VERSION "dbc-export 1 2026.26.6.5"

NS_ :

BS_:

BU_: ADSP APSB CMP DAS EPAS3P GTW OCS1P PTC RCM TCU TCU2 TRCM UDS UI UIS VCLEFT

BO_ 1297 RCM_alertLog: 8 RCM
 SG_ RCM_alertID M : 0|10@1+ (1,0) [0|1023] "" Vector__XXX
 SG_ RCM_a117_eventDriveOrientation m117 : 14|1@1+ (1,0) [0|1] "" Vector__XXX
 SG_ RCM_a117_imuZaccelChnlMonitTmp m117 : 16|1@1+ (1,0) [0|1] "" Vector__XXX
 SG_ RCM_a117_imuZaccelChnlMonitPerm m117 : 17|1@1+ (1,0) [0|1] "" Vector__XXX
 SG_ RCM_a117_eventIDFsignal m117 : 25|1@1+ (1,0) [0|1] "" Vector__XXX
 SG_ RCM_a117_eventFrontLeftSeatbelt m117 : 26|1@1+ (1,0) [0|1] "" Vector__XXX
 SG_ RCM_a117_eventFrontRightSeatbelt m117 : 27|1@1+ (1,0) [0|1] "" Vector__XXX
 SG_ RCM_a117_eventVehicleSpeed m117 : 28|12@1+ (0.08,-40) [-40|287.6] "kph" Vector__XXX
 SG_ RCM_a117_eventSteeringAngle m117 : 45|14@0+ (0.1,-819.2) [-819.2|819.1] "deg" Vector__XXX
 SG_ RCM_a117_eventDriverBrakeApply m117 : 46|2@1+ (1,0) [0|2] "" Vector__XXX
 SG_ RCM_a117_eventAccelPedalPos m117 : 56|8@1+ (0.4,0) [0|101.6] "%" Vector__XXX
 SG_ RCM_a118_eventArmStatus m118 : 11|1@1+ (1,0) [0|1] "" Vector__XXX
 SG_ RCM_a118_eventFactoryMode m118 : 12|1@1+ (1,0) [0|1] "" Vector__XXX
 SG_ RCM_a118_eventDiagEnabled m118 : 13|1@1+ (1,0) [0|1] "" Vector__XXX
 SG_ RCM_a118_eventDriveOrientation m118 : 14|1@1+ (1,0) [0|1] "" Vector__XXX
 SG_ RCM_a118_imuInPlaneSnsrMonitTmp m118 : 16|1@1+ (1,0) [0|1] "" Vector__XXX
 SG_ RCM_a118_imuInPlaneSnsrMonitPerm m118 : 17|1@1+ (1,0) [0|1] "" Vector__XXX
 SG_ RCM_a118_eventIDFsignal m118 : 25|1@1+ (1,0) [0|1] "" Vector__XXX
 SG_ RCM_a118_eventFrontLeftSeatbelt m118 : 26|1@1+ (1,0) [0|1] "" Vector__XXX
 SG_ RCM_a118_eventFrontRightSeatbelt m118 : 27|1@1+ (1,0) [0|1] "" Vector__XXX
 SG_ RCM_a118_eventVehicleSpeed m118 : 28|12@1+ (0.08,-40) [-40|287.6] "kph" Vector__XXX
 SG_ RCM_a118_eventSteeringAngle m118 : 45|14@0+ (0.1,-819.2) [-819.2|819.1] "deg" Vector__XXX
 SG_ RCM_a118_eventDriverBrakeApply m118 : 46|2@1+ (1,0) [0|2] "" Vector__XXX
 SG_ RCM_a118_eventAccelPedalPos m118 : 56|8@1+ (0.4,0) [0|101.6] "%" Vector__XXX

BO_ 881 RCM_alertMatrix: 8 RCM
 SG_ RCM_matrixIndex M : 0|4@1+ (1,0) [0|15] "" Vector__XXX
 SG_ RCM_a000_crashDetected m0 : 4|1@1+ (1,0) [0|1] "" Vector__XXX
 SG_ RCM_a001_nearDeploy m0 : 5|1@1+ (1,0) [0|1] "" Vector__XXX
 SG_ RCM_a002_airbagsNotArmed m0 : 6|1@1+ (1,0) [0|1] "" Vector__XXX
 SG_ RCM_a003_warningIndicator m0 : 7|1@1+ (1,0) [0|1] "" Vector__XXX
 SG_ RCM_a004_internalFault m0 : 8|1@1+ (1,0) [0|1] "" Vector__XXX
 SG_ RCM_a005_crcError m0 : 9|1@1+ (1,0) [0|1] "" Vector__XXX
 SG_ RCM_a006_batteryVoltageRange m0 : 10|1@1+ (1,0) [0|1] "" Vector__XXX
 SG_ RCM_a007_powerSupplyExternal m0 : 11|1@1+ (1,0) [0|1] "" Vector__XXX
 SG_ RCM_a008_powerSupplyInternal m0 : 12|1@1+ (1,0) [0|1] "" Vector__XXX
 SG_ RCM_a009_reprogramLimit m0 : 13|1@1+ (1,0) [0|1] "" Vector__XXX
 SG_ RCM_a010_scmDisabled m0 : 14|1@1+ (1,0) [0|1] "" Vector__XXX
 SG_ RCM_a011_eepromDataLocked m0 : 15|1@1+ (1,0) [0|1] "" Vector__XXX
 SG_ RCM_a012_vinStorage m0 : 16|1@1+ (1,0) [0|1] "" Vector__XXX
 SG_ RCM_a013_driverOrientation m0 : 17|1@1+ (1,0) [0|1] "" Vector__XXX
 SG_ RCM_a014_driverABStage1 m0 : 18|1@1+ (1,0) [0|1] "" Vector__XXX
 SG_ RCM_a015_driverABStage2 m0 : 19|1@1+ (1,0) [0|1] "" Vector__XXX
 SG_ RCM_a016_passABStage1 m0 : 20|1@1+ (1,0) [0|1] "" Vector__XXX
 SG_ RCM_a017_passABStage2 m0 : 21|1@1+ (1,0) [0|1] "" Vector__XXX
 SG_ RCM_a018_passengerActiveVent m0 : 22|1@1+ (1,0) [0|1] "" Vector__XXX
 SG_ RCM_a019_pretenShldrFrontLeft m0 : 23|1@1+ (1,0) [0|1] "" Vector__XXX
 SG_ RCM_a020_pretenShldFrontRight m0 : 24|1@1+ (1,0) [0|1] "" Vector__XXX
 SG_ RCM_a021_pretenLapFrontLeft m0 : 25|1@1+ (1,0) [0|1] "" Vector__XXX
 SG_ RCM_a022_pretenLapFrontRight m0 : 26|1@1+ (1,0) [0|1] "" Vector__XXX
 SG_ RCM_a023_loadLimiterLeftSide m0 : 27|1@1+ (1,0) [0|1] "" Vector__XXX
 SG_ RCM_a024_loadLimiterRightSide m0 : 28|1@1+ (1,0) [0|1] "" Vector__XXX
 SG_ RCM_a025_kneeABDriver m0 : 29|1@1+ (1,0) [0|1] "" Vector__XXX
 SG_ RCM_a026_kneeABFrontPassenger m0 : 30|1@1+ (1,0) [0|1] "" Vector__XXX
 SG_ RCM_a027_sideAB1stRowLeft m0 : 31|1@1+ (1,0) [0|1] "" Vector__XXX
 SG_ RCM_a028_sideAB1stRowRight m0 : 32|1@1+ (1,0) [0|1] "" Vector__XXX
 SG_ RCM_a029_driverABActiveVent m0 : 33|1@1+ (1,0) [0|1] "" Vector__XXX
 SG_ RCM_a030_farSideInboardAirbag m0 : 34|1@1+ (1,0) [0|1] "" Vector__XXX
 SG_ RCM_a031_frontCenterAirbag m0 : 35|1@1+ (1,0) [0|1] "" Vector__XXX
 SG_ RCM_a032_curtainABLeft m0 : 36|1@1+ (1,0) [0|1] "" Vector__XXX
 SG_ RCM_a033_curtainABRight m0 : 37|1@1+ (1,0) [0|1] "" Vector__XXX
 SG_ RCM_a034_preten2ndRowLeft m0 : 38|1@1+ (1,0) [0|1] "" Vector__XXX
 SG_ RCM_a035_preten2ndRowRight m0 : 39|1@1+ (1,0) [0|1] "" Vector__XXX
 SG_ RCM_a036_curAB2ndRowLeft m0 : 40|1@1+ (1,0) [0|1] "" Vector__XXX
 SG_ RCM_a037_curAB2ndRowRight m0 : 41|1@1+ (1,0) [0|1] "" Vector__XXX
 SG_ RCM_a038_unusedA m0 : 42|1@1+ (1,0) [0|1] "" Vector__XXX
 SG_ RCM_a039_unusedB m0 : 43|1@1+ (1,0) [0|1] "" Vector__XXX
 SG_ RCM_a040_hoodActuatorRight m0 : 44|1@1+ (1,0) [0|1] "" Vector__XXX
 SG_ RCM_a041_hoodActuatorLeft m0 : 45|1@1+ (1,0) [0|1] "" Vector__XXX
 SG_ RCM_a042_ens1Line m0 : 46|1@1+ (1,0) [0|1] "" Vector__XXX
 SG_ RCM_a043_ens2Line m0 : 47|1@1+ (1,0) [0|1] "" Vector__XXX
 SG_ RCM_a044_upFrontSensorLeft m0 : 48|1@1+ (1,0) [0|1] "" Vector__XXX
 SG_ RCM_a045_upFrontSensorRight m0 : 49|1@1+ (1,0) [0|1] "" Vector__XXX
 SG_ RCM_a046_sideAccelBPillarLeft m0 : 50|1@1+ (1,0) [0|1] "" Vector__XXX
 SG_ RCM_a047_sideAccelBPillarRight m0 : 51|1@1+ (1,0) [0|1] "" Vector__XXX
 SG_ RCM_a048_sideAccelCPillarLeft m0 : 52|1@1+ (1,0) [0|1] "" Vector__XXX
 SG_ RCM_a049_sideAccelCPillarRight m0 : 53|1@1+ (1,0) [0|1] "" Vector__XXX
 SG_ RCM_a050_upFrontSensorCenter m0 : 54|1@1+ (1,0) [0|1] "" Vector__XXX
 SG_ RCM_a051_pressureFrontLftDoor m0 : 55|1@1+ (1,0) [0|1] "" Vector__XXX
 SG_ RCM_a052_pressureFrontRtDoor m0 : 56|1@1+ (1,0) [0|1] "" Vector__XXX
 SG_ RCM_a053_pressurePedProLeft m0 : 57|1@1+ (1,0) [0|1] "" Vector__XXX
 SG_ RCM_a054_pressurePedProRight m0 : 58|1@1+ (1,0) [0|1] "" Vector__XXX
 SG_ RCM_a055_inertialMeasurement m0 : 59|1@1+ (1,0) [0|1] "" Vector__XXX
 SG_ RCM_a056_passengerFrontOCS m0 : 60|1@1+ (1,0) [0|1] "" Vector__XXX
 SG_ RCM_a057_driverOCS m0 : 61|1@1+ (1,0) [0|1] "" Vector__XXX
 SG_ RCM_a058_buckle1stRowLeft m0 : 62|1@1+ (1,0) [0|1] "" Vector__XXX
 SG_ RCM_a059_buckle1stRowRight m0 : 63|1@1+ (1,0) [0|1] "" Vector__XXX
 SG_ RCM_a060_stpsLeft m1 : 4|1@1+ (1,0) [0|1] "" Vector__XXX
 SG_ RCM_a061_stpsRight m1 : 5|1@1+ (1,0) [0|1] "" Vector__XXX
 SG_ RCM_a062_alrSwitch m1 : 6|1@1+ (1,0) [0|1] "" Vector__XXX
 SG_ RCM_a063_sbsw2ndRowRight m1 : 7|1@1+ (1,0) [0|1] "" Vector__XXX
 SG_ RCM_a064_hardwareCodingPin1 m1 : 8|1@1+ (1,0) [0|1] "" Vector__XXX
 SG_ RCM_a065_driverOrientConfigPin m1 : 9|1@1+ (1,0) [0|1] "" Vector__XXX
 SG_ RCM_a066_seatBackSw2ndRowLeft m1 : 10|1@1+ (1,0) [0|1] "" Vector__XXX
 SG_ RCM_a067_comCANInitFailure m1 : 11|1@1+ (1,0) [0|1] "" Vector__XXX
 SG_ RCM_a068_comChassisBusOff m1 : 12|1@1+ (1,0) [0|1] "" Vector__XXX
 SG_ RCM_a069_comCHCANPH7 m1 : 13|1@1+ (1,0) [0|1] "" Vector__XXX
 SG_ RCM_a070_comCHCANPH8 m1 : 14|1@1+ (1,0) [0|1] "" Vector__XXX
 SG_ RCM_a071_comCHCANPH9 m1 : 15|1@1+ (1,0) [0|1] "" Vector__XXX
 SG_ RCM_a072_comUnused m1 : 16|1@1+ (1,0) [0|1] "" Vector__XXX
 SG_ RCM_a073_comCHCANPH4 m1 : 17|1@1+ (1,0) [0|1] "" Vector__XXX
 SG_ RCM_a074_comCHCANPH5 m1 : 18|1@1+ (1,0) [0|1] "" Vector__XXX
 SG_ RCM_a075_comCHCANPH6 m1 : 19|1@1+ (1,0) [0|1] "" Vector__XXX
 SG_ RCM_a076_comEPBLStatus m1 : 20|1@1+ (1,0) [0|1] "" Vector__XXX
 SG_ RCM_a077_comEPBRStatus m1 : 21|1@1+ (1,0) [0|1] "" Vector__XXX
 SG_ RCM_a078_comOCS1PStatus m1 : 22|1@1+ (1,0) [0|1] "" Vector__XXX
 SG_ RCM_a079_comOCS1DStatus m1 : 23|1@1+ (1,0) [0|1] "" Vector__XXX
 SG_ RCM_a080_comGTWACS m1 : 24|1@1+ (1,0) [0|1] "" Vector__XXX
 SG_ RCM_a081_comVCFRONTLVPwr m1 : 25|1@1+ (1,0) [0|1] "" Vector__XXX
 SG_ RCM_a082_comUIodo m1 : 26|1@1+ (1,0) [0|1] "" Vector__XXX
 SG_ RCM_a083_comGTWCarState m1 : 27|1@1+ (1,0) [0|1] "" Vector__XXX
 SG_ RCM_a084_comTPMSStatus m1 : 28|1@1+ (1,0) [0|1] "" Vector__XXX
 SG_ RCM_a085_comGTWCarConfig m1 : 29|1@1+ (1,0) [0|1] "" Vector__XXX
 SG_ RCM_a086_comVINMIA m1 : 30|1@1+ (1,0) [0|1] "" Vector__XXX
 SG_ RCM_a087_comCANSilent m1 : 31|1@1+ (1,0) [0|1] "" Vector__XXX
 SG_ RCM_a088_comCHCANPH2 m1 : 32|1@1+ (1,0) [0|1] "" Vector__XXX
 SG_ RCM_a089_comCHCANPH3 m1 : 33|1@1+ (1,0) [0|1] "" Vector__XXX
 SG_ RCM_a090_comPartyBusOff m1 : 34|1@1+ (1,0) [0|1] "" Vector__XXX
 SG_ RCM_a091_comEPAS3PsysStatus m1 : 35|1@1+ (1,0) [0|1] "" Vector__XXX
 SG_ RCM_a092_comDASISF m1 : 36|1@1+ (1,0) [0|1] "" Vector__XXX
 SG_ RCM_a093_comVCLEFTStatus m1 : 37|1@1+ (1,0) [0|1] "" Vector__XXX
 SG_ RCM_a094_comVCRIGHTStatus m1 : 38|1@1+ (1,0) [0|1] "" Vector__XXX
 SG_ RCM_a095_comESPstatus m1 : 39|1@1+ (1,0) [0|1] "" Vector__XXX
 SG_ RCM_a096_comESPwheelSpeeds m1 : 40|1@1+ (1,0) [0|1] "" Vector__XXX
 SG_ RCM_a097_comDIspeed m1 : 41|1@1+ (1,0) [0|1] "" Vector__XXX
 SG_ RCM_a098_comDIchassisControl m1 : 42|1@1+ (1,0) [0|1] "" Vector__XXX
 SG_ RCM_a099_comDItorque m1 : 43|1@1+ (1,0) [0|1] "" Vector__XXX
 SG_ RCM_a100_comDIsystemStatus m1 : 44|1@1+ (1,0) [0|1] "" Vector__XXX
 SG_ RCM_a101_idfSystem m1 : 45|1@1+ (1,0) [0|1] "" Vector__XXX
 SG_ RCM_a102_imuYawR8OffstCompLim m1 : 46|1@1+ (1,0) [0|1] "" Vector__XXX
 SG_ RCM_a103_imuPtchR8OffstCompLim m1 : 47|1@1+ (1,0) [0|1] "" Vector__XXX
 SG_ RCM_a104_imuRollR8OffstCompLim m1 : 48|1@1+ (1,0) [0|1] "" Vector__XXX
 SG_ RCM_a105_imuLongAccOffstCompLim m1 : 49|1@1+ (1,0) [0|1] "" Vector__XXX
 SG_ RCM_a106_imuLatAccOffstCompLim m1 : 50|1@1+ (1,0) [0|1] "" Vector__XXX
 SG_ RCM_a107_imuVertAccOffstCompLim m1 : 51|1@1+ (1,0) [0|1] "" Vector__XXX
 SG_ RCM_a108_crashAlgoWakeup m1 : 52|1@1+ (1,0) [0|1] "" Vector__XXX
 SG_ RCM_a109_abuseImmunity m1 : 53|1@1+ (1,0) [0|1] "" Vector__XXX
 SG_ RCM_a110_factoryMode m1 : 54|1@1+ (1,0) [0|1] "" Vector__XXX
 SG_ RCM_a111_diagnosticsEnabled m1 : 55|1@1+ (1,0) [0|1] "" Vector__XXX
 SG_ RCM_a112_imuYawRate m1 : 56|1@1+ (1,0) [0|1] "" Vector__XXX
 SG_ RCM_a113_imuPitchRate m1 : 57|1@1+ (1,0) [0|1] "" Vector__XXX
 SG_ RCM_a114_imuRollRate m1 : 58|1@1+ (1,0) [0|1] "" Vector__XXX
 SG_ RCM_a115_imuLinearAcceleration m1 : 59|1@1+ (1,0) [0|1] "" Vector__XXX
 SG_ RCM_a116_imuLateralAcceleration m1 : 60|1@1+ (1,0) [0|1] "" Vector__XXX
 SG_ RCM_a117_imuVerticalAcceleration m1 : 61|1@1+ (1,0) [0|1] "" Vector__XXX
 SG_ RCM_a118_imuInPlaneAcceleration m1 : 62|1@1+ (1,0) [0|1] "" Vector__XXX

BO_ 1415 TCU2_SleepConfig: 1 TCU2
 SG_ TCU2_tc10Version : 0|2@1+ (1,0) [1|3] "" Vector__XXX

BO_ 1413 TCU2_alertLog: 8 TCU2
 SG_ TCU2_alertID M : 0|5@1+ (1,0) [0|31] "" Vector__XXX
 SG_ TCU2_alertState : 15|1@1+ (1,0) [0|1] "" Vector__XXX
 SG_ TCU2_w001_FailCode m1 : 16|32@1+ (1,0) [0|4294967295] "" Vector__XXX
 SG_ TCU2_w002_RejCause m2 : 16|32@1+ (1,0) [0|4294967295] "" Vector__XXX
 SG_ TCU2_w003_CallFailCode m3 : 16|32@1+ (1,0) [0|4294967295] "" Vector__XXX
 SG_ TCU2_w004_MSDFailCode m4 : 16|32@1+ (1,0) [0|4294967295] "" Vector__XXX
 SG_ TCU2_w006_Count m6 : 16|32@1+ (1,0) [0|4294967295] "" Vector__XXX
 SG_ TCU2_w007_Count m7 : 16|32@1+ (1,0) [0|4294967295] "" Vector__XXX
 SG_ TCU2_w009_CrashCode m9 : 16|32@1+ (1,0) [0|4294967295] "" Vector__XXX
 SG_ TCU2_w012_DataRAT m12 : 16|4@1+ (1,0) [0|15] "" Vector__XXX
 SG_ TCU2_w012_RSRP m12 : 20|8@1- (1,0) [-128|127] "dBm" Vector__XXX
 SG_ TCU2_w012_RSRQ m12 : 28|7@1- (1,0) [-64|63] "dBm" Vector__XXX
 SG_ TCU2_w012_MNC m12 : 45|10@1+ (1,0) [0|1023] "" Vector__XXX
 SG_ TCU2_w012_AvgQueueUsage m12 : 55|7@1+ (1,0) [0|127] "%" Vector__XXX
 SG_ TCU2_w012_NSAAvailable m12 : 62|2@1+ (1,0) [0|3] "" Vector__XXX
 SG_ TCU2_w013_DataRAT m13 : 16|4@1+ (1,0) [0|15] "" Vector__XXX
 SG_ TCU2_w013_RSRP m13 : 20|8@1- (1,0) [-128|127] "dBm" Vector__XXX
 SG_ TCU2_w013_RSRQ m13 : 28|7@1- (1,0) [-64|63] "dBm" Vector__XXX
 SG_ TCU2_w013_MNC m13 : 45|10@1+ (1,0) [0|1023] "" Vector__XXX
 SG_ TCU2_w013_AvgQueueUsage m13 : 55|7@1+ (1,0) [0|127] "%" Vector__XXX
 SG_ TCU2_w013_NSAAvailable m13 : 62|2@1+ (1,0) [0|3] "" Vector__XXX
 SG_ TCU2_w014_Reason m14 : 16|32@1- (1,0) [-2147483648|2147483647] "" Vector__XXX

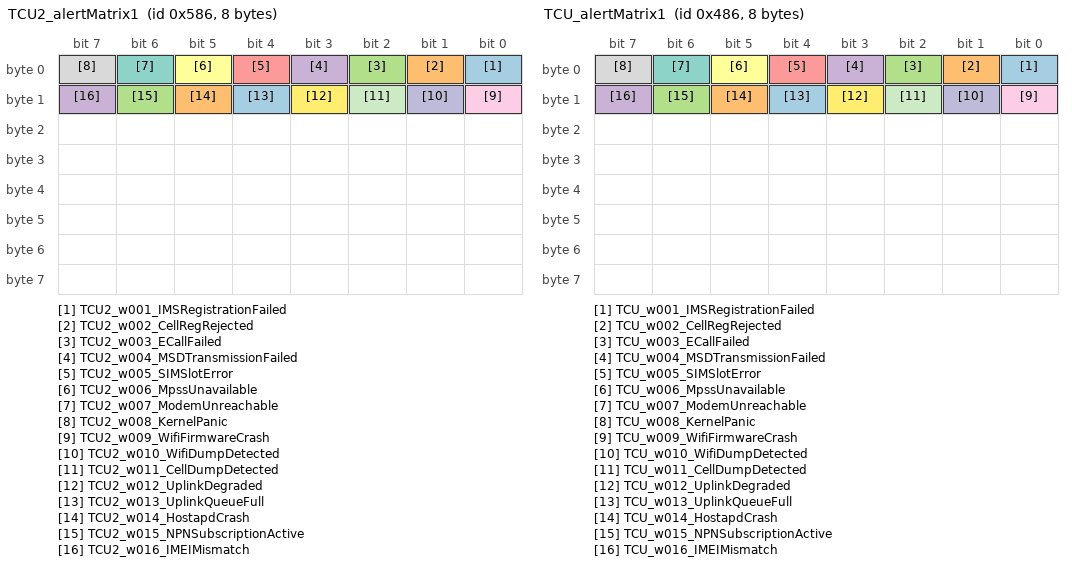
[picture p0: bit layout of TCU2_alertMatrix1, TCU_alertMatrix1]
BO_ 1414 TCU2_alertMatrix1: 8 TCU2
 SG_ TCU2_w001_IMSRegistrationFailed : 0|1@1+ (1,0) [0|1] "" Vector__XXX
 SG_ TCU2_w002_CellRegRejected : 1|1@1+ (1,0) [0|1] "" Vector__XXX
 SG_ TCU2_w003_ECallFailed : 2|1@1+ (1,0) [0|1] "" Vector__XXX
 SG_ TCU2_w004_MSDTransmissionFailed : 3|1@1+ (1,0) [0|1] "" Vector__XXX
 SG_ TCU2_w005_SIMSlotError : 4|1@1+ (1,0) [0|1] "" Vector__XXX
 SG_ TCU2_w006_MpssUnavailable : 5|1@1+ (1,0) [0|1] "" Vector__XXX
 SG_ TCU2_w007_ModemUnreachable : 6|1@1+ (1,0) [0|1] "" Vector__XXX
 SG_ TCU2_w008_KernelPanic : 7|1@1+ (1,0) [0|1] "" Vector__XXX
 SG_ TCU2_w009_WifiFirmwareCrash : 8|1@1+ (1,0) [0|1] "" Vector__XXX
 SG_ TCU2_w010_WifiDumpDetected : 9|1@1+ (1,0) [0|1] "" Vector__XXX
 SG_ TCU2_w011_CellDumpDetected : 10|1@1+ (1,0) [0|1] "" Vector__XXX
 SG_ TCU2_w012_UplinkDegraded : 11|1@1+ (1,0) [0|1] "" Vector__XXX
 SG_ TCU2_w013_UplinkQueueFull : 12|1@1+ (1,0) [0|1] "" Vector__XXX
 SG_ TCU2_w014_HostapdCrash : 13|1@1+ (1,0) [0|1] "" Vector__XXX
 SG_ TCU2_w015_NPNSubscriptionActive : 14|1@1+ (1,0) [0|1] "" Vector__XXX
 SG_ TCU2_w016_IMEIMismatch : 15|1@1+ (1,0) [0|1] "" Vector__XXX

BO_ 1412 TCU2_log: 8 TCU2
 SG_ TCU2_logMux M : 0|32@1+ (1,0) [0|4294967295] "" Vector__XXX
 SG_ TCU2_cpuTemp m0 : 32|32@1+ (1,0) [0|4294967295] "C" Vector__XXX
 SG_ TCU2_cpuUsage m1 : 32|32@1+ (1,0) [0|4294967295] "%" Vector__XXX
 SG_ TCU2_mdmCoreTemperature m2 : 32|32@1+ (1,0) [0|4294967295] "C" Vector__XXX
 SG_ TCU2_availableMemory m3 : 32|32@1+ (1,0) [0|4294967295] "KB" Vector__XXX
 SG_ TCU2_pwm m4 : 32|32@1+ (1,0) [0|4294967295] "" Vector__XXX
 SG_ TCU2_pwmcap m5 : 32|32@1+ (1,0) [0|4294967295] "" Vector__XXX
 SG_ TCU2_totalResumes m6 : 32|32@1+ (1,0) [0|4294967295] "" Vector__XXX
 SG_ TCU2_mdmUplinkQueueSize m7 : 32|32@1+ (1,0) [0|4294967295] "bytes" Vector__XXX
 SG_ TCU2_mdmRSRP m8 : 32|32@1- (1,0) [-2147483648|2147483647] "dBm" Vector__XXX
 SG_ TCU2_mdmSINR m9 : 32|32@1- (1,0) [-2147483648|2147483647] "dBm" Vector__XXX
 SG_ TCU2_mdmUplinkAllowedRate m10 : 32|32@1+ (1,0) [0|4294967295] "Kbps" Vector__XXX
 SG_ TCU2_mdmUplinkAvgRate m11 : 32|32@1+ (1,0) [0|4294967295] "Kbps" Vector__XXX
 SG_ TCU2_mdmServiceState m12 : 32|32@1+ (1,0) [0|4294967295] "" Vector__XXX
 SG_ TCU2_mdmIMSStatus m13 : 32|32@1+ (1,0) [0|4294967295] "" Vector__XXX
 SG_ TCU2_mdmSIMStatus m14 : 32|32@1+ (1,0) [0|4294967295] "" Vector__XXX
 SG_ TCU2_mdmBusyActive m15 : 32|32@1+ (1,0) [0|4294967294] "" Vector__XXX
 SG_ TCU2_modemUptime m16 : 32|32@1+ (1,0) [0|4294967295] "" Vector__XXX
 SG_ TCU2_mdmDataRat m17 : 32|3@1+ (1,0) [0|7] "" Vector__XXX
 SG_ TCU2_mdmDataCallStatus m18 : 32|3@1+ (1,0) [0|7] "" Vector__XXX
 SG_ TCU2_mdmNSAAvailable m19 : 32|2@1+ (1,0) [0|3] "" Vector__XXX
 SG_ TCU2_mdmPCIID m20 : 32|32@1+ (1,0) [0|4294967295] "" Vector__XXX
 SG_ TCU2_mdmMnc m21 : 32|32@1+ (1,0) [0|4294967295] "" Vector__XXX
 SG_ TCU2_mdmMcc m22 : 32|32@1+ (1,0) [0|4294967295] "" Vector__XXX
 SG_ TCU2_mdmTxKiloBytes m23 : 32|32@1+ (1,0) [0|4294967295] "KB" Vector__XXX
 SG_ TCU2_mdmDataCallTermReason m24 : 32|32@1+ (1,0) [0|4294967295] "" Vector__XXX
 SG_ TCU2_mdmDataCallTermCode m25 : 32|32@1+ (1,0) [0|4294967295] "" Vector__XXX
 SG_ TCU2_cellularSMState m26 : 32|32@1+ (1,0) [0|4294967295] "" Vector__XXX
 SG_ TCU2_tcuSMState m27 : 32|32@1+ (1,0) [0|4294967295] "" Vector__XXX
 SG_ TCU2_checkInternetFailCount m28 : 32|32@1+ (1,0) [0|4294967295] "" Vector__XXX
 SG_ TCU2_mdmBand m29 : 32|32@1+ (1,0) [0|4294967295] "" Vector__XXX
 SG_ TCU2_wakeSource m30 : 32|2@1+ (1,0) [0|3] "" Vector__XXX

BO_ 1159 TCU_SleepConfig: 1 TCU
 SG_ TCU_tc10Version : 0|2@1+ (1,0) [1|3] "" Vector__XXX

BO_ 1157 TCU_alertLog: 8 TCU
 SG_ TCU_alertID M : 0|5@1+ (1,0) [0|31] "" Vector__XXX
 SG_ TCU_alertState : 15|1@1+ (1,0) [0|1] "" Vector__XXX
 SG_ TCU_w001_FailCode m1 : 16|32@1+ (1,0) [0|4294967295] "" Vector__XXX
 SG_ TCU_w002_RejCause m2 : 16|32@1+ (1,0) [0|4294967295] "" Vector__XXX
 SG_ TCU_w003_CallFailCode m3 : 16|32@1+ (1,0) [0|4294967295] "" Vector__XXX
 SG_ TCU_w004_MSDFailCode m4 : 16|32@1+ (1,0) [0|4294967295] "" Vector__XXX
 SG_ TCU_w006_Count m6 : 16|32@1+ (1,0) [0|4294967295] "" Vector__XXX
 SG_ TCU_w007_Count m7 : 16|32@1+ (1,0) [0|4294967295] "" Vector__XXX
 SG_ TCU_w009_CrashCode m9 : 16|32@1+ (1,0) [0|4294967295] "" Vector__XXX
 SG_ TCU_w012_DataRAT m12 : 16|4@1+ (1,0) [0|15] "" Vector__XXX
 SG_ TCU_w012_RSRP m12 : 20|8@1- (1,0) [-128|127] "dBm" Vector__XXX
 SG_ TCU_w012_RSRQ m12 : 28|7@1- (1,0) [-64|63] "dBm" Vector__XXX
 SG_ TCU_w012_MNC m12 : 45|10@1+ (1,0) [0|1023] "" Vector__XXX
 SG_ TCU_w012_AvgQueueUsage m12 : 55|7@1+ (1,0) [0|127] "%" Vector__XXX
 SG_ TCU_w012_NSAAvailable m12 : 62|2@1+ (1,0) [0|3] "" Vector__XXX
 SG_ TCU_w013_DataRAT m13 : 16|4@1+ (1,0) [0|15] "" Vector__XXX
 SG_ TCU_w013_RSRP m13 : 20|8@1- (1,0) [-128|127] "dBm" Vector__XXX
 SG_ TCU_w013_RSRQ m13 : 28|7@1- (1,0) [-64|63] "dBm" Vector__XXX
 SG_ TCU_w013_MNC m13 : 45|10@1+ (1,0) [0|1023] "" Vector__XXX
 SG_ TCU_w013_AvgQueueUsage m13 : 55|7@1+ (1,0) [0|127] "%" Vector__XXX
 SG_ TCU_w013_NSAAvailable m13 : 62|2@1+ (1,0) [0|3] "" Vector__XXX
 SG_ TCU_w014_Reason m14 : 16|32@1- (1,0) [-2147483648|2147483647] "" Vector__XXX

BO_ 1158 TCU_alertMatrix1: 8 TCU
 SG_ TCU_w001_IMSRegistrationFailed : 0|1@1+ (1,0) [0|1] "" Vector__XXX
 SG_ TCU_w002_CellRegRejected : 1|1@1+ (1,0) [0|1] "" Vector__XXX
 SG_ TCU_w003_ECallFailed : 2|1@1+ (1,0) [0|1] "" Vector__XXX
 SG_ TCU_w004_MSDTransmissionFailed : 3|1@1+ (1,0) [0|1] "" Vector__XXX
 SG_ TCU_w005_SIMSlotError : 4|1@1+ (1,0) [0|1] "" Vector__XXX
 SG_ TCU_w006_MpssUnavailable : 5|1@1+ (1,0) [0|1] "" Vector__XXX
 SG_ TCU_w007_ModemUnreachable : 6|1@1+ (1,0) [0|1] "" Vector__XXX
 SG_ TCU_w008_KernelPanic : 7|1@1+ (1,0) [0|1] "" Vector__XXX
 SG_ TCU_w009_WifiFirmwareCrash : 8|1@1+ (1,0) [0|1] "" Vector__XXX
 SG_ TCU_w010_WifiDumpDetected : 9|1@1+ (1,0) [0|1] "" Vector__XXX
 SG_ TCU_w011_CellDumpDetected : 10|1@1+ (1,0) [0|1] "" Vector__XXX
 SG_ TCU_w012_UplinkDegraded : 11|1@1+ (1,0) [0|1] "" Vector__XXX
 SG_ TCU_w013_UplinkQueueFull : 12|1@1+ (1,0) [0|1] "" Vector__XXX
 SG_ TCU_w014_HostapdCrash : 13|1@1+ (1,0) [0|1] "" Vector__XXX
 SG_ TCU_w015_NPNSubscriptionActive : 14|1@1+ (1,0) [0|1] "" Vector__XXX
 SG_ TCU_w016_IMEIMismatch : 15|1@1+ (1,0) [0|1] "" Vector__XXX

BO_ 1155 TCU_log: 8 TCU
 SG_ TCU_logMux M : 0|32@1+ (1,0) [0|4294967295] "" Vector__XXX
 SG_ TCU_cpuTemp m0 : 32|32@1+ (1,0) [0|4294967295] "C" Vector__XXX
 SG_ TCU_cpuUsage m1 : 32|32@1+ (1,0) [0|4294967295] "%" Vector__XXX
 SG_ TCU_mdmCoreTemperature m2 : 32|32@1+ (1,0) [0|4294967295] "C" Vector__XXX
 SG_ TCU_availableMemory m3 : 32|32@1+ (1,0) [0|4294967295] "KB" Vector__XXX
 SG_ TCU_pwm m4 : 32|32@1+ (1,0) [0|4294967295] "" Vector__XXX
 SG_ TCU_pwmcap m5 : 32|32@1+ (1,0) [0|4294967295] "" Vector__XXX
 SG_ TCU_totalResumes m6 : 32|32@1+ (1,0) [0|4294967295] "" Vector__XXX
 SG_ TCU_mdmUplinkQueueSize m7 : 32|32@1+ (1,0) [0|4294967295] "bytes" Vector__XXX
 SG_ TCU_mdmRSRP m8 : 32|32@1- (1,0) [-2147483648|2147483647] "dBm" Vector__XXX
 SG_ TCU_mdmSINR m9 : 32|32@1- (1,0) [-2147483648|2147483647] "dBm" Vector__XXX
 SG_ TCU_mdmUplinkAllowedRate m10 : 32|32@1+ (1,0) [0|4294967295] "Kbps" Vector__XXX
 SG_ TCU_mdmUplinkAvgRate m11 : 32|32@1+ (1,0) [0|4294967295] "Kbps" Vector__XXX
 SG_ TCU_mdmServiceState m12 : 32|32@1+ (1,0) [0|4294967295] "" Vector__XXX
 SG_ TCU_mdmIMSStatus m13 : 32|32@1+ (1,0) [0|4294967295] "" Vector__XXX
 SG_ TCU_mdmSIMStatus m14 : 32|32@1+ (1,0) [0|4294967295] "" Vector__XXX
 SG_ TCU_mdmBusyActive m15 : 32|32@1+ (1,0) [0|4294967294] "" Vector__XXX
 SG_ TCU_modemUptime m16 : 32|32@1+ (1,0) [0|4294967295] "" Vector__XXX
 SG_ TCU_mdmDataRat m17 : 32|3@1+ (1,0) [0|7] "" Vector__XXX
 SG_ TCU_mdmDataCallStatus m18 : 32|3@1+ (1,0) [0|7] "" Vector__XXX
 SG_ TCU_mdmNSAAvailable m19 : 32|2@1+ (1,0) [0|3] "" Vector__XXX
 SG_ TCU_mdmPCIID m20 : 32|32@1+ (1,0) [0|4294967295] "" Vector__XXX
 SG_ TCU_mdmMnc m21 : 32|32@1+ (1,0) [0|4294967295] "" Vector__XXX
 SG_ TCU_mdmMcc m22 : 32|32@1+ (1,0) [0|4294967295] "" Vector__XXX
 SG_ TCU_mdmTxKiloBytes m23 : 32|32@1+ (1,0) [0|4294967295] "KB" Vector__XXX
 SG_ TCU_mdmDataCallTermReason m24 : 32|32@1+ (1,0) [0|4294967295] "" Vector__XXX
 SG_ TCU_mdmDataCallTermCode m25 : 32|32@1+ (1,0) [0|4294967295] "" Vector__XXX
 SG_ TCU_cellularSMState m26 : 32|32@1+ (1,0) [0|4294967295] "" Vector__XXX
 SG_ TCU_tcuSMState m27 : 32|32@1+ (1,0) [0|4294967295] "" Vector__XXX
 SG_ TCU_checkInternetFailCount m28 : 32|32@1+ (1,0) [0|4294967295] "" Vector__XXX
 SG_ TCU_mdmBand m29 : 32|32@1+ (1,0) [0|4294967295] "" Vector__XXX
 SG_ TCU_wakeSource m30 : 32|2@1+ (1,0) [0|3] "" Vector__XXX

BO_ 1298 TRCM_alertLog: 8 TRCM
 SG_ TRCM_alertID M : 0|10@1+ (1,0) [0|1023] "" Vector__XXX
 SG_ TRCM_alertState : 15|1@1+ (1,0) [0|1] "" Vector__XXX
 SG_ TRCM_a015_NVMMMemOverflow m15 : 16|1@1+ (1,0) [0|1] "" Vector__XXX
 SG_ TRCM_a015_NVMMFilesystemError m15 : 17|1@1+ (1,0) [0|1] "" Vector__XXX
 SG_ TRCM_a015_NVMMRecordIDError m15 : 18|1@1+ (1,0) [0|1] "" Vector__XXX
 SG_ TRCM_a017_tempData m17 : 16|16@1- (0.06897,25) [-2235.00896|2284.93999] "degC" Vector__XXX
 SG_ TRCM_a018_tempData m18 : 16|16@1- (0.06897,25) [-2235.00896|2284.93999] "degC" Vector__XXX
 SG_ TRCM_a035_eventArmStatus m35 : 25|1@1+ (1,0) [0|1] "" Vector__XXX
 SG_ TRCM_a035_eventFrontLeftSeatbelt m35 : 30|1@1+ (1,0) [0|1] "" Vector__XXX
 SG_ TRCM_a035_eventFrontRightSeatbel m35 : 31|1@1+ (1,0) [0|1] "" Vector__XXX
 SG_ TRCM_a035_eventVehicleSpeed m35 : 32|12@1+ (0.08,-40) [-40|287.6] "kph" Vector__XXX
 SG_ TRCM_a035_eventDriverBrakeApply m35 : 48|2@1+ (1,0) [0|2] "" Vector__XXX
 SG_ TRCM_a035_eventAccelPedalPos m35 : 56|8@1+ (0.4,0) [0|101.6] "%" Vector__XXX
 SG_ TRCM_a036_collisionType m36 : 16|4@1+ (1,0) [0|15] "" Vector__XXX
 SG_ TRCM_a036_collisionSeverity m36 : 20|2@1+ (1,0) [0|3] "" Vector__XXX
 SG_ TRCM_a036_eventArmStatus m36 : 25|1@1+ (1,0) [0|1] "" Vector__XXX
 SG_ TRCM_a036_eventFrontLeftSeatbelt m36 : 30|1@1+ (1,0) [0|1] "" Vector__XXX
 SG_ TRCM_a036_eventFrontRightSeatbel m36 : 31|1@1+ (1,0) [0|1] "" Vector__XXX
 SG_ TRCM_a036_eventVehicleSpeed m36 : 32|12@1+ (0.08,-40) [-40|287.6] "kph" Vector__XXX
 SG_ TRCM_a036_eventDriverBrakeApply m36 : 48|2@1+ (1,0) [0|2] "" Vector__XXX
 SG_ TRCM_a036_eventAccelPedalPos m36 : 56|8@1+ (0.4,0) [0|101.6] "%" Vector__XXX
 SG_ TRCM_a037_nearDeployFront m37 : 16|1@1+ (1,0) [0|1] "" Vector__XXX
 SG_ TRCM_a037_nearDeployRear m37 : 17|1@1+ (1,0) [0|1] "" Vector__XXX
 SG_ TRCM_a037_nearDeployLeft m37 : 18|1@1+ (1,0) [0|1] "" Vector__XXX
 SG_ TRCM_a037_nearDeployRight m37 : 19|1@1+ (1,0) [0|1] "" Vector__XXX
 SG_ TRCM_a037_nearDeployRoll m37 : 20|1@1+ (1,0) [0|1] "" Vector__XXX
 SG_ TRCM_a037_eventArmStatus m37 : 25|1@1+ (1,0) [0|1] "" Vector__XXX
 SG_ TRCM_a037_eventFrontLeftSeatbelt m37 : 30|1@1+ (1,0) [0|1] "" Vector__XXX
 SG_ TRCM_a037_eventFrontRightSeatbel m37 : 31|1@1+ (1,0) [0|1] "" Vector__XXX
 SG_ TRCM_a037_eventVehicleSpeed m37 : 32|12@1+ (0.08,-40) [-40|287.6] "kph" Vector__XXX
 SG_ TRCM_a037_eventDriverBrakeApply m37 : 48|2@1+ (1,0) [0|2] "" Vector__XXX
 SG_ TRCM_a037_eventAccelPedalPos m37 : 56|8@1+ (0.4,0) [0|101.6] "%" Vector__XXX
 SG_ TRCM_a038_stuckLowOrOpenCircuit m38 : 16|1@1+ (1,0) [0|1] "" Vector__XXX
 SG_ TRCM_a038_stuckHigh m38 : 17|1@1+ (1,0) [0|1] "" Vector__XXX
 SG_ TRCM_a038_overCurrent m38 : 18|1@1+ (1,0) [0|1] "" Vector__XXX
 SG_ TRCM_a038_driverOverTemperature m38 : 19|1@1+ (1,0) [0|1] "" Vector__XXX
 SG_ TRCM_a039_stuckLowOrOpenCircuit m39 : 16|1@1+ (1,0) [0|1] "" Vector__XXX
 SG_ TRCM_a039_stuckHigh m39 : 17|1@1+ (1,0) [0|1] "" Vector__XXX
 SG_ TRCM_a039_overCurrent m39 : 18|1@1+ (1,0) [0|1] "" Vector__XXX
 SG_ TRCM_a039_driverOverTemperature m39 : 19|1@1+ (1,0) [0|1] "" Vector__XXX
 SG_ TRCM_a057_VEH_cpControl m57 : 16|1@1+ (1,0) [0|1] "" Vector__XXX
 SG_ TRCM_a059_voltageDrop m59 : 16|12@1+ (0.005443676,0) [0|22.29185322] "V" Vector__XXX
 SG_ TRCM_a059_resistanceEstimate m59 : 28|12@1+ (0.00244,0) [0|9.9918] "Ohms" Vector__XXX
 SG_ TRCM_a059_current m59 : 40|12@1+ (0.05,0) [0|204.75] "A" Vector__XXX
 SG_ TRCM_a063_switchChannel m63 : 16|8@1+ (1,0) [0|255] "" Vector__XXX
 SG_ TRCM_a063_switchType m63 : 24|8@1+ (1,0) [0|255] "" Vector__XXX
 SG_ TRCM_a063_ADCVoltage m63 : 32|8@1+ (0.025,0) [0|6.375] "V" Vector__XXX
 SG_ TRCM_a063_disconnected m63 : 40|1@1+ (1,0) [0|1] "" Vector__XXX
 SG_ TRCM_a063_indeterminate m63 : 41|1@1+ (1,0) [0|1] "" Vector__XXX
 SG_ TRCM_a063_stuckActive m63 : 42|1@1+ (1,0) [0|1] "" Vector__XXX
 SG_ TRCM_a063_faulted m63 : 43|1@1+ (1,0) [0|1] "" Vector__XXX
 SG_ TRCM_a065_vsafingFetVoltage m65 : 16|9@1+ (0.05,0) [0|25.55] "V" Vector__XXX
 SG_ TRCM_a066_busVoltage m66 : 16|9@1+ (0.05,0) [0|25.55] "V" Vector__XXX
 SG_ TRCM_a078_channelIndex m78 : 16|8@1+ (1,0) [0|255] "" Vector__XXX
 SG_ TRCM_a078_value m78 : 24|16@1- (1,0) [-32768|32767] "" Vector__XXX
 SG_ TRCM_a081_eventArmStatus m81 : 25|1@1+ (1,0) [0|1] "" Vector__XXX
 SG_ TRCM_a081_eventFrontLeftSeatbelt m81 : 30|1@1+ (1,0) [0|1] "" Vector__XXX
 SG_ TRCM_a081_eventFrontRightSeatbel m81 : 31|1@1+ (1,0) [0|1] "" Vector__XXX
 SG_ TRCM_a081_eventVehicleSpeed m81 : 32|12@1+ (0.08,-40) [-40|287.6] "kph" Vector__XXX
 SG_ TRCM_a081_eventDriverBrakeApply m81 : 48|2@1+ (1,0) [0|2] "" Vector__XXX
 SG_ TRCM_a081_eventAccelPedalPos m81 : 56|8@1+ (0.4,0) [0|101.6] "%" Vector__XXX
 SG_ TRCM_a082_RIPC_epbPrivateState m82 : 16|1@1+ (1,0) [0|1] "" Vector__XXX
 SG_ TRCM_a082_RIPC_remoteHSD m82 : 17|1@1+ (1,0) [0|1] "" Vector__XXX
 SG_ TRCM_a082_RIPC_railStatus m82 : 18|1@1+ (1,0) [0|1] "" Vector__XXX
 SG_ TRCM_a082_RIPC_remoteMux m82 : 19|1@1+ (1,0) [0|1] "" Vector__XXX
 SG_ TRCM_a083_LIPC_epbPrivateState m83 : 16|1@1+ (1,0) [0|1] "" Vector__XXX
 SG_ TRCM_a083_LIPC_remoteHSD m83 : 17|1@1+ (1,0) [0|1] "" Vector__XXX
 SG_ TRCM_a083_LIPC_railStatus m83 : 18|1@1+ (1,0) [0|1] "" Vector__XXX
 SG_ TRCM_a083_LIPC_HSDFaults m83 : 19|1@1+ (1,0) [0|1] "" Vector__XXX
 SG_ TRCM_a084_CH_StatusC m84 : 16|1@1+ (1,0) [0|1] "" Vector__XXX
 SG_ TRCM_a085_PARTY_buttonStatus m85 : 16|1@1+ (1,0) [0|1] "" Vector__XXX
 SG_ TRCM_a086_VEH_LVBMS_statusHigh m86 : 16|1@1+ (1,0) [0|1] "" Vector__XXX
 SG_ TRCM_a086_VEH_LVBMS_statusLow m86 : 17|1@1+ (1,0) [0|1] "" Vector__XXX
 SG_ TRCM_a086_VEH_status m86 : 18|1@1+ (1,0) [0|1] "" Vector__XXX
 SG_ TRCM_a086_VEH_12VBatteryStatus m86 : 19|1@1+ (1,0) [0|1] "" Vector__XXX
 SG_ TRCM_a086_VEH_LVPowerState m86 : 20|1@1+ (1,0) [0|1] "" Vector__XXX
 SG_ TRCM_a086_VEH_lightStatus m86 : 21|1@1+ (1,0) [0|1] "" Vector__XXX
 SG_ TRCM_a086_VEH_systemStatus m86 : 22|1@1+ (1,0) [0|1] "" Vector__XXX
 SG_ TRCM_a086_VEH_thermalStatus m86 : 23|1@1+ (1,0) [0|1] "" Vector__XXX
 SG_ TRCM_a086_VEH_vehNm m86 : 24|1@1+ (1,0) [0|1] "" Vector__XXX
 SG_ TRCM_a087_VEH_temperature m87 : 16|1@1+ (1,0) [0|1] "" Vector__XXX
 SG_ TRCM_a087_VEH_thermalControl m87 : 17|1@1+ (1,0) [0|1] "" Vector__XXX
 SG_ TRCM_a087_VEH_torque m87 : 18|1@1+ (1,0) [0|1] "" Vector__XXX
 SG_ TRCM_a087_VEH_status m87 : 19|1@1+ (1,0) [0|1] "" Vector__XXX
 SG_ TRCM_a087_PARTY_torque m87 : 20|1@1+ (1,0) [0|1] "" Vector__XXX
 SG_ TRCM_a087_PARTY_status m87 : 21|1@1+ (1,0) [0|1] "" Vector__XXX
 SG_ TRCM_a087_PARTY_temperature m87 : 22|1@1+ (1,0) [0|1] "" Vector__XXX
 SG_ TRCM_a087_PARTY_thermalControl m87 : 23|1@1+ (1,0) [0|1] "" Vector__XXX
 SG_ TRCM_a087_VEH_motorStatus m87 : 24|1@1+ (1,0) [0|1] "" Vector__XXX
 SG_ TRCM_a088_VEH_temperature m88 : 16|1@1+ (1,0) [0|1] "" Vector__XXX
 SG_ TRCM_a088_VEH_thermalControl m88 : 17|1@1+ (1,0) [0|1] "" Vector__XXX
 SG_ TRCM_a088_VEH_torque m88 : 18|1@1+ (1,0) [0|1] "" Vector__XXX
 SG_ TRCM_a088_VEH_status m88 : 19|1@1+ (1,0) [0|1] "" Vector__XXX
 SG_ TRCM_a088_PARTY_torque m88 : 20|1@1+ (1,0) [0|1] "" Vector__XXX
 SG_ TRCM_a088_PARTY_status m88 : 21|1@1+ (1,0) [0|1] "" Vector__XXX
 SG_ TRCM_a088_PARTY_temperature m88 : 22|1@1+ (1,0) [0|1] "" Vector__XXX
 SG_ TRCM_a088_PARTY_thermalControl m88 : 23|1@1+ (1,0) [0|1] "" Vector__XXX
 SG_ TRCM_a088_VEH_motorStatus m88 : 24|1@1+ (1,0) [0|1] "" Vector__XXX
 SG_ TRCM_a089_PARTY_party1 m89 : 16|1@1+ (1,0) [0|1] "" Vector__XXX
 SG_ TRCM_a089_PARTY_status m89 : 17|1@1+ (1,0) [0|1] "" Vector__XXX
 SG_ TRCM_a089_VEH_status m89 : 18|1@1+ (1,0) [0|1] "" Vector__XXX
 SG_ TRCM_a089_BDY_party1 m89 : 19|1@1+ (1,0) [0|1] "" Vector__XXX
 SG_ TRCM_a089_BDY_status m89 : 20|1@1+ (1,0) [0|1] "" Vector__XXX
 SG_ TRCM_a089_CH_status m89 : 21|1@1+ (1,0) [0|1] "" Vector__XXX
 SG_ TRCM_a089_CH_party1 m89 : 22|1@1+ (1,0) [0|1] "" Vector__XXX
 SG_ TRCM_a089_CH_party3 m89 : 23|1@1+ (1,0) [0|1] "" Vector__XXX
 SG_ TRCM_a089_VEH_party1 m89 : 24|1@1+ (1,0) [0|1] "" Vector__XXX
 SG_ TRCM_a089_VEH_party3 m89 : 25|1@1+ (1,0) [0|1] "" Vector__XXX
 SG_ TRCM_a091_VEH_faultsAndExtras m91 : 16|1@1+ (1,0) [0|1] "" Vector__XXX
 SG_ TRCM_a091_VEH_info m91 : 17|1@1+ (1,0) [0|1] "" Vector__XXX
 SG_ TRCM_a091_VEH_state m91 : 18|1@1+ (1,0) [0|1] "" Vector__XXX
 SG_ TRCM_a092_VEH_restraintStatus m92 : 16|1@1+ (1,0) [0|1] "" Vector__XXX
 SG_ TRCM_a092_VEH_switchStatus m92 : 17|1@1+ (1,0) [0|1] "" Vector__XXX
 SG_ TRCM_a092_VEH_seatStatus2 m92 : 18|1@1+ (1,0) [0|1] "" Vector__XXX
 SG_ TRCM_a092_VEH_vehNm m92 : 19|1@1+ (1,0) [0|1] "" Vector__XXX
 SG_ TRCM_a093_VEH_restraintStatus m93 : 16|1@1+ (1,0) [0|1] "" Vector__XXX
 SG_ TRCM_a093_VEH_switchStatus m93 : 17|1@1+ (1,0) [0|1] "" Vector__XXX
 SG_ TRCM_a093_VEH_seatStatus2 m93 : 18|1@1+ (1,0) [0|1] "" Vector__XXX
 SG_ TRCM_a093_VEH_vehNm m93 : 19|1@1+ (1,0) [0|1] "" Vector__XXX
 SG_ TRCM_a094_VEH_sysStatus m94 : 16|1@1+ (1,0) [0|1] "" Vector__XXX
 SG_ TRCM_a094_PARTY_sysStatus m94 : 17|1@1+ (1,0) [0|1] "" Vector__XXX
 SG_ TRCM_a094_CH_sysStatus m94 : 18|1@1+ (1,0) [0|1] "" Vector__XXX
 SG_ TRCM_a095_PT_ptNm m95 : 16|1@1+ (1,0) [0|1] "" Vector__XXX
 SG_ TRCM_a095_PT_status m95 : 17|1@1+ (1,0) [0|1] "" Vector__XXX
 SG_ TRCM_a096_VEH_status m96 : 16|1@1+ (1,0) [0|1] "" Vector__XXX
 SG_ TRCM_a096_CH_status m96 : 17|1@1+ (1,0) [0|1] "" Vector__XXX
 SG_ TRCM_a097_VEH_HVStatus m97 : 16|1@1+ (1,0) [0|1] "" Vector__XXX
 SG_ TRCM_a097_VEH_state m97 : 17|1@1+ (1,0) [0|1] "" Vector__XXX
 SG_ TRCM_a098_CH_torque m98 : 16|1@1+ (1,0) [0|1] "" Vector__XXX
 SG_ TRCM_a098_VEH_hvStatus m98 : 17|1@1+ (1,0) [0|1] "" Vector__XXX
 SG_ TRCM_a098_VEH_status m98 : 18|1@1+ (1,0) [0|1] "" Vector__XXX
 SG_ TRCM_a098_VEH_thermalControl m98 : 19|1@1+ (1,0) [0|1] "" Vector__XXX
 SG_ TRCM_a098_VEH_temperature m98 : 20|1@1+ (1,0) [0|1] "" Vector__XXX
 SG_ TRCM_a098_VEH_torque m98 : 21|1@1+ (1,0) [0|1] "" Vector__XXX
 SG_ TRCM_a098_PARTY_status m98 : 22|1@1+ (1,0) [0|1] "" Vector__XXX
 SG_ TRCM_a098_PARTY_temperature m98 : 23|1@1+ (1,0) [0|1] "" Vector__XXX
 SG_ TRCM_a098_PARTY_thermalControl m98 : 24|1@1+ (1,0) [0|1] "" Vector__XXX
 SG_ TRCM_a098_PARTY_torque m98 : 25|1@1+ (1,0) [0|1] "" Vector__XXX
 SG_ TRCM_a098_PT_thermalControl m98 : 26|1@1+ (1,0) [0|1] "" Vector__XXX
 SG_ TRCM_a098_PT_temperature m98 : 27|1@1+ (1,0) [0|1] "" Vector__XXX
 SG_ TRCM_a098_PARTY_motorStatus m98 : 28|1@1+ (1,0) [0|1] "" Vector__XXX
 SG_ TRCM_a098_VEH_motorStatus m98 : 29|1@1+ (1,0) [0|1] "" Vector__XXX
 SG_ TRCM_a099_VEH_oocStatus m99 : 16|1@1+ (1,0) [0|1] "" Vector__XXX
 SG_ TRCM_a100_VEH m100 : 16|1@1+ (1,0) [0|1] "" Vector__XXX
 SG_ TRCM_a100_PARTY m100 : 17|1@1+ (1,0) [0|1] "" Vector__XXX
 SG_ TRCM_a100_PT m100 : 18|1@1+ (1,0) [0|1] "" Vector__XXX
 SG_ TRCM_a100_CH m100 : 19|1@1+ (1,0) [0|1] "" Vector__XXX
 SG_ TRCM_a100_OBD m100 : 20|1@1+ (1,0) [0|1] "" Vector__XXX
 SG_ TRCM_a101_VEH_state m101 : 16|1@1+ (1,0) [0|1] "" Vector__XXX
 SG_ TRCM_a101_PARTY_locState m101 : 17|1@1+ (1,0) [0|1] "" Vector__XXX
 SG_ TRCM_a101_LIPC_externalWatchdogH m101 : 18|1@1+ (1,0) [0|1] "" Vector__XXX
 SG_ TRCM_a101_VEH_locState m101 : 19|1@1+ (1,0) [0|1] "" Vector__XXX
 SG_ TRCM_a101_BDY_locState m101 : 20|1@1+ (1,0) [0|1] "" Vector__XXX
 SG_ TRCM_a102_VEH_faultsAndExtras m102 : 16|1@1+ (1,0) [0|1] "" Vector__XXX
 SG_ TRCM_a102_VEH_feedbackStatus m102 : 17|1@1+ (1,0) [0|1] "" Vector__XXX
 SG_ TRCM_a102_VEH_sensorStatus m102 : 18|1@1+ (1,0) [0|1] "" Vector__XXX
 SG_ TRCM_a102_VEH_rods m102 : 19|1@1+ (1,0) [0|1] "" Vector__XXX
 SG_ TRCM_a103_VEH_hvsNm m103 : 16|1@1+ (1,0) [0|1] "" Vector__XXX
 SG_ TRCM_a103_VEH_vehNm m103 : 17|1@1+ (1,0) [0|1] "" Vector__XXX
 SG_ TRCM_a103_VEH_status m103 : 18|1@1+ (1,0) [0|1] "" Vector__XXX
 SG_ TRCM_a103_PT_ptNm m103 : 19|1@1+ (1,0) [0|1] "" Vector__XXX
 SG_ TRCM_a103_PT_status m103 : 20|1@1+ (1,0) [0|1] "" Vector__XXX
 SG_ TRCM_a103_VEH_evseStatus m103 : 21|1@1+ (1,0) [0|1] "" Vector__XXX
 SG_ TRCM_a105_VEH_states m105 : 16|1@1+ (1,0) [0|1] "" Vector__XXX
 SG_ TRCM_a105_VEH_chNm m105 : 17|1@1+ (1,0) [0|1] "" Vector__XXX
 SG_ TRCM_a105_VEH_dampingStates m105 : 18|1@1+ (1,0) [0|1] "" Vector__XXX
 SG_ TRCM_a106_VEH_dcdcStatus m106 : 16|1@1+ (1,0) [0|1] "" Vector__XXX
 SG_ TRCM_a106_VEH_thermalControl m106 : 17|1@1+ (1,0) [0|1] "" Vector__XXX
 SG_ TRCM_a106_VEH_dcdcRailStatus m106 : 18|1@1+ (1,0) [0|1] "" Vector__XXX
 SG_ TRCM_a106_CH_dcdcRailStatus m106 : 19|1@1+ (1,0) [0|1] "" Vector__XXX
 SG_ TRCM_a106_CH_alertMatrix m106 : 20|1@1+ (1,0) [0|1] "" Vector__XXX
 SG_ TRCM_a107_VEH_hvsNm m107 : 16|1@1+ (1,0) [0|1] "" Vector__XXX
 SG_ TRCM_a107_VEH_vehNm m107 : 17|1@1+ (1,0) [0|1] "" Vector__XXX
 SG_ TRCM_a107_VEH_status m107 : 18|1@1+ (1,0) [0|1] "" Vector__XXX
 SG_ TRCM_a107_VEH_thermalStatus m107 : 19|1@1+ (1,0) [0|1] "" Vector__XXX
 SG_ TRCM_a107_VEH_bmbMinMax m107 : 20|1@1+ (1,0) [0|1] "" Vector__XXX
 SG_ TRCM_a107_VEH_powerAvailable m107 : 21|1@1+ (1,0) [0|1] "" Vector__XXX
 SG_ TRCM_a107_PT_ptNm m107 : 22|1@1+ (1,0) [0|1] "" Vector__XXX
 SG_ TRCM_a107_PT_status m107 : 23|1@1+ (1,0) [0|1] "" Vector__XXX
 SG_ TRCM_a107_PT_thermalStatus m107 : 24|1@1+ (1,0) [0|1] "" Vector__XXX
 SG_ TRCM_a107_PT_socStatus m107 : 25|1@1+ (1,0) [0|1] "" Vector__XXX
 SG_ TRCM_a107_VEH_socStatus m107 : 26|1@1+ (1,0) [0|1] "" Vector__XXX
 SG_ TRCM_a107_VEH_packConfig m107 : 27|1@1+ (1,0) [0|1] "" Vector__XXX
 SG_ TRCM_a107_VEH_energyStatus m107 : 28|1@1+ (1,0) [0|1] "" Vector__XXX
 SG_ TRCM_a107_VEH_chargeInfo m107 : 29|1@1+ (1,0) [0|1] "" Vector__XXX
 SG_ TRCM_a108_VEH_hvStatus m108 : 16|1@1+ (1,0) [0|1] "" Vector__XXX
 SG_ TRCM_a108_VEH_temperature m108 : 17|1@1+ (1,0) [0|1] "" Vector__XXX
 SG_ TRCM_a108_VEH_thermalControl m108 : 18|1@1+ (1,0) [0|1] "" Vector__XXX
 SG_ TRCM_a108_VEH_torque m108 : 19|1@1+ (1,0) [0|1] "" Vector__XXX
 SG_ TRCM_a108_VEH_status m108 : 20|1@1+ (1,0) [0|1] "" Vector__XXX
 SG_ TRCM_a108_PARTY_torque m108 : 21|1@1+ (1,0) [0|1] "" Vector__XXX
 SG_ TRCM_a108_PARTY_status m108 : 22|1@1+ (1,0) [0|1] "" Vector__XXX
 SG_ TRCM_a108_PARTY_temperature m108 : 23|1@1+ (1,0) [0|1] "" Vector__XXX
 SG_ TRCM_a108_PARTY_thermalControl m108 : 24|1@1+ (1,0) [0|1] "" Vector__XXX
 SG_ TRCM_a108_PT_temperature m108 : 25|1@1+ (1,0) [0|1] "" Vector__XXX
 SG_ TRCM_a108_PT_thermalControl m108 : 26|1@1+ (1,0) [0|1] "" Vector__XXX
 SG_ TRCM_a108_PARTY_motorStatus m108 : 27|1@1+ (1,0) [0|1] "" Vector__XXX
 SG_ TRCM_a108_VEH_motorStatus m108 : 28|1@1+ (1,0) [0|1] "" Vector__XXX
 SG_ TRCM_a108_CH_torque m108 : 29|1@1+ (1,0) [0|1] "" Vector__XXX
 SG_ TRCM_a110_VEH_carState m110 : 16|1@1+ (1,0) [0|1] "" Vector__XXX
 SG_ TRCM_a110_VEH_carConfig m110 : 17|1@1+ (1,0) [0|1] "" Vector__XXX
 SG_ TRCM_a110_VEH_time m110 : 18|1@1+ (1,0) [0|1] "" Vector__XXX
 SG_ TRCM_a110_VEH_updateStatus m110 : 19|1@1+ (1,0) [0|1] "" Vector__XXX
 SG_ TRCM_a110_VEH_vehNm m110 : 20|1@1+ (1,0) [0|1] "" Vector__XXX
 SG_ TRCM_a110_VEH_mismatchFault m110 : 21|1@1+ (1,0) [0|1] "" Vector__XXX
 SG_ TRCM_a110_VEH_vin m110 : 22|1@1+ (1,0) [0|1] "" Vector__XXX
 SG_ TRCM_a110_VEH_bmpDebug m110 : 23|1@1+ (1,0) [0|1] "" Vector__XXX
 SG_ TRCM_a110_VEH_gearControl m110 : 24|1@1+ (1,0) [0|1] "" Vector__XXX
 SG_ TRCM_a110_VEH_canLogAvailability m110 : 25|1@1+ (1,0) [0|1] "" Vector__XXX
 SG_ TRCM_a110_CH_airbagCutoffStatus m110 : 26|1@1+ (1,0) [0|1] "" Vector__XXX
 SG_ TRCM_a110_CH_carConfig m110 : 27|1@1+ (1,0) [0|1] "" Vector__XXX
 SG_ TRCM_a110_CH_carState m110 : 28|1@1+ (1,0) [0|1] "" Vector__XXX
 SG_ TRCM_a110_CH_vin m110 : 29|1@1+ (1,0) [0|1] "" Vector__XXX
 SG_ TRCM_a110_CH_chNm m110 : 30|1@1+ (1,0) [0|1] "" Vector__XXX
 SG_ TRCM_a110_CH_epochTimeGtw m110 : 31|1@1+ (1,0) [0|1] "" Vector__XXX
 SG_ TRCM_a110_PARTY_carConfig m110 : 32|1@1+ (1,0) [0|1] "" Vector__XXX
 SG_ TRCM_a111_VEH_internalStatus m111 : 16|1@1+ (1,0) [0|1] "" Vector__XXX
 SG_ TRCM_a111_VEH_status m111 : 17|1@1+ (1,0) [0|1] "" Vector__XXX
 SG_ TRCM_a111_VEH_vehNm m111 : 18|1@1+ (1,0) [0|1] "" Vector__XXX
 SG_ TRCM_a111_RIPC_LVPowerState m111 : 19|1@1+ (1,0) [0|1] "" Vector__XXX
 SG_ TRCM_a111_RIPC_epbPrivateState m111 : 20|1@1+ (1,0) [0|1] "" Vector__XXX
 SG_ TRCM_a111_RIPC_railStatus m111 : 21|1@1+ (1,0) [0|1] "" Vector__XXX
 SG_ TRCM_a111_RIPC_remoteADC m111 : 22|1@1+ (1,0) [0|1] "" Vector__XXX
 SG_ TRCM_a111_RIPC_switchStatus m111 : 23|1@1+ (1,0) [0|1] "" Vector__XXX
 SG_ TRCM_a111_VEH_LVPowerState m111 : 24|1@1+ (1,0) [0|1] "" Vector__XXX
 SG_ TRCM_a111_VEH_seatStatus m111 : 25|1@1+ (1,0) [0|1] "" Vector__XXX
 SG_ TRCM_a111_PARTY_status m111 : 26|1@1+ (1,0) [0|1] "" Vector__XXX
 SG_ TRCM_a111_CH_status m111 : 27|1@1+ (1,0) [0|1] "" Vector__XXX
 SG_ TRCM_a112_VEH_internalStatus m112 : 16|1@1+ (1,0) [0|1] "" Vector__XXX
 SG_ TRCM_a112_VEH_status m112 : 17|1@1+ (1,0) [0|1] "" Vector__XXX
 SG_ TRCM_a112_VEH_vehNm m112 : 18|1@1+ (1,0) [0|1] "" Vector__XXX
 SG_ TRCM_a112_LIPC_LVPowerState m112 : 19|1@1+ (1,0) [0|1] "" Vector__XXX
 SG_ TRCM_a112_LIPC_epbPrivateState m112 : 20|1@1+ (1,0) [0|1] "" Vector__XXX
 SG_ TRCM_a112_LIPC_railStatus m112 : 21|1@1+ (1,0) [0|1] "" Vector__XXX
 SG_ TRCM_a112_LIPC_remoteADC m112 : 22|1@1+ (1,0) [0|1] "" Vector__XXX
 SG_ TRCM_a112_LIPC_switchStatus m112 : 23|1@1+ (1,0) [0|1] "" Vector__XXX
 SG_ TRCM_a112_VEH_LVPowerState m112 : 24|1@1+ (1,0) [0|1] "" Vector__XXX
 SG_ TRCM_a112_PARTY_status m112 : 25|1@1+ (1,0) [0|1] "" Vector__XXX
 SG_ TRCM_a112_CH_status m112 : 26|1@1+ (1,0) [0|1] "" Vector__XXX
 SG_ TRCM_a114_PARTY_status m114 : 16|1@1+ (1,0) [0|1] "" Vector__XXX
 SG_ TRCM_a114_PARTY_wheelSpeeds m114 : 17|1@1+ (1,0) [0|1] "" Vector__XXX
 SG_ TRCM_a114_VEH_wheelSpeeds m114 : 18|1@1+ (1,0) [0|1] "" Vector__XXX
 SG_ TRCM_a114_CH_wheelSpeeds m114 : 19|1@1+ (1,0) [0|1] "" Vector__XXX
 SG_ TRCM_a114_PARTY_party3 m114 : 20|1@1+ (1,0) [0|1] "" Vector__XXX
 SG_ TRCM_a114_VEH_party3 m114 : 21|1@1+ (1,0) [0|1] "" Vector__XXX
 SG_ TRCM_a114_VEH_status m114 : 22|1@1+ (1,0) [0|1] "" Vector__XXX
 SG_ TRCM_a114_PARTY_wheelRotation m114 : 23|1@1+ (1,0) [0|1] "" Vector__XXX
 SG_ TRCM_a114_CH_wheelRotation m114 : 24|1@1+ (1,0) [0|1] "" Vector__XXX
 SG_ TRCM_a114_VEH_wheelRotation m114 : 25|1@1+ (1,0) [0|1] "" Vector__XXX
 SG_ TRCM_a114_PARTY_brakeTorque m114 : 26|1@1+ (1,0) [0|1] "" Vector__XXX
 SG_ TRCM_a114_PARTY_offsets m114 : 27|1@1+ (1,0) [0|1] "" Vector__XXX
 SG_ TRCM_a114_BDY_offsets m114 : 28|1@1+ (1,0) [0|1] "" Vector__XXX
 SG_ TRCM_a114_BDY_party3 m114 : 29|1@1+ (1,0) [0|1] "" Vector__XXX
 SG_ TRCM_a114_BDY_status m114 : 30|1@1+ (1,0) [0|1] "" Vector__XXX
 SG_ TRCM_a114_BDY_wheelRotation m114 : 31|1@1+ (1,0) [0|1] "" Vector__XXX
 SG_ TRCM_a114_BDY_wheelSpeeds m114 : 32|1@1+ (1,0) [0|1] "" Vector__XXX
 SG_ TRCM_a114_CH_party1 m114 : 33|1@1+ (1,0) [0|1] "" Vector__XXX
 SG_ TRCM_a114_CH_party3 m114 : 34|1@1+ (1,0) [0|1] "" Vector__XXX
 SG_ TRCM_a114_CH_status m114 : 35|1@1+ (1,0) [0|1] "" Vector__XXX
 SG_ TRCM_a115_VEH_vehNm m115 : 16|1@1+ (1,0) [0|1] "" Vector__XXX
 SG_ TRCM_a115_VEH_authentication m115 : 17|1@1+ (1,0) [0|1] "" Vector__XXX
 SG_ TRCM_a115_VEH_BLEResetRequest m115 : 18|1@1+ (1,0) [0|1] "" Vector__XXX
 SG_ TRCM_a115_VEH_requests m115 : 19|1@1+ (1,0) [0|1] "" Vector__XXX
 SG_ TRCM_a115_VEH_requests2 m115 : 20|1@1+ (1,0) [0|1] "" Vector__XXX
 SG_ TRCM_a115_REM_authentication m115 : 21|1@1+ (1,0) [0|1] "" Vector__XXX
 SG_ TRCM_a115_UI_corianderVehicleCon m115 : 22|1@1+ (1,0) [0|1] "" Vector__XXX
 SG_ TRCM_a115_CH_TPMSDisplay m115 : 23|1@1+ (1,0) [0|1] "" Vector__XXX
 SG_ TRCM_a116_PARTY_epbmStatus m116 : 16|1@1+ (1,0) [0|1] "" Vector__XXX
 SG_ TRCM_a116_VEH_vehNm m116 : 17|1@1+ (1,0) [0|1] "" Vector__XXX
 SG_ TRCM_a116_VEH_hvacRequest m116 : 18|1@1+ (1,0) [0|1] "" Vector__XXX
 SG_ TRCM_a116_VEH_hvacStatus m116 : 19|1@1+ (1,0) [0|1] "" Vector__XXX
 SG_ TRCM_a116_VEH_LVPowerState m116 : 20|1@1+ (1,0) [0|1] "" Vector__XXX
 SG_ TRCM_a116_VEH_lightStatus m116 : 21|1@1+ (1,0) [0|1] "" Vector__XXX
 SG_ TRCM_a116_VEH_seatStatus m116 : 22|1@1+ (1,0) [0|1] "" Vector__XXX
 SG_ TRCM_a116_VEH_thsStatus m116 : 23|1@1+ (1,0) [0|1] "" Vector__XXX
 SG_ TRCM_a116_VEH_doorStatus m116 : 24|1@1+ (1,0) [0|1] "" Vector__XXX
 SG_ TRCM_a116_VEH_seatHeatStatus m116 : 25|1@1+ (1,0) [0|1] "" Vector__XXX
 SG_ TRCM_a116_VEH_restraintStatus m116 : 26|1@1+ (1,0) [0|1] "" Vector__XXX
 SG_ TRCM_a116_VEH_switchStatus m116 : 27|1@1+ (1,0) [0|1] "" Vector__XXX
 SG_ TRCM_a116_VEH_logging1Hz m116 : 28|1@1+ (1,0) [0|1] "" Vector__XXX
 SG_ TRCM_a116_VEH_seatStatus2 m116 : 29|1@1+ (1,0) [0|1] "" Vector__XXX
 SG_ TRCM_a116_VEH_status m116 : 30|1@1+ (1,0) [0|1] "" Vector__XXX
 SG_ TRCM_a116_VEH_thermalCommand m116 : 31|1@1+ (1,0) [0|1] "" Vector__XXX
 SG_ TRCM_a116_VEH_windowStatus m116 : 32|1@1+ (1,0) [0|1] "" Vector__XXX
 SG_ TRCM_a116_PARTY_restraintStatus m116 : 33|1@1+ (1,0) [0|1] "" Vector__XXX
 SG_ TRCM_a116_PARTY_doorStatus m116 : 34|1@1+ (1,0) [0|1] "" Vector__XXX
 SG_ TRCM_a116_BDY_epbmStatus m116 : 35|1@1+ (1,0) [0|1] "" Vector__XXX
 SG_ TRCM_a116_BDY_restraintStatus m116 : 36|1@1+ (1,0) [0|1] "" Vector__XXX
 SG_ TRCM_a116_BDY_switchStatus m116 : 37|1@1+ (1,0) [0|1] "" Vector__XXX
 SG_ TRCM_a117_BDY_epbmStatus m117 : 16|1@1+ (1,0) [0|1] "" Vector__XXX
 SG_ TRCM_a117_BDY_restraintStatus m117 : 17|1@1+ (1,0) [0|1] "" Vector__XXX
 SG_ TRCM_a117_VEH_prndStatus m117 : 18|1@1+ (1,0) [0|1] "" Vector__XXX
 SG_ TRCM_a117_PARTY_epbmStatus m117 : 19|1@1+ (1,0) [0|1] "" Vector__XXX
 SG_ TRCM_a117_VEH_vehNm m117 : 20|1@1+ (1,0) [0|1] "" Vector__XXX
 SG_ TRCM_a117_VEH_hvacBlowerFdb m117 : 21|1@1+ (1,0) [0|1] "" Vector__XXX
 SG_ TRCM_a117_VEH_LVPowerState m117 : 22|1@1+ (1,0) [0|1] "" Vector__XXX
 SG_ TRCM_a117_VEH_restraintStatus m117 : 23|1@1+ (1,0) [0|1] "" Vector__XXX
 SG_ TRCM_a117_VEH_lightStatus m117 : 24|1@1+ (1,0) [0|1] "" Vector__XXX
 SG_ TRCM_a117_VEH_seatStatus m117 : 25|1@1+ (1,0) [0|1] "" Vector__XXX
 SG_ TRCM_a117_BDY_falconSwitchStatus m117 : 26|1@1+ (1,0) [0|1] "" Vector__XXX
 SG_ TRCM_a117_VEH_doorStatus m117 : 27|1@1+ (1,0) [0|1] "" Vector__XXX
 SG_ TRCM_a117_VEH_doorStatus2 m117 : 28|1@1+ (1,0) [0|1] "" Vector__XXX
 SG_ TRCM_a117_VEH_windowStatus m117 : 29|1@1+ (1,0) [0|1] "" Vector__XXX
 SG_ TRCM_a117_VEH_switchStatus m117 : 30|1@1+ (1,0) [0|1] "" Vector__XXX
 SG_ TRCM_a117_VEH_intrusionSensorSta m117 : 31|1@1+ (1,0) [0|1] "" Vector__XXX
 SG_ TRCM_a117_VEH_liftgateStatus m117 : 32|1@1+ (1,0) [0|1] "" Vector__XXX
 SG_ TRCM_a117_VEH_seatStatus2 m117 : 33|1@1+ (1,0) [0|1] "" Vector__XXX
 SG_ TRCM_a117_PARTY_restraintStatus m117 : 34|1@1+ (1,0) [0|1] "" Vector__XXX
 SG_ TRCM_a117_VEH_thermalStatus m117 : 35|1@1+ (1,0) [0|1] "" Vector__XXX
 SG_ TRCM_a117_PARTY_doorStatus m117 : 36|1@1+ (1,0) [0|1] "" Vector__XXX
 SG_ TRCM_a117_VEH_status m117 : 37|1@1+ (1,0) [0|1] "" Vector__XXX
 SG_ TRCM_a117_PARTY_prndStatus m117 : 38|1@1+ (1,0) [0|1] "" Vector__XXX
 SG_ TRCM_a117_PARTY_lightingSecondar m117 : 39|1@1+ (1,0) [0|1] "" Vector__XXX
 SG_ TRCM_a118_VEH_vehNm m118 : 16|1@1+ (1,0) [0|1] "" Vector__XXX
 SG_ TRCM_a118_VEH_lighting m118 : 17|1@1+ (1,0) [0|1] "" Vector__XXX
 SG_ TRCM_a118_VEH_sensors m118 : 18|1@1+ (1,0) [0|1] "" Vector__XXX
 SG_ TRCM_a118_VEH_status m118 : 19|1@1+ (1,0) [0|1] "" Vector__XXX
 SG_ TRCM_a118_VEH_okToUseHighPwr m118 : 20|1@1+ (1,0) [0|1] "" Vector__XXX
 SG_ TRCM_a118_VEH_LVPowerState m118 : 21|1@1+ (1,0) [0|1] "" Vector__XXX
 SG_ TRCM_a118_VEH_coolant m118 : 22|1@1+ (1,0) [0|1] "" Vector__XXX
 SG_ TRCM_a118_VEH_vehicleStatus m118 : 23|1@1+ (1,0) [0|1] "" Vector__XXX
 SG_ TRCM_a118_VEH_12VBatteryStatus m118 : 24|1@1+ (1,0) [0|1] "" Vector__XXX
 SG_ TRCM_a118_VEH_systemStatus m118 : 25|1@1+ (1,0) [0|1] "" Vector__XXX
 SG_ TRCM_a118_PARTY_LVPowerState m118 : 26|1@1+ (1,0) [0|1] "" Vector__XXX
 SG_ TRCM_a118_PARTY_outputPowerStatu m118 : 27|1@1+ (1,0) [0|1] "" Vector__XXX
 SG_ TRCM_a118_PARTY_vehicleTime m118 : 28|1@1+ (1,0) [0|1] "" Vector__XXX
 SG_ TRCM_a118_VEH_thermalCommand m118 : 29|1@1+ (1,0) [0|1] "" Vector__XXX
 SG_ TRCM_a118_CH_LVPowerState m118 : 30|1@1+ (1,0) [0|1] "" Vector__XXX
 SG_ TRCM_a118_PARTY_sensors m118 : 31|1@1+ (1,0) [0|1] "" Vector__XXX
 SG_ TRCM_a118_CH_sensors m118 : 32|1@1+ (1,0) [0|1] "" Vector__XXX
 SG_ TRCM_a118_VEH_interNodeResistanc m118 : 33|1@1+ (1,0) [0|1] "" Vector__XXX
 SG_ TRCM_a118_CH_lighting m118 : 34|1@1+ (1,0) [0|1] "" Vector__XXX
 SG_ TRCM_a118_VEH_lightStatus m118 : 35|1@1+ (1,0) [0|1] "" Vector__XXX
 SG_ TRCM_a118_PARTY_vehNm m118 : 36|1@1+ (1,0) [0|1] "" Vector__XXX
 SG_ TRCM_a118_CH_12VBatteryStatus m118 : 37|1@1+ (1,0) [0|1] "" Vector__XXX
 SG_ TRCM_a118_CH_LVBMS_statusHigh m118 : 38|1@1+ (1,0) [0|1] "" Vector__XXX
 SG_ TRCM_a118_CH_alertMatrix m118 : 39|1@1+ (1,0) [0|1] "" Vector__XXX
 SG_ TRCM_a118_BDY_outputPowerStatus m118 : 40|1@1+ (1,0) [0|1] "" Vector__XXX
 SG_ TRCM_a118_BDY_vehicleTime m118 : 41|1@1+ (1,0) [0|1] "" Vector__XXX
 SG_ TRCM_a118_PARTY_AP_vehicleState1 m118 : 42|1@1+ (1,0) [0|1] "" Vector__XXX
 SG_ TRCM_a118_BDY_AP_vehicleState1Hz m118 : 43|1@1+ (1,0) [0|1] "" Vector__XXX
 SG_ TRCM_a118_PARTY_VCFRONT_cameraCl m118 : 44|1@1+ (1,0) [0|1] "" Vector__XXX
 SG_ TRCM_a119_VEH_steerAngle m119 : 16|1@1+ (1,0) [0|1] "" Vector__XXX
 SG_ TRCM_a119_VEH_leftStalk m119 : 17|1@1+ (1,0) [0|1] "" Vector__XXX
 SG_ TRCM_a119_VEH_rightStalk m119 : 18|1@1+ (1,0) [0|1] "" Vector__XXX
 SG_ TRCM_a119_PARTY_rightStalk m119 : 19|1@1+ (1,0) [0|1] "" Vector__XXX
 SG_ TRCM_a119_CH_steerAngle m119 : 20|1@1+ (1,0) [0|1] "" Vector__XXX
 SG_ TRCM_a119_PARTY_steerAngle m119 : 21|1@1+ (1,0) [0|1] "" Vector__XXX
 SG_ TRCM_a120_PARTY_chassisCntl m120 : 16|1@1+ (1,0) [0|1] "" Vector__XXX
 SG_ TRCM_a120_VEH_systemStatus m120 : 17|1@1+ (1,0) [0|1] "" Vector__XXX
 SG_ TRCM_a120_CH_chassisCntl m120 : 18|1@1+ (1,0) [0|1] "" Vector__XXX
 SG_ TRCM_a120_PARTY_systemStatus m120 : 19|1@1+ (1,0) [0|1] "" Vector__XXX
 SG_ TRCM_a120_PARTY_torque m120 : 20|1@1+ (1,0) [0|1] "" Vector__XXX
 SG_ TRCM_a120_VEH_torque m120 : 21|1@1+ (1,0) [0|1] "" Vector__XXX
 SG_ TRCM_a120_PARTY_locStatus m120 : 22|1@1+ (1,0) [0|1] "" Vector__XXX
 SG_ TRCM_a120_PARTY_speed m120 : 23|1@1+ (1,0) [0|1] "" Vector__XXX
 SG_ TRCM_a120_VEH_speed m120 : 24|1@1+ (1,0) [0|1] "" Vector__XXX
 SG_ TRCM_a120_PARTY_status m120 : 25|1@1+ (1,0) [0|1] "" Vector__XXX
 SG_ TRCM_a120_PT_speed m120 : 26|1@1+ (1,0) [0|1] "" Vector__XXX
 SG_ TRCM_a120_PT_systemStatus m120 : 27|1@1+ (1,0) [0|1] "" Vector__XXX
 SG_ TRCM_a120_PARTY_vehicleEstimates m120 : 28|1@1+ (1,0) [0|1] "" Vector__XXX
 SG_ TRCM_a120_VEH_aggregatedAxleSpee m120 : 29|1@1+ (1,0) [0|1] "" Vector__XXX
 SG_ TRCM_a120_PARTY_aggregatedAxleSp m120 : 30|1@1+ (1,0) [0|1] "" Vector__XXX
 SG_ TRCM_a120_VEH_systemPower m120 : 31|1@1+ (1,0) [0|1] "" Vector__XXX
 SG_ TRCM_a120_PARTY_autonomyHealth m120 : 32|1@1+ (1,0) [0|1] "" Vector__XXX
 SG_ TRCM_a120_VEH_autonomyHealth m120 : 33|1@1+ (1,0) [0|1] "" Vector__XXX
 SG_ TRCM_a120_PT_systemPower m120 : 34|1@1+ (1,0) [0|1] "" Vector__XXX
 SG_ TRCM_a120_PARTY_stalklessInterfa m120 : 35|1@1+ (1,0) [0|1] "" Vector__XXX
 SG_ TRCM_a120_CH_speed m120 : 36|1@1+ (1,0) [0|1] "" Vector__XXX
 SG_ TRCM_a120_VEH_estimatedBrakeTemp m120 : 37|1@1+ (1,0) [0|1] "" Vector__XXX
 SG_ TRCM_a120_PARTY_prndControl m120 : 38|1@1+ (1,0) [0|1] "" Vector__XXX
 SG_ TRCM_a120_PARTY_locStatus2 m120 : 39|1@1+ (1,0) [0|1] "" Vector__XXX
 SG_ TRCM_a120_VEH_chassisCntl m120 : 40|1@1+ (1,0) [0|1] "" Vector__XXX
 SG_ TRCM_a120_CH_locStatus2 m120 : 41|1@1+ (1,0) [0|1] "" Vector__XXX
 SG_ TRCM_a120_VEH_locStatus m120 : 42|1@1+ (1,0) [0|1] "" Vector__XXX
 SG_ TRCM_a120_VEH_locStatus2 m120 : 43|1@1+ (1,0) [0|1] "" Vector__XXX
 SG_ TRCM_a120_VEH_prndControl m120 : 44|1@1+ (1,0) [0|1] "" Vector__XXX
 SG_ TRCM_a120_VEH_vehicleEstimates m120 : 45|1@1+ (1,0) [0|1] "" Vector__XXX
 SG_ TRCM_a120_PARTY_motorStatus m120 : 46|1@1+ (1,0) [0|1] "" Vector__XXX
 SG_ TRCM_a120_VEH_motorStatus m120 : 47|1@1+ (1,0) [0|1] "" Vector__XXX
 SG_ TRCM_a120_BDY_speed m120 : 48|1@1+ (1,0) [0|1] "" Vector__XXX
 SG_ TRCM_a332_groundLossError m332 : 16|1@1+ (1,0) [0|1] "" Vector__XXX
 SG_ TRCM_a332_overcurrentError m332 : 17|1@1+ (1,0) [0|1] "" Vector__XXX
 SG_ TRCM_a332_overvoltageError m332 : 18|1@1+ (1,0) [0|1] "" Vector__XXX
 SG_ TRCM_a332_currentMonitorTimer m332 : 24|8@1+ (16,0) [0|4080] "us" Vector__XXX
 SG_ TRCM_a333_groundLossError m333 : 16|1@1+ (1,0) [0|1] "" Vector__XXX
 SG_ TRCM_a333_overcurrentError m333 : 17|1@1+ (1,0) [0|1] "" Vector__XXX
 SG_ TRCM_a333_overvoltageError m333 : 18|1@1+ (1,0) [0|1] "" Vector__XXX
 SG_ TRCM_a333_currentMonitorTimer m333 : 24|8@1+ (16,0) [0|4080] "us" Vector__XXX
 SG_ TRCM_a334_groundLossError m334 : 16|1@1+ (1,0) [0|1] "" Vector__XXX
 SG_ TRCM_a334_overcurrentError m334 : 17|1@1+ (1,0) [0|1] "" Vector__XXX
 SG_ TRCM_a334_overvoltageError m334 : 18|1@1+ (1,0) [0|1] "" Vector__XXX
 SG_ TRCM_a334_currentMonitorTimer m334 : 24|8@1+ (16,0) [0|4080] "us" Vector__XXX
 SG_ TRCM_a335_groundLossError m335 : 16|1@1+ (1,0) [0|1] "" Vector__XXX
 SG_ TRCM_a335_overcurrentError m335 : 17|1@1+ (1,0) [0|1] "" Vector__XXX
 SG_ TRCM_a335_overvoltageError m335 : 18|1@1+ (1,0) [0|1] "" Vector__XXX
 SG_ TRCM_a335_currentMonitorTimer m335 : 24|8@1+ (16,0) [0|4080] "us" Vector__XXX
 SG_ TRCM_a336_groundLossError m336 : 16|1@1+ (1,0) [0|1] "" Vector__XXX
 SG_ TRCM_a336_overcurrentError m336 : 17|1@1+ (1,0) [0|1] "" Vector__XXX
 SG_ TRCM_a336_overvoltageError m336 : 18|1@1+ (1,0) [0|1] "" Vector__XXX
 SG_ TRCM_a336_currentMonitorTimer m336 : 24|8@1+ (16,0) [0|4080] "us" Vector__XXX
 SG_ TRCM_a337_groundLossError m337 : 16|1@1+ (1,0) [0|1] "" Vector__XXX
 SG_ TRCM_a337_overcurrentError m337 : 17|1@1+ (1,0) [0|1] "" Vector__XXX
 SG_ TRCM_a337_overvoltageError m337 : 18|1@1+ (1,0) [0|1] "" Vector__XXX
 SG_ TRCM_a337_currentMonitorTimer m337 : 24|8@1+ (16,0) [0|4080] "us" Vector__XXX
 SG_ TRCM_a338_groundLossError m338 : 16|1@1+ (1,0) [0|1] "" Vector__XXX
 SG_ TRCM_a338_overcurrentError m338 : 17|1@1+ (1,0) [0|1] "" Vector__XXX
 SG_ TRCM_a338_overvoltageError m338 : 18|1@1+ (1,0) [0|1] "" Vector__XXX
 SG_ TRCM_a338_currentMonitorTimer m338 : 24|8@1+ (16,0) [0|4080] "us" Vector__XXX
 SG_ TRCM_a340_groundLossError m340 : 16|1@1+ (1,0) [0|1] "" Vector__XXX
 SG_ TRCM_a340_overcurrentError m340 : 17|1@1+ (1,0) [0|1] "" Vector__XXX
 SG_ TRCM_a340_overvoltageError m340 : 18|1@1+ (1,0) [0|1] "" Vector__XXX
 SG_ TRCM_a340_currentMonitorTimer m340 : 24|8@1+ (16,0) [0|4080] "us" Vector__XXX
 SG_ TRCM_a341_groundLossError m341 : 16|1@1+ (1,0) [0|1] "" Vector__XXX
 SG_ TRCM_a341_overcurrentError m341 : 17|1@1+ (1,0) [0|1] "" Vector__XXX
 SG_ TRCM_a341_overvoltageError m341 : 18|1@1+ (1,0) [0|1] "" Vector__XXX
 SG_ TRCM_a341_currentMonitorTimer m341 : 24|8@1+ (16,0) [0|4080] "us" Vector__XXX
 SG_ TRCM_a342_groundLossError m342 : 16|1@1+ (1,0) [0|1] "" Vector__XXX
 SG_ TRCM_a342_overcurrentError m342 : 17|1@1+ (1,0) [0|1] "" Vector__XXX
 SG_ TRCM_a342_overvoltageError m342 : 18|1@1+ (1,0) [0|1] "" Vector__XXX
 SG_ TRCM_a342_currentMonitorTimer m342 : 24|8@1+ (16,0) [0|4080] "us" Vector__XXX
 SG_ TRCM_a343_groundLossError m343 : 16|1@1+ (1,0) [0|1] "" Vector__XXX
 SG_ TRCM_a343_overcurrentError m343 : 17|1@1+ (1,0) [0|1] "" Vector__XXX
 SG_ TRCM_a343_overvoltageError m343 : 18|1@1+ (1,0) [0|1] "" Vector__XXX
 SG_ TRCM_a343_currentMonitorTimer m343 : 24|8@1+ (16,0) [0|4080] "us" Vector__XXX
 SG_ TRCM_a344_groundLossError m344 : 16|1@1+ (1,0) [0|1] "" Vector__XXX
 SG_ TRCM_a344_overcurrentError m344 : 17|1@1+ (1,0) [0|1] "" Vector__XXX
 SG_ TRCM_a344_overvoltageError m344 : 18|1@1+ (1,0) [0|1] "" Vector__XXX
 SG_ TRCM_a344_currentMonitorTimer m344 : 24|8@1+ (16,0) [0|4080] "us" Vector__XXX
 SG_ TRCM_a345_groundLossError m345 : 16|1@1+ (1,0) [0|1] "" Vector__XXX
 SG_ TRCM_a345_overcurrentError m345 : 17|1@1+ (1,0) [0|1] "" Vector__XXX
 SG_ TRCM_a345_overvoltageError m345 : 18|1@1+ (1,0) [0|1] "" Vector__XXX
 SG_ TRCM_a345_currentMonitorTimer m345 : 24|8@1+ (16,0) [0|4080] "us" Vector__XXX
 SG_ TRCM_a346_groundLossError m346 : 16|1@1+ (1,0) [0|1] "" Vector__XXX
 SG_ TRCM_a346_overcurrentError m346 : 17|1@1+ (1,0) [0|1] "" Vector__XXX
 SG_ TRCM_a346_overvoltageError m346 : 18|1@1+ (1,0) [0|1] "" Vector__XXX
 SG_ TRCM_a346_currentMonitorTimer m346 : 24|8@1+ (16,0) [0|4080] "us" Vector__XXX
 SG_ TRCM_a347_groundLossError m347 : 16|1@1+ (1,0) [0|1] "" Vector__XXX
 SG_ TRCM_a347_overcurrentError m347 : 17|1@1+ (1,0) [0|1] "" Vector__XXX
 SG_ TRCM_a347_overvoltageError m347 : 18|1@1+ (1,0) [0|1] "" Vector__XXX
 SG_ TRCM_a347_currentMonitorTimer m347 : 24|8@1+ (16,0) [0|4080] "us" Vector__XXX
 SG_ TRCM_a348_groundLossError m348 : 16|1@1+ (1,0) [0|1] "" Vector__XXX
 SG_ TRCM_a348_overcurrentError m348 : 17|1@1+ (1,0) [0|1] "" Vector__XXX
 SG_ TRCM_a348_overvoltageError m348 : 18|1@1+ (1,0) [0|1] "" Vector__XXX
 SG_ TRCM_a348_currentMonitorTimer m348 : 24|8@1+ (16,0) [0|4080] "us" Vector__XXX
 SG_ TRCM_a349_groundLossError m349 : 16|1@1+ (1,0) [0|1] "" Vector__XXX
 SG_ TRCM_a349_overcurrentError m349 : 17|1@1+ (1,0) [0|1] "" Vector__XXX
 SG_ TRCM_a349_overvoltageError m349 : 18|1@1+ (1,0) [0|1] "" Vector__XXX
 SG_ TRCM_a349_currentMonitorTimer m349 : 24|8@1+ (16,0) [0|4080] "us" Vector__XXX
 SG_ TRCM_a350_groundLossError m350 : 16|1@1+ (1,0) [0|1] "" Vector__XXX
 SG_ TRCM_a350_overcurrentError m350 : 17|1@1+ (1,0) [0|1] "" Vector__XXX
 SG_ TRCM_a350_overvoltageError m350 : 18|1@1+ (1,0) [0|1] "" Vector__XXX
 SG_ TRCM_a350_currentMonitorTimer m350 : 24|8@1+ (16,0) [0|4080] "us" Vector__XXX
 SG_ TRCM_a351_groundLossError m351 : 16|1@1+ (1,0) [0|1] "" Vector__XXX
 SG_ TRCM_a351_overcurrentError m351 : 17|1@1+ (1,0) [0|1] "" Vector__XXX
 SG_ TRCM_a351_overvoltageError m351 : 18|1@1+ (1,0) [0|1] "" Vector__XXX
 SG_ TRCM_a351_currentMonitorTimer m351 : 24|8@1+ (16,0) [0|4080] "us" Vector__XXX
 SG_ TRCM_a352_groundLossError m352 : 16|1@1+ (1,0) [0|1] "" Vector__XXX
 SG_ TRCM_a352_overcurrentError m352 : 17|1@1+ (1,0) [0|1] "" Vector__XXX
 SG_ TRCM_a352_overvoltageError m352 : 18|1@1+ (1,0) [0|1] "" Vector__XXX
 SG_ TRCM_a352_currentMonitorTimer m352 : 24|8@1+ (16,0) [0|4080] "us" Vector__XXX
 SG_ TRCM_a353_groundLossError m353 : 16|1@1+ (1,0) [0|1] "" Vector__XXX
 SG_ TRCM_a353_overcurrentError m353 : 17|1@1+ (1,0) [0|1] "" Vector__XXX
 SG_ TRCM_a353_overvoltageError m353 : 18|1@1+ (1,0) [0|1] "" Vector__XXX
 SG_ TRCM_a353_currentMonitorTimer m353 : 24|8@1+ (16,0) [0|4080] "us" Vector__XXX
 SG_ TRCM_a354_groundLossError m354 : 16|1@1+ (1,0) [0|1] "" Vector__XXX
 SG_ TRCM_a354_overcurrentError m354 : 17|1@1+ (1,0) [0|1] "" Vector__XXX
 SG_ TRCM_a354_overvoltageError m354 : 18|1@1+ (1,0) [0|1] "" Vector__XXX
 SG_ TRCM_a354_currentMonitorTimer m354 : 24|8@1+ (16,0) [0|4080] "us" Vector__XXX
 SG_ TRCM_a355_groundLossError m355 : 16|1@1+ (1,0) [0|1] "" Vector__XXX
 SG_ TRCM_a355_overcurrentError m355 : 17|1@1+ (1,0) [0|1] "" Vector__XXX
 SG_ TRCM_a355_overvoltageError m355 : 18|1@1+ (1,0) [0|1] "" Vector__XXX
 SG_ TRCM_a355_currentMonitorTimer m355 : 24|8@1+ (16,0) [0|4080] "us" Vector__XXX
 SG_ TRCM_a400_deploymentLoopNumber m400 : 16|5@1+ (1,0) [0|31] "" Vector__XXX
 SG_ TRCM_a400_resistance m400 : 24|8@1+ (0.05,0) [0|12.7] "Ohms" Vector__XXX
 SG_ TRCM_a400_shortToGround m400 : 32|1@1+ (1,0) [0|1] "" Vector__XXX
 SG_ TRCM_a400_shortToBattery m400 : 33|1@1+ (1,0) [0|1] "" Vector__XXX
 SG_ TRCM_a400_shortToSelf m400 : 34|1@1+ (1,0) [0|1] "" Vector__XXX
 SG_ TRCM_a400_openCircuit m400 : 35|1@1+ (1,0) [0|1] "" Vector__XXX
 SG_ TRCM_a400_crossCoupled m400 : 36|1@1+ (1,0) [0|1] "" Vector__XXX
 SG_ TRCM_a400_resistanceOutOfSpec m400 : 37|1@1+ (1,0) [0|1] "" Vector__XXX
 SG_ TRCM_a401_deploymentLoopNumber m401 : 16|5@1+ (1,0) [0|31] "" Vector__XXX
 SG_ TRCM_a401_resistance m401 : 24|8@1+ (0.05,0) [0|12.7] "Ohms" Vector__XXX
 SG_ TRCM_a401_shortToGround m401 : 32|1@1+ (1,0) [0|1] "" Vector__XXX
 SG_ TRCM_a401_shortToBattery m401 : 33|1@1+ (1,0) [0|1] "" Vector__XXX
 SG_ TRCM_a401_shortToSelf m401 : 34|1@1+ (1,0) [0|1] "" Vector__XXX
 SG_ TRCM_a401_openCircuit m401 : 35|1@1+ (1,0) [0|1] "" Vector__XXX
 SG_ TRCM_a401_crossCoupled m401 : 36|1@1+ (1,0) [0|1] "" Vector__XXX
 SG_ TRCM_a401_resistanceOutOfSpec m401 : 37|1@1+ (1,0) [0|1] "" Vector__XXX
 SG_ TRCM_a402_deploymentLoopNumber m402 : 16|5@1+ (1,0) [0|31] "" Vector__XXX
 SG_ TRCM_a402_resistance m402 : 24|8@1+ (0.05,0) [0|12.7] "Ohms" Vector__XXX
 SG_ TRCM_a402_shortToGround m402 : 32|1@1+ (1,0) [0|1] "" Vector__XXX
 SG_ TRCM_a402_shortToBattery m402 : 33|1@1+ (1,0) [0|1] "" Vector__XXX
 SG_ TRCM_a402_shortToSelf m402 : 34|1@1+ (1,0) [0|1] "" Vector__XXX
 SG_ TRCM_a402_openCircuit m402 : 35|1@1+ (1,0) [0|1] "" Vector__XXX
 SG_ TRCM_a402_crossCoupled m402 : 36|1@1+ (1,0) [0|1] "" Vector__XXX
 SG_ TRCM_a402_resistanceOutOfSpec m402 : 37|1@1+ (1,0) [0|1] "" Vector__XXX
 SG_ TRCM_a403_deploymentLoopNumber m403 : 16|5@1+ (1,0) [0|31] "" Vector__XXX
 SG_ TRCM_a403_resistance m403 : 24|8@1+ (0.05,0) [0|12.7] "Ohms" Vector__XXX
 SG_ TRCM_a403_shortToGround m403 : 32|1@1+ (1,0) [0|1] "" Vector__XXX
 SG_ TRCM_a403_shortToBattery m403 : 33|1@1+ (1,0) [0|1] "" Vector__XXX
 SG_ TRCM_a403_shortToSelf m403 : 34|1@1+ (1,0) [0|1] "" Vector__XXX
 SG_ TRCM_a403_openCircuit m403 : 35|1@1+ (1,0) [0|1] "" Vector__XXX
 SG_ TRCM_a403_crossCoupled m403 : 36|1@1+ (1,0) [0|1] "" Vector__XXX
 SG_ TRCM_a403_resistanceOutOfSpec m403 : 37|1@1+ (1,0) [0|1] "" Vector__XXX
 SG_ TRCM_a404_deploymentLoopNumber m404 : 16|5@1+ (1,0) [0|31] "" Vector__XXX
 SG_ TRCM_a404_resistance m404 : 24|8@1+ (0.05,0) [0|12.7] "Ohms" Vector__XXX
 SG_ TRCM_a404_shortToGround m404 : 32|1@1+ (1,0) [0|1] "" Vector__XXX
 SG_ TRCM_a404_shortToBattery m404 : 33|1@1+ (1,0) [0|1] "" Vector__XXX
 SG_ TRCM_a404_shortToSelf m404 : 34|1@1+ (1,0) [0|1] "" Vector__XXX
 SG_ TRCM_a404_openCircuit m404 : 35|1@1+ (1,0) [0|1] "" Vector__XXX
 SG_ TRCM_a404_crossCoupled m404 : 36|1@1+ (1,0) [0|1] "" Vector__XXX
 SG_ TRCM_a404_resistanceOutOfSpec m404 : 37|1@1+ (1,0) [0|1] "" Vector__XXX
 SG_ TRCM_a405_deploymentLoopNumber m405 : 16|5@1+ (1,0) [0|31] "" Vector__XXX
 SG_ TRCM_a405_resistance m405 : 24|8@1+ (0.05,0) [0|12.7] "Ohms" Vector__XXX
 SG_ TRCM_a405_shortToGround m405 : 32|1@1+ (1,0) [0|1] "" Vector__XXX
 SG_ TRCM_a405_shortToBattery m405 : 33|1@1+ (1,0) [0|1] "" Vector__XXX
 SG_ TRCM_a405_shortToSelf m405 : 34|1@1+ (1,0) [0|1] "" Vector__XXX
 SG_ TRCM_a405_openCircuit m405 : 35|1@1+ (1,0) [0|1] "" Vector__XXX
 SG_ TRCM_a405_crossCoupled m405 : 36|1@1+ (1,0) [0|1] "" Vector__XXX
 SG_ TRCM_a405_resistanceOutOfSpec m405 : 37|1@1+ (1,0) [0|1] "" Vector__XXX
 SG_ TRCM_a406_deploymentLoopNumber m406 : 16|5@1+ (1,0) [0|31] "" Vector__XXX
 SG_ TRCM_a406_resistance m406 : 24|8@1+ (0.05,0) [0|12.7] "Ohms" Vector__XXX
 SG_ TRCM_a406_shortToGround m406 : 32|1@1+ (1,0) [0|1] "" Vector__XXX
 SG_ TRCM_a406_shortToBattery m406 : 33|1@1+ (1,0) [0|1] "" Vector__XXX
 SG_ TRCM_a406_shortToSelf m406 : 34|1@1+ (1,0) [0|1] "" Vector__XXX
 SG_ TRCM_a406_openCircuit m406 : 35|1@1+ (1,0) [0|1] "" Vector__XXX
 SG_ TRCM_a406_crossCoupled m406 : 36|1@1+ (1,0) [0|1] "" Vector__XXX
 SG_ TRCM_a406_resistanceOutOfSpec m406 : 37|1@1+ (1,0) [0|1] "" Vector__XXX
 SG_ TRCM_a408_deploymentLoopNumber m408 : 16|5@1+ (1,0) [0|31] "" Vector__XXX
 SG_ TRCM_a408_resistance m408 : 24|8@1+ (0.05,0) [0|12.7] "Ohms" Vector__XXX
 SG_ TRCM_a408_shortToGround m408 : 32|1@1+ (1,0) [0|1] "" Vector__XXX
 SG_ TRCM_a408_shortToBattery m408 : 33|1@1+ (1,0) [0|1] "" Vector__XXX
 SG_ TRCM_a408_shortToSelf m408 : 34|1@1+ (1,0) [0|1] "" Vector__XXX
 SG_ TRCM_a408_openCircuit m408 : 35|1@1+ (1,0) [0|1] "" Vector__XXX
 SG_ TRCM_a408_crossCoupled m408 : 36|1@1+ (1,0) [0|1] "" Vector__XXX
 SG_ TRCM_a408_resistanceOutOfSpec m408 : 37|1@1+ (1,0) [0|1] "" Vector__XXX
 SG_ TRCM_a409_deploymentLoopNumber m409 : 16|5@1+ (1,0) [0|31] "" Vector__XXX
 SG_ TRCM_a409_resistance m409 : 24|8@1+ (0.05,0) [0|12.7] "Ohms" Vector__XXX
 SG_ TRCM_a409_shortToGround m409 : 32|1@1+ (1,0) [0|1] "" Vector__XXX
 SG_ TRCM_a409_shortToBattery m409 : 33|1@1+ (1,0) [0|1] "" Vector__XXX
 SG_ TRCM_a409_shortToSelf m409 : 34|1@1+ (1,0) [0|1] "" Vector__XXX
 SG_ TRCM_a409_openCircuit m409 : 35|1@1+ (1,0) [0|1] "" Vector__XXX
 SG_ TRCM_a409_crossCoupled m409 : 36|1@1+ (1,0) [0|1] "" Vector__XXX
 SG_ TRCM_a409_resistanceOutOfSpec m409 : 37|1@1+ (1,0) [0|1] "" Vector__XXX
 SG_ TRCM_a410_deploymentLoopNumber m410 : 16|5@1+ (1,0) [0|31] "" Vector__XXX
 SG_ TRCM_a410_resistance m410 : 24|8@1+ (0.05,0) [0|12.7] "Ohms" Vector__XXX
 SG_ TRCM_a410_shortToGround m410 : 32|1@1+ (1,0) [0|1] "" Vector__XXX
 SG_ TRCM_a410_shortToBattery m410 : 33|1@1+ (1,0) [0|1] "" Vector__XXX
 SG_ TRCM_a410_shortToSelf m410 : 34|1@1+ (1,0) [0|1] "" Vector__XXX
 SG_ TRCM_a410_openCircuit m410 : 35|1@1+ (1,0) [0|1] "" Vector__XXX
 SG_ TRCM_a410_crossCoupled m410 : 36|1@1+ (1,0) [0|1] "" Vector__XXX
 SG_ TRCM_a410_resistanceOutOfSpec m410 : 37|1@1+ (1,0) [0|1] "" Vector__XXX
 SG_ TRCM_a411_deploymentLoopNumber m411 : 16|5@1+ (1,0) [0|31] "" Vector__XXX
 SG_ TRCM_a411_resistance m411 : 24|8@1+ (0.05,0) [0|12.7] "Ohms" Vector__XXX
 SG_ TRCM_a411_shortToGround m411 : 32|1@1+ (1,0) [0|1] "" Vector__XXX
 SG_ TRCM_a411_shortToBattery m411 : 33|1@1+ (1,0) [0|1] "" Vector__XXX
 SG_ TRCM_a411_shortToSelf m411 : 34|1@1+ (1,0) [0|1] "" Vector__XXX
 SG_ TRCM_a411_openCircuit m411 : 35|1@1+ (1,0) [0|1] "" Vector__XXX
 SG_ TRCM_a411_crossCoupled m411 : 36|1@1+ (1,0) [0|1] "" Vector__XXX
 SG_ TRCM_a411_resistanceOutOfSpec m411 : 37|1@1+ (1,0) [0|1] "" Vector__XXX
 SG_ TRCM_a412_deploymentLoopNumber m412 : 16|5@1+ (1,0) [0|31] "" Vector__XXX
 SG_ TRCM_a412_resistance m412 : 24|8@1+ (0.05,0) [0|12.7] "Ohms" Vector__XXX
 SG_ TRCM_a412_shortToGround m412 : 32|1@1+ (1,0) [0|1] "" Vector__XXX
 SG_ TRCM_a412_shortToBattery m412 : 33|1@1+ (1,0) [0|1] "" Vector__XXX
 SG_ TRCM_a412_shortToSelf m412 : 34|1@1+ (1,0) [0|1] "" Vector__XXX
 SG_ TRCM_a412_openCircuit m412 : 35|1@1+ (1,0) [0|1] "" Vector__XXX
 SG_ TRCM_a412_crossCoupled m412 : 36|1@1+ (1,0) [0|1] "" Vector__XXX
 SG_ TRCM_a412_resistanceOutOfSpec m412 : 37|1@1+ (1,0) [0|1] "" Vector__XXX
 SG_ TRCM_a413_deploymentLoopNumber m413 : 16|5@1+ (1,0) [0|31] "" Vector__XXX
 SG_ TRCM_a413_resistance m413 : 24|8@1+ (0.05,0) [0|12.7] "Ohms" Vector__XXX
 SG_ TRCM_a413_shortToGround m413 : 32|1@1+ (1,0) [0|1] "" Vector__XXX
 SG_ TRCM_a413_shortToBattery m413 : 33|1@1+ (1,0) [0|1] "" Vector__XXX
 SG_ TRCM_a413_shortToSelf m413 : 34|1@1+ (1,0) [0|1] "" Vector__XXX
 SG_ TRCM_a413_openCircuit m413 : 35|1@1+ (1,0) [0|1] "" Vector__XXX
 SG_ TRCM_a413_crossCoupled m413 : 36|1@1+ (1,0) [0|1] "" Vector__XXX
 SG_ TRCM_a413_resistanceOutOfSpec m413 : 37|1@1+ (1,0) [0|1] "" Vector__XXX
 SG_ TRCM_a414_deploymentLoopNumber m414 : 16|5@1+ (1,0) [0|31] "" Vector__XXX
 SG_ TRCM_a414_resistance m414 : 24|8@1+ (0.05,0) [0|12.7] "Ohms" Vector__XXX
 SG_ TRCM_a414_shortToGround m414 : 32|1@1+ (1,0) [0|1] "" Vector__XXX
 SG_ TRCM_a414_shortToBattery m414 : 33|1@1+ (1,0) [0|1] "" Vector__XXX
 SG_ TRCM_a414_shortToSelf m414 : 34|1@1+ (1,0) [0|1] "" Vector__XXX
 SG_ TRCM_a414_openCircuit m414 : 35|1@1+ (1,0) [0|1] "" Vector__XXX
 SG_ TRCM_a414_crossCoupled m414 : 36|1@1+ (1,0) [0|1] "" Vector__XXX
 SG_ TRCM_a414_resistanceOutOfSpec m414 : 37|1@1+ (1,0) [0|1] "" Vector__XXX
 SG_ TRCM_a415_deploymentLoopNumber m415 : 16|5@1+ (1,0) [0|31] "" Vector__XXX
 SG_ TRCM_a415_resistance m415 : 24|8@1+ (0.05,0) [0|12.7] "Ohms" Vector__XXX
 SG_ TRCM_a415_shortToGround m415 : 32|1@1+ (1,0) [0|1] "" Vector__XXX
 SG_ TRCM_a415_shortToBattery m415 : 33|1@1+ (1,0) [0|1] "" Vector__XXX
 SG_ TRCM_a415_shortToSelf m415 : 34|1@1+ (1,0) [0|1] "" Vector__XXX
 SG_ TRCM_a415_openCircuit m415 : 35|1@1+ (1,0) [0|1] "" Vector__XXX
 SG_ TRCM_a415_crossCoupled m415 : 36|1@1+ (1,0) [0|1] "" Vector__XXX
 SG_ TRCM_a415_resistanceOutOfSpec m415 : 37|1@1+ (1,0) [0|1] "" Vector__XXX
 SG_ TRCM_a416_deploymentLoopNumber m416 : 16|5@1+ (1,0) [0|31] "" Vector__XXX
 SG_ TRCM_a416_resistance m416 : 24|8@1+ (0.05,0) [0|12.7] "Ohms" Vector__XXX
 SG_ TRCM_a416_shortToGround m416 : 32|1@1+ (1,0) [0|1] "" Vector__XXX
 SG_ TRCM_a416_shortToBattery m416 : 33|1@1+ (1,0) [0|1] "" Vector__XXX
 SG_ TRCM_a416_shortToSelf m416 : 34|1@1+ (1,0) [0|1] "" Vector__XXX
 SG_ TRCM_a416_openCircuit m416 : 35|1@1+ (1,0) [0|1] "" Vector__XXX
 SG_ TRCM_a416_crossCoupled m416 : 36|1@1+ (1,0) [0|1] "" Vector__XXX
 SG_ TRCM_a416_resistanceOutOfSpec m416 : 37|1@1+ (1,0) [0|1] "" Vector__XXX
 SG_ TRCM_a417_deploymentLoopNumber m417 : 16|5@1+ (1,0) [0|31] "" Vector__XXX
 SG_ TRCM_a417_resistance m417 : 24|8@1+ (0.05,0) [0|12.7] "Ohms" Vector__XXX
 SG_ TRCM_a417_shortToGround m417 : 32|1@1+ (1,0) [0|1] "" Vector__XXX
 SG_ TRCM_a417_shortToBattery m417 : 33|1@1+ (1,0) [0|1] "" Vector__XXX
 SG_ TRCM_a417_shortToSelf m417 : 34|1@1+ (1,0) [0|1] "" Vector__XXX
 SG_ TRCM_a417_openCircuit m417 : 35|1@1+ (1,0) [0|1] "" Vector__XXX
 SG_ TRCM_a417_crossCoupled m417 : 36|1@1+ (1,0) [0|1] "" Vector__XXX
 SG_ TRCM_a417_resistanceOutOfSpec m417 : 37|1@1+ (1,0) [0|1] "" Vector__XXX
 SG_ TRCM_a418_deploymentLoopNumber m418 : 16|5@1+ (1,0) [0|31] "" Vector__XXX
 SG_ TRCM_a418_resistance m418 : 24|8@1+ (0.05,0) [0|12.7] "Ohms" Vector__XXX
 SG_ TRCM_a418_shortToGround m418 : 32|1@1+ (1,0) [0|1] "" Vector__XXX
 SG_ TRCM_a418_shortToBattery m418 : 33|1@1+ (1,0) [0|1] "" Vector__XXX
 SG_ TRCM_a418_shortToSelf m418 : 34|1@1+ (1,0) [0|1] "" Vector__XXX
 SG_ TRCM_a418_openCircuit m418 : 35|1@1+ (1,0) [0|1] "" Vector__XXX
 SG_ TRCM_a418_crossCoupled m418 : 36|1@1+ (1,0) [0|1] "" Vector__XXX
 SG_ TRCM_a418_resistanceOutOfSpec m418 : 37|1@1+ (1,0) [0|1] "" Vector__XXX
 SG_ TRCM_a419_deploymentLoopNumber m419 : 16|5@1+ (1,0) [0|31] "" Vector__XXX
 SG_ TRCM_a419_resistance m419 : 24|8@1+ (0.05,0) [0|12.7] "Ohms" Vector__XXX
 SG_ TRCM_a419_shortToGround m419 : 32|1@1+ (1,0) [0|1] "" Vector__XXX
 SG_ TRCM_a419_shortToBattery m419 : 33|1@1+ (1,0) [0|1] "" Vector__XXX
 SG_ TRCM_a419_shortToSelf m419 : 34|1@1+ (1,0) [0|1] "" Vector__XXX
 SG_ TRCM_a419_openCircuit m419 : 35|1@1+ (1,0) [0|1] "" Vector__XXX
 SG_ TRCM_a419_crossCoupled m419 : 36|1@1+ (1,0) [0|1] "" Vector__XXX
 SG_ TRCM_a419_resistanceOutOfSpec m419 : 37|1@1+ (1,0) [0|1] "" Vector__XXX
 SG_ TRCM_a420_deploymentLoopNumber m420 : 16|5@1+ (1,0) [0|31] "" Vector__XXX
 SG_ TRCM_a420_resistance m420 : 24|8@1+ (0.05,0) [0|12.7] "Ohms" Vector__XXX
 SG_ TRCM_a420_shortToGround m420 : 32|1@1+ (1,0) [0|1] "" Vector__XXX
 SG_ TRCM_a420_shortToBattery m420 : 33|1@1+ (1,0) [0|1] "" Vector__XXX
 SG_ TRCM_a420_shortToSelf m420 : 34|1@1+ (1,0) [0|1] "" Vector__XXX
 SG_ TRCM_a420_openCircuit m420 : 35|1@1+ (1,0) [0|1] "" Vector__XXX
 SG_ TRCM_a420_crossCoupled m420 : 36|1@1+ (1,0) [0|1] "" Vector__XXX
 SG_ TRCM_a420_resistanceOutOfSpec m420 : 37|1@1+ (1,0) [0|1] "" Vector__XXX
 SG_ TRCM_a421_deploymentLoopNumber m421 : 16|5@1+ (1,0) [0|31] "" Vector__XXX
 SG_ TRCM_a421_resistance m421 : 24|8@1+ (0.05,0) [0|12.7] "Ohms" Vector__XXX
 SG_ TRCM_a421_shortToGround m421 : 32|1@1+ (1,0) [0|1] "" Vector__XXX
 SG_ TRCM_a421_shortToBattery m421 : 33|1@1+ (1,0) [0|1] "" Vector__XXX
 SG_ TRCM_a421_shortToSelf m421 : 34|1@1+ (1,0) [0|1] "" Vector__XXX
 SG_ TRCM_a421_openCircuit m421 : 35|1@1+ (1,0) [0|1] "" Vector__XXX
 SG_ TRCM_a421_crossCoupled m421 : 36|1@1+ (1,0) [0|1] "" Vector__XXX
 SG_ TRCM_a421_resistanceOutOfSpec m421 : 37|1@1+ (1,0) [0|1] "" Vector__XXX
 SG_ TRCM_a422_deploymentLoopNumber m422 : 16|5@1+ (1,0) [0|31] "" Vector__XXX
 SG_ TRCM_a422_resistance m422 : 24|8@1+ (0.05,0) [0|12.7] "Ohms" Vector__XXX
 SG_ TRCM_a422_shortToGround m422 : 32|1@1+ (1,0) [0|1] "" Vector__XXX
 SG_ TRCM_a422_shortToBattery m422 : 33|1@1+ (1,0) [0|1] "" Vector__XXX
 SG_ TRCM_a422_shortToSelf m422 : 34|1@1+ (1,0) [0|1] "" Vector__XXX
 SG_ TRCM_a422_openCircuit m422 : 35|1@1+ (1,0) [0|1] "" Vector__XXX
 SG_ TRCM_a422_crossCoupled m422 : 36|1@1+ (1,0) [0|1] "" Vector__XXX
 SG_ TRCM_a422_resistanceOutOfSpec m422 : 37|1@1+ (1,0) [0|1] "" Vector__XXX
 SG_ TRCM_a423_deploymentLoopNumber m423 : 16|5@1+ (1,0) [0|31] "" Vector__XXX
 SG_ TRCM_a423_resistance m423 : 24|8@1+ (0.05,0) [0|12.7] "Ohms" Vector__XXX
 SG_ TRCM_a423_shortToGround m423 : 32|1@1+ (1,0) [0|1] "" Vector__XXX
 SG_ TRCM_a423_shortToBattery m423 : 33|1@1+ (1,0) [0|1] "" Vector__XXX
 SG_ TRCM_a423_shortToSelf m423 : 34|1@1+ (1,0) [0|1] "" Vector__XXX
 SG_ TRCM_a423_openCircuit m423 : 35|1@1+ (1,0) [0|1] "" Vector__XXX
 SG_ TRCM_a423_crossCoupled m423 : 36|1@1+ (1,0) [0|1] "" Vector__XXX
 SG_ TRCM_a423_resistanceOutOfSpec m423 : 37|1@1+ (1,0) [0|1] "" Vector__XXX

BO_TX_BU_ 881 : RCM;
BO_TX_BU_ 1415 : TCU2;
BO_TX_BU_ 1413 : TCU2;
BO_TX_BU_ 1414 : TCU2;
BO_TX_BU_ 1412 : TCU2;
BO_TX_BU_ 1159 : TCU;
BO_TX_BU_ 1157 : TCU;
BO_TX_BU_ 1158 : TCU;
BO_TX_BU_ 1155 : TCU;
BO_TX_BU_ 1298 : TRCM;
CM_ SG_ 1297 RCM_a117_eventDriveOrientation "Restraint control module: a117 event drive orientation";
CM_ SG_ 1297 RCM_a117_imuZaccelChnlMonitTmp "Restraint control module: a117 imu zaccel chnl monit tmp";
CM_ SG_ 1297 RCM_a117_imuZaccelChnlMonitPerm "Restraint control module: a117 imu zaccel chnl monit perm";
CM_ SG_ 1297 RCM_a117_eventIDFsignal "Restraint control module: a117 event ID fsignal";
CM_ SG_ 1297 RCM_a117_eventFrontLeftSeatbelt "Restraint control module: a117 event front left seatbelt";
CM_ SG_ 1297 RCM_a117_eventFrontRightSeatbelt "Restraint control module: a117 event front right seatbelt";
CM_ SG_ 1297 RCM_a117_eventVehicleSpeed "Restraint control module: a117 event vehicle speed";
CM_ SG_ 1297 RCM_a117_eventSteeringAngle "Restraint control module: a117 event steering angle";
CM_ SG_ 1297 RCM_a117_eventDriverBrakeApply "Restraint control module: a117 event driver brake apply; raw 3 = signal not available (SNA)";
CM_ SG_ 1297 RCM_a117_eventAccelPedalPos "Restraint control module: a117 event accel pedal pos; raw 255 = signal not available (SNA)";
CM_ SG_ 1297 RCM_a118_eventArmStatus "Restraint control module: a118 event arm status";
CM_ SG_ 1297 RCM_a118_eventFactoryMode "Restraint control module: a118 event factory mode";
CM_ SG_ 1297 RCM_a118_eventDiagEnabled "Restraint control module: a118 event diag enabled";
CM_ SG_ 1297 RCM_a118_eventDriveOrientation "Restraint control module: a118 event drive orientation";
CM_ SG_ 1297 RCM_a118_imuInPlaneSnsrMonitTmp "Restraint control module: a118 imu in plane snsr monit tmp";
CM_ SG_ 1297 RCM_a118_imuInPlaneSnsrMonitPerm "Restraint control module: a118 imu in plane snsr monit perm";
CM_ SG_ 1297 RCM_a118_eventIDFsignal "Restraint control module: a118 event ID fsignal";
CM_ SG_ 1297 RCM_a118_eventFrontLeftSeatbelt "Restraint control module: a118 event front left seatbelt";
CM_ SG_ 1297 RCM_a118_eventFrontRightSeatbelt "Restraint control module: a118 event front right seatbelt";
CM_ SG_ 1297 RCM_a118_eventVehicleSpeed "Restraint control module: a118 event vehicle speed";
CM_ SG_ 1297 RCM_a118_eventSteeringAngle "Restraint control module: a118 event steering angle";
CM_ SG_ 1297 RCM_a118_eventDriverBrakeApply "Restraint control module: a118 event driver brake apply; raw 3 = signal not available (SNA)";
CM_ SG_ 1297 RCM_a118_eventAccelPedalPos "Restraint control module: a118 event accel pedal pos; raw 255 = signal not available (SNA)";
CM_ BO_ 881 "Restraint control module message: alert matrix";
CM_ SG_ 881 RCM_matrixIndex "Restraint control module: matrix index";
CM_ SG_ 881 RCM_a000_crashDetected "Restraint control module: a000 crash detected";
CM_ SG_ 881 RCM_a001_nearDeploy "Restraint control module: a001 near deploy";
CM_ SG_ 881 RCM_a002_airbagsNotArmed "Restraint control module: a002 airbags not armed";
CM_ SG_ 881 RCM_a003_warningIndicator "Restraint control module: a003 warning indicator";
CM_ SG_ 881 RCM_a004_internalFault "Restraint control module: a004 internal fault";
CM_ SG_ 881 RCM_a005_crcError "Restraint control module: a005 crc error";
CM_ SG_ 881 RCM_a006_batteryVoltageRange "Restraint control module: a006 battery voltage range";
CM_ SG_ 881 RCM_a007_powerSupplyExternal "Restraint control module: a007 power supply external";
CM_ SG_ 881 RCM_a008_powerSupplyInternal "Restraint control module: a008 power supply internal";
CM_ SG_ 881 RCM_a009_reprogramLimit "Restraint control module: a009 reprogram limit";
CM_ SG_ 881 RCM_a010_scmDisabled "Restraint control module: a010 scm disabled";
CM_ SG_ 881 RCM_a011_eepromDataLocked "Restraint control module: a011 eeprom data locked";
CM_ SG_ 881 RCM_a012_vinStorage "Restraint control module: a012 vin storage";
CM_ SG_ 881 RCM_a013_driverOrientation "Restraint control module: a013 driver orientation";
CM_ SG_ 881 RCM_a014_driverABStage1 "Restraint control module: a014 driver AB stage1";
CM_ SG_ 881 RCM_a015_driverABStage2 "Restraint control module: a015 driver AB stage2";
CM_ SG_ 881 RCM_a016_passABStage1 "Restraint control module: a016 pass AB stage1";
CM_ SG_ 881 RCM_a017_passABStage2 "Restraint control module: a017 pass AB stage2";
CM_ SG_ 881 RCM_a018_passengerActiveVent "Restraint control module: a018 passenger active vent";
CM_ SG_ 881 RCM_a019_pretenShldrFrontLeft "Restraint control module: a019 preten shldr front left";
CM_ SG_ 881 RCM_a020_pretenShldFrontRight "Restraint control module: a020 preten shld front right";
CM_ SG_ 881 RCM_a021_pretenLapFrontLeft "Restraint control module: a021 preten lap front left";
CM_ SG_ 881 RCM_a022_pretenLapFrontRight "Restraint control module: a022 preten lap front right";
CM_ SG_ 881 RCM_a023_loadLimiterLeftSide "Restraint control module: a023 load limiter left side";
CM_ SG_ 881 RCM_a024_loadLimiterRightSide "Restraint control module: a024 load limiter right side";
CM_ SG_ 881 RCM_a025_kneeABDriver "Restraint control module: a025 knee AB driver";
CM_ SG_ 881 RCM_a026_kneeABFrontPassenger "Restraint control module: a026 knee AB front passenger";
CM_ SG_ 881 RCM_a027_sideAB1stRowLeft "Restraint control module: a027 side ab1st row left";
CM_ SG_ 881 RCM_a028_sideAB1stRowRight "Restraint control module: a028 side ab1st row right";
CM_ SG_ 881 RCM_a029_driverABActiveVent "Restraint control module: a029 driver AB active vent";
CM_ SG_ 881 RCM_a030_farSideInboardAirbag "Restraint control module: a030 far side inboard airbag";
CM_ SG_ 881 RCM_a031_frontCenterAirbag "Restraint control module: a031 front center airbag";
CM_ SG_ 881 RCM_a032_curtainABLeft "Restraint control module: a032 curtain AB left";
CM_ SG_ 881 RCM_a033_curtainABRight "Restraint control module: a033 curtain AB right";
CM_ SG_ 881 RCM_a034_preten2ndRowLeft "Restraint control module: a034 preten2nd row left";
CM_ SG_ 881 RCM_a035_preten2ndRowRight "Restraint control module: a035 preten2nd row right";
CM_ SG_ 881 RCM_a036_curAB2ndRowLeft "Restraint control module: a036 cur ab2nd row left";
CM_ SG_ 881 RCM_a037_curAB2ndRowRight "Restraint control module: a037 cur ab2nd row right";
CM_ SG_ 881 RCM_a038_unusedA "Restraint control module: a038 unused a";
CM_ SG_ 881 RCM_a039_unusedB "Restraint control module: a039 unused b";
CM_ SG_ 881 RCM_a040_hoodActuatorRight "Restraint control module: a040 hood actuator right";
CM_ SG_ 881 RCM_a041_hoodActuatorLeft "Restraint control module: a041 hood actuator left";
CM_ SG_ 881 RCM_a042_ens1Line "Restraint control module: a042 ens1 line";
CM_ SG_ 881 RCM_a043_ens2Line "Restraint control module: a043 ens2 line";
CM_ SG_ 881 RCM_a044_upFrontSensorLeft "Restraint control module: a044 up front sensor left";
CM_ SG_ 881 RCM_a045_upFrontSensorRight "Restraint control module: a045 up front sensor right";
CM_ SG_ 881 RCM_a046_sideAccelBPillarLeft "Restraint control module: a046 side accel b pillar left";
CM_ SG_ 881 RCM_a047_sideAccelBPillarRight "Restraint control module: a047 side accel b pillar right";
CM_ SG_ 881 RCM_a048_sideAccelCPillarLeft "Restraint control module: a048 side accel c pillar left";
CM_ SG_ 881 RCM_a049_sideAccelCPillarRight "Restraint control module: a049 side accel c pillar right";
CM_ SG_ 881 RCM_a050_upFrontSensorCenter "Restraint control module: a050 up front sensor center";
CM_ SG_ 881 RCM_a051_pressureFrontLftDoor "Restraint control module: a051 pressure front lft door";
CM_ SG_ 881 RCM_a052_pressureFrontRtDoor "Restraint control module: a052 pressure front rt door";
CM_ SG_ 881 RCM_a053_pressurePedProLeft "Restraint control module: a053 pressure ped pro left";
CM_ SG_ 881 RCM_a054_pressurePedProRight "Restraint control module: a054 pressure ped pro right";
CM_ SG_ 881 RCM_a055_inertialMeasurement "Restraint control module: a055 inertial measurement";
CM_ SG_ 881 RCM_a056_passengerFrontOCS "Restraint control module: a056 passenger front OCS";
CM_ SG_ 881 RCM_a057_driverOCS "Restraint control module: a057 driver OCS";
CM_ SG_ 881 RCM_a058_buckle1stRowLeft "Restraint control module: a058 buckle1st row left";
CM_ SG_ 881 RCM_a059_buckle1stRowRight "Restraint control module: a059 buckle1st row right";
CM_ SG_ 881 RCM_a060_stpsLeft "Restraint control module: a060 stps left";
CM_ SG_ 881 RCM_a061_stpsRight "Restraint control module: a061 stps right";
CM_ SG_ 881 RCM_a062_alrSwitch "Restraint control module: a062 alr switch";
CM_ SG_ 881 RCM_a063_sbsw2ndRowRight "Restraint control module: a063 sbsw2nd row right";
CM_ SG_ 881 RCM_a064_hardwareCodingPin1 "Restraint control module: a064 hardware coding pin1";
CM_ SG_ 881 RCM_a065_driverOrientConfigPin "Restraint control module: a065 driver orient config pin";
CM_ SG_ 881 RCM_a066_seatBackSw2ndRowLeft "Restraint control module: a066 seat back sw2nd row left";
CM_ SG_ 881 RCM_a067_comCANInitFailure "Restraint control module: a067 com CAN init failure";
CM_ SG_ 881 RCM_a068_comChassisBusOff "Restraint control module: a068 com chassis bus off";
CM_ SG_ 881 RCM_a069_comCHCANPH7 "Restraint control module: a069 com CHCANPH7";
CM_ SG_ 881 RCM_a070_comCHCANPH8 "Restraint control module: a070 com CHCANPH8";
CM_ SG_ 881 RCM_a071_comCHCANPH9 "Restraint control module: a071 com CHCANPH9";
CM_ SG_ 881 RCM_a072_comUnused "Restraint control module: a072 com unused";
CM_ SG_ 881 RCM_a073_comCHCANPH4 "Restraint control module: a073 com CHCANPH4";
CM_ SG_ 881 RCM_a074_comCHCANPH5 "Restraint control module: a074 com CHCANPH5";
CM_ SG_ 881 RCM_a075_comCHCANPH6 "Restraint control module: a075 com CHCANPH6";
CM_ SG_ 881 RCM_a076_comEPBLStatus "Restraint control module: a076 com EPBL status";
CM_ SG_ 881 RCM_a077_comEPBRStatus "Restraint control module: a077 com EPBR status";
CM_ SG_ 881 RCM_a078_comOCS1PStatus "Restraint control module: a078 com OCS1 p status";
CM_ SG_ 881 RCM_a079_comOCS1DStatus "Restraint control module: a079 com OCS1 d status";
CM_ SG_ 881 RCM_a080_comGTWACS "Restraint control module: a080 com GTWACS";
CM_ SG_ 881 RCM_a081_comVCFRONTLVPwr "Restraint control module: a081 com VCFRONTLV pwr";
CM_ SG_ 881 RCM_a082_comUIodo "Restraint control module: a082 com u iodo";
CM_ SG_ 881 RCM_a083_comGTWCarState "Restraint control module: a083 com GTW car state";
CM_ SG_ 881 RCM_a084_comTPMSStatus "Restraint control module: a084 com TPMS status";
CM_ SG_ 881 RCM_a085_comGTWCarConfig "Restraint control module: a085 com GTW car config";
CM_ SG_ 881 RCM_a086_comVINMIA "Restraint control module: a086 com VINMIA";
CM_ SG_ 881 RCM_a087_comCANSilent "Restraint control module: a087 com CAN silent";
CM_ SG_ 881 RCM_a088_comCHCANPH2 "Restraint control module: a088 com CHCANPH2";
CM_ SG_ 881 RCM_a089_comCHCANPH3 "Restraint control module: a089 com CHCANPH3";
CM_ SG_ 881 RCM_a090_comPartyBusOff "Restraint control module: a090 com party bus off";
CM_ SG_ 881 RCM_a091_comEPAS3PsysStatus "Restraint control module: a091 com EPAS3 psys status";
CM_ SG_ 881 RCM_a092_comDASISF "Restraint control module: a092 com DASISF";
CM_ SG_ 881 RCM_a093_comVCLEFTStatus "Restraint control module: a093 com VCLEFT status";
CM_ SG_ 881 RCM_a094_comVCRIGHTStatus "Restraint control module: a094 com VCRIGHT status";
CM_ SG_ 881 RCM_a095_comESPstatus "Restraint control module: a095 com ES pstatus";
CM_ SG_ 881 RCM_a096_comESPwheelSpeeds "Restraint control module: a096 com ES pwheel speeds";
CM_ SG_ 881 RCM_a097_comDIspeed "Restraint control module: a097 com d ispeed";
CM_ SG_ 881 RCM_a098_comDIchassisControl "Restraint control module: a098 com d ichassis control";
CM_ SG_ 881 RCM_a099_comDItorque "Restraint control module: a099 com d itorque";
CM_ SG_ 881 RCM_a100_comDIsystemStatus "Restraint control module: a100 com d isystem status";
CM_ SG_ 881 RCM_a101_idfSystem "Restraint control module: a101 idf system";
CM_ SG_ 881 RCM_a102_imuYawR8OffstCompLim "Restraint control module: a102 imu yaw R8 offst comp lim";
CM_ SG_ 881 RCM_a103_imuPtchR8OffstCompLim "Restraint control module: a103 imu ptch R8 offst comp lim";
CM_ SG_ 881 RCM_a104_imuRollR8OffstCompLim "Restraint control module: a104 imu roll R8 offst comp lim";
CM_ SG_ 881 RCM_a105_imuLongAccOffstCompLim "Restraint control module: a105 imu long acc offst comp lim";
CM_ SG_ 881 RCM_a106_imuLatAccOffstCompLim "Restraint control module: a106 imu lat acc offst comp lim";
CM_ SG_ 881 RCM_a107_imuVertAccOffstCompLim "Restraint control module: a107 imu vert acc offst comp lim";
CM_ SG_ 881 RCM_a108_crashAlgoWakeup "Restraint control module: a108 crash algo wakeup";
CM_ SG_ 881 RCM_a109_abuseImmunity "Restraint control module: a109 abuse immunity";
CM_ SG_ 881 RCM_a110_factoryMode "Restraint control module: a110 factory mode";
CM_ SG_ 881 RCM_a111_diagnosticsEnabled "Restraint control module: a111 diagnostics enabled";
CM_ SG_ 881 RCM_a112_imuYawRate "Restraint control module: a112 imu yaw rate";
CM_ SG_ 881 RCM_a113_imuPitchRate "Restraint control module: a113 imu pitch rate";
CM_ SG_ 881 RCM_a114_imuRollRate "Restraint control module: a114 imu roll rate";
CM_ SG_ 881 RCM_a115_imuLinearAcceleration "Restraint control module: a115 imu linear acceleration";
CM_ SG_ 881 RCM_a116_imuLateralAcceleration "Restraint control module: a116 imu lateral acceleration";
CM_ SG_ 881 RCM_a117_imuVerticalAcceleration "Restraint control module: a117 imu vertical acceleration";
CM_ SG_ 881 RCM_a118_imuInPlaneAcceleration "Restraint control module: a118 imu in plane acceleration";
CM_ BO_ 1415 "TCU2 ECU message: sleep config";
CM_ SG_ 1415 TCU2_tc10Version "Indicates which version of Open Alliance's TC10 protocol is supported by the modem; raw 0 = signal not available (SNA)";
CM_ BO_ 1413 "TCU2 ECU message: alert log";
CM_ SG_ 1413 TCU2_alertID "TCU2 ECU: alert ID";
CM_ SG_ 1413 TCU2_alertState "TCU2 ECU: alert state";
CM_ SG_ 1413 TCU2_w001_FailCode "TCU2 ECU: w001 fail code";
CM_ SG_ 1413 TCU2_w002_RejCause "TCU2 ECU: w002 rej cause";
CM_ SG_ 1413 TCU2_w003_CallFailCode "TCU2 ECU: w003 call fail code";
CM_ SG_ 1413 TCU2_w004_MSDFailCode "TCU2 ECU: w004 MSD fail code";
CM_ SG_ 1413 TCU2_w006_Count "TCU2 ECU: w006 count";
CM_ SG_ 1413 TCU2_w007_Count "TCU2 ECU: w007 count";
CM_ SG_ 1413 TCU2_w009_CrashCode "TCU2 ECU: w009 crash code";
CM_ SG_ 1413 TCU2_w012_DataRAT "TCU2 ECU: w012 data RAT";
CM_ SG_ 1413 TCU2_w012_RSRP "TCU2 ECU: w012 RSRP";
CM_ SG_ 1413 TCU2_w012_RSRQ "TCU2 ECU: w012 RSRQ";
CM_ SG_ 1413 TCU2_w012_MNC "TCU2 ECU: w012 MNC";
CM_ SG_ 1413 TCU2_w012_AvgQueueUsage "TCU2 ECU: w012 avg queue usage";
CM_ SG_ 1413 TCU2_w012_NSAAvailable "TCU2 ECU: w012 NSA available";
CM_ SG_ 1413 TCU2_w013_DataRAT "TCU2 ECU: w013 data RAT";
CM_ SG_ 1413 TCU2_w013_RSRP "TCU2 ECU: w013 RSRP";
CM_ SG_ 1413 TCU2_w013_RSRQ "TCU2 ECU: w013 RSRQ";
CM_ SG_ 1413 TCU2_w013_MNC "TCU2 ECU: w013 MNC";
CM_ SG_ 1413 TCU2_w013_AvgQueueUsage "TCU2 ECU: w013 avg queue usage";
CM_ SG_ 1413 TCU2_w013_NSAAvailable "TCU2 ECU: w013 NSA available";
CM_ SG_ 1413 TCU2_w014_Reason "TCU2 ECU: w014 reason";
CM_ BO_ 1414 "TCU2 ECU message: alert matrix1";
CM_ SG_ 1414 TCU2_w001_IMSRegistrationFailed "TCU2 ECU: w001 IMS registration failed";
CM_ SG_ 1414 TCU2_w002_CellRegRejected "TCU2 ECU: w002 cell reg rejected";
CM_ SG_ 1414 TCU2_w003_ECallFailed "TCU2 ECU: w003 e call failed";
CM_ SG_ 1414 TCU2_w004_MSDTransmissionFailed "TCU2 ECU: w004 MSD transmission failed";
CM_ SG_ 1414 TCU2_w005_SIMSlotError "TCU2 ECU: w005 SIM slot error";
CM_ SG_ 1414 TCU2_w006_MpssUnavailable "TCU2 ECU: w006 mpss unavailable";
CM_ SG_ 1414 TCU2_w007_ModemUnreachable "TCU2 ECU: w007 modem unreachable";
CM_ SG_ 1414 TCU2_w008_KernelPanic "TCU2 ECU: w008 kernel panic";
CM_ SG_ 1414 TCU2_w009_WifiFirmwareCrash "TCU2 ECU: w009 wifi firmware crash";
CM_ SG_ 1414 TCU2_w010_WifiDumpDetected "TCU2 ECU: w010 wifi dump detected";
CM_ SG_ 1414 TCU2_w011_CellDumpDetected "TCU2 ECU: w011 cell dump detected";
CM_ SG_ 1414 TCU2_w012_UplinkDegraded "TCU2 ECU: w012 uplink degraded";
CM_ SG_ 1414 TCU2_w013_UplinkQueueFull "TCU2 ECU: w013 uplink queue full";
CM_ SG_ 1414 TCU2_w014_HostapdCrash "TCU2 ECU: w014 hostapd crash";
CM_ SG_ 1414 TCU2_w015_NPNSubscriptionActive "TCU2 ECU: w015 NPN subscription active";
CM_ SG_ 1414 TCU2_w016_IMEIMismatch "TCU2 ECU: w016 IMEI mismatch";
CM_ BO_ 1412 "TCU2 ECU message: log";
CM_ SG_ 1412 TCU2_logMux "TCU2 ECU: log mux";
CM_ SG_ 1412 TCU2_cpuTemp "Indicates the current temperature reported by the Central Processing Unit (CPU) in the modem application processor";
CM_ SG_ 1412 TCU2_cpuUsage "Indicates the current CPU usage in percentage reported by the modem application processor";
CM_ SG_ 1412 TCU2_mdmCoreTemperature "Indicates the current Communication Processor (CP) temperature reported by the modem CP.";
CM_ SG_ 1412 TCU2_availableMemory "Indicates the currently available Random Access Memory in the modem application processor";
CM_ SG_ 1412 TCU2_pwm "Indicates the active Pulse Width Modulation (PWM) duty cycle applied to the modem fan.";
CM_ SG_ 1412 TCU2_pwmcap "Indicates the active Pulse Width Modulation (PWM) duty cycle restriciton applied to the modem fan.";
CM_ SG_ 1412 TCU2_totalResumes "Indicates the total amount of times the modem has been resumed";
CM_ SG_ 1412 TCU2_mdmUplinkQueueSize "TCU2 ECU: mdm uplink queue size";
CM_ SG_ 1412 TCU2_mdmRSRP "TCU2 ECU: mdm RSRP";
CM_ SG_ 1412 TCU2_mdmSINR "TCU2 ECU: mdm SINR";
CM_ SG_ 1412 TCU2_mdmUplinkAllowedRate "TCU2 ECU: mdm uplink allowed rate";
CM_ SG_ 1412 TCU2_mdmUplinkAvgRate "TCU2 ECU: mdm uplink avg rate";
CM_ SG_ 1412 TCU2_mdmServiceState "TCU2 ECU: mdm service state";
CM_ SG_ 1412 TCU2_mdmIMSStatus "Indicates the current IP Multimedia System (IMS) registration state.";
CM_ SG_ 1412 TCU2_mdmSIMStatus "TCU2 ECU: mdm SIM status";
CM_ SG_ 1412 TCU2_mdmBusyActive "Reports whether the modem busy service is active on the modem application processor; raw 4294967295 = signal not available (SNA)";
CM_ SG_ 1412 TCU2_modemUptime "Indicates the current modem Application Processor uptime.";
CM_ SG_ 1412 TCU2_mdmDataRat "Reports which Radio Access Technology (RAT) is active for the current data bearer.";
CM_ SG_ 1412 TCU2_mdmDataCallStatus "Indicates the current state of the Packet Data Protocol (PDP) context.";
CM_ SG_ 1412 TCU2_mdmNSAAvailable "TCU2 ECU: mdm NSA available";
CM_ SG_ 1412 TCU2_mdmPCIID "TCU2 ECU: mdm PCIID";
CM_ SG_ 1412 TCU2_mdmMnc "TCU2 ECU: mdm mnc";
CM_ SG_ 1412 TCU2_mdmMcc "TCU2 ECU: mdm mcc";
CM_ SG_ 1412 TCU2_mdmTxKiloBytes "TCU2 ECU: mdm tx kilo bytes";
CM_ SG_ 1412 TCU2_mdmDataCallTermReason "Indicates the internal reason which the Data Call was terminated.";
CM_ SG_ 1412 TCU2_mdmDataCallTermCode "Indicates the termination code informed by the network that caused the Data Call termination.";
CM_ SG_ 1412 TCU2_cellularSMState "Indicates the current state of cellular state machine.";
CM_ SG_ 1412 TCU2_tcuSMState "Reports the state of the Telematics Control Unit (TCU) state machine.";
CM_ SG_ 1412 TCU2_checkInternetFailCount "Reports the count of unsuccessful cellular connectivity checks.";
CM_ SG_ 1412 TCU2_mdmBand "Indicates the band which the baseband processor is currently attached to the cellular network.";
CM_ SG_ 1412 TCU2_wakeSource "Indicates the source of wake event in the modem.";
CM_ BO_ 1159 "TCU ECU message: sleep config";
CM_ SG_ 1159 TCU_tc10Version "Indicates which version of Open Alliance's TC10 protocol is supported by the modem; raw 0 = signal not available (SNA)";
CM_ BO_ 1157 "TCU ECU message: alert log";
CM_ SG_ 1157 TCU_alertID "TCU ECU: alert ID";
CM_ SG_ 1157 TCU_alertState "TCU ECU: alert state";
CM_ SG_ 1157 TCU_w001_FailCode "TCU ECU: w001 fail code";
CM_ SG_ 1157 TCU_w002_RejCause "TCU ECU: w002 rej cause";
CM_ SG_ 1157 TCU_w003_CallFailCode "TCU ECU: w003 call fail code";
CM_ SG_ 1157 TCU_w004_MSDFailCode "TCU ECU: w004 MSD fail code";
CM_ SG_ 1157 TCU_w006_Count "TCU ECU: w006 count";
CM_ SG_ 1157 TCU_w007_Count "TCU ECU: w007 count";
CM_ SG_ 1157 TCU_w009_CrashCode "TCU ECU: w009 crash code";
CM_ SG_ 1157 TCU_w012_DataRAT "TCU ECU: w012 data RAT";
CM_ SG_ 1157 TCU_w012_RSRP "TCU ECU: w012 RSRP";
CM_ SG_ 1157 TCU_w012_RSRQ "TCU ECU: w012 RSRQ";
CM_ SG_ 1157 TCU_w012_MNC "TCU ECU: w012 MNC";
CM_ SG_ 1157 TCU_w012_AvgQueueUsage "TCU ECU: w012 avg queue usage";
CM_ SG_ 1157 TCU_w012_NSAAvailable "TCU ECU: w012 NSA available";
CM_ SG_ 1157 TCU_w013_DataRAT "TCU ECU: w013 data RAT";
CM_ SG_ 1157 TCU_w013_RSRP "TCU ECU: w013 RSRP";
CM_ SG_ 1157 TCU_w013_RSRQ "TCU ECU: w013 RSRQ";
CM_ SG_ 1157 TCU_w013_MNC "TCU ECU: w013 MNC";
CM_ SG_ 1157 TCU_w013_AvgQueueUsage "TCU ECU: w013 avg queue usage";
CM_ SG_ 1157 TCU_w013_NSAAvailable "TCU ECU: w013 NSA available";
CM_ SG_ 1157 TCU_w014_Reason "TCU ECU: w014 reason";
CM_ BO_ 1158 "TCU ECU message: alert matrix1";
CM_ SG_ 1158 TCU_w001_IMSRegistrationFailed "TCU ECU: w001 IMS registration failed";
CM_ SG_ 1158 TCU_w002_CellRegRejected "TCU ECU: w002 cell reg rejected";
CM_ SG_ 1158 TCU_w003_ECallFailed "TCU ECU: w003 e call failed";
CM_ SG_ 1158 TCU_w004_MSDTransmissionFailed "TCU ECU: w004 MSD transmission failed";
CM_ SG_ 1158 TCU_w005_SIMSlotError "TCU ECU: w005 SIM slot error";
CM_ SG_ 1158 TCU_w006_MpssUnavailable "TCU ECU: w006 mpss unavailable";
CM_ SG_ 1158 TCU_w007_ModemUnreachable "TCU ECU: w007 modem unreachable";
CM_ SG_ 1158 TCU_w008_KernelPanic "TCU ECU: w008 kernel panic";
CM_ SG_ 1158 TCU_w009_WifiFirmwareCrash "TCU ECU: w009 wifi firmware crash";
CM_ SG_ 1158 TCU_w010_WifiDumpDetected "TCU ECU: w010 wifi dump detected";
CM_ SG_ 1158 TCU_w011_CellDumpDetected "TCU ECU: w011 cell dump detected";
CM_ SG_ 1158 TCU_w012_UplinkDegraded "TCU ECU: w012 uplink degraded";
CM_ SG_ 1158 TCU_w013_UplinkQueueFull "TCU ECU: w013 uplink queue full";
CM_ SG_ 1158 TCU_w014_HostapdCrash "TCU ECU: w014 hostapd crash";
CM_ SG_ 1158 TCU_w015_NPNSubscriptionActive "TCU ECU: w015 NPN subscription active";
CM_ SG_ 1158 TCU_w016_IMEIMismatch "TCU ECU: w016 IMEI mismatch";
CM_ BO_ 1155 "TCU ECU message: log";
CM_ SG_ 1155 TCU_logMux "TCU ECU: log mux";
CM_ SG_ 1155 TCU_cpuTemp "Indicates the current temperature reported by the Central Processing Unit (CPU) in the modem application processor";
CM_ SG_ 1155 TCU_cpuUsage "Indicates the current CPU usage in percentage reported by the modem application processor";
CM_ SG_ 1155 TCU_mdmCoreTemperature "Indicates the current Communication Processor (CP) temperature reported by the modem CP.";
CM_ SG_ 1155 TCU_availableMemory "Indicates the currently available Random Access Memory in the modem application processor";
CM_ SG_ 1155 TCU_pwm "Indicates the active Pulse Width Modulation (PWM) duty cycle applied to the modem fan.";
CM_ SG_ 1155 TCU_pwmcap "Indicates the active Pulse Width Modulation (PWM) duty cycle restriciton applied to the modem fan.";
CM_ SG_ 1155 TCU_totalResumes "Indicates the total amount of times the modem has been resumed";
CM_ SG_ 1155 TCU_mdmUplinkQueueSize "TCU ECU: mdm uplink queue size";
CM_ SG_ 1155 TCU_mdmRSRP "TCU ECU: mdm RSRP";
CM_ SG_ 1155 TCU_mdmSINR "TCU ECU: mdm SINR";
CM_ SG_ 1155 TCU_mdmUplinkAllowedRate "TCU ECU: mdm uplink allowed rate";
CM_ SG_ 1155 TCU_mdmUplinkAvgRate "TCU ECU: mdm uplink avg rate";
CM_ SG_ 1155 TCU_mdmServiceState "TCU ECU: mdm service state";
CM_ SG_ 1155 TCU_mdmIMSStatus "Indicates the current IP Multimedia System (IMS) registration state.";
CM_ SG_ 1155 TCU_mdmSIMStatus "TCU ECU: mdm SIM status";
CM_ SG_ 1155 TCU_mdmBusyActive "Reports whether the modem busy service is active on the modem application processor; raw 4294967295 = signal not available (SNA)";
CM_ SG_ 1155 TCU_modemUptime "Indicates the current modem Application Processor uptime.";
CM_ SG_ 1155 TCU_mdmDataRat "Reports which Radio Access Technology (RAT) is active for the current data bearer.";
CM_ SG_ 1155 TCU_mdmDataCallStatus "Indicates the current state of the Packet Data Protocol (PDP) context.";
CM_ SG_ 1155 TCU_mdmNSAAvailable "TCU ECU: mdm NSA available";
CM_ SG_ 1155 TCU_mdmPCIID "TCU ECU: mdm PCIID";
CM_ SG_ 1155 TCU_mdmMnc "TCU ECU: mdm mnc";
CM_ SG_ 1155 TCU_mdmMcc "TCU ECU: mdm mcc";
CM_ SG_ 1155 TCU_mdmTxKiloBytes "TCU ECU: mdm tx kilo bytes";
CM_ SG_ 1155 TCU_mdmDataCallTermReason "Indicates the internal reason which the Data Call was terminated.";
CM_ SG_ 1155 TCU_mdmDataCallTermCode "Indicates the termination code informed by the network that caused the Data Call termination.";
CM_ SG_ 1155 TCU_cellularSMState "Indicates the current state of cellular state machine.";
CM_ SG_ 1155 TCU_tcuSMState "Reports the state of the Telematics Control Unit (TCU) state machine.";
CM_ SG_ 1155 TCU_checkInternetFailCount "Reports the count of unsuccessful cellular connectivity checks.";
CM_ SG_ 1155 TCU_mdmBand "Indicates the band which the baseband processor is currently attached to the cellular network.";
CM_ SG_ 1155 TCU_wakeSource "Indicates the source of wake event in the modem.";
CM_ BO_ 1298 "TRCM ECU message: alert log";
CM_ SG_ 1298 TRCM_alertID "TRCM ECU: alert ID";
CM_ SG_ 1298 TRCM_alertState "TRCM ECU: alert state";
CM_ SG_ 1298 TRCM_a015_NVMMMemOverflow "TRCM ECU: a015 NVMM mem overflow";
CM_ SG_ 1298 TRCM_a015_NVMMFilesystemError "TRCM ECU: a015 NVMM filesystem error";
CM_ SG_ 1298 TRCM_a015_NVMMRecordIDError "TRCM ECU: a015 NVMM record ID error";
CM_ SG_ 1298 TRCM_a017_tempData "TRCM ECU: a017 temp data";
CM_ SG_ 1298 TRCM_a018_tempData "TRCM ECU: a018 temp data";
CM_ SG_ 1298 TRCM_a035_eventArmStatus "TRCM ECU: a035 event arm status";
CM_ SG_ 1298 TRCM_a035_eventFrontLeftSeatbelt "TRCM ECU: a035 event front left seatbelt";
CM_ SG_ 1298 TRCM_a035_eventFrontRightSeatbel "TRCM ECU: a035 event front right seatbelt";
CM_ SG_ 1298 TRCM_a035_eventVehicleSpeed "TRCM ECU: a035 event vehicle speed";
CM_ SG_ 1298 TRCM_a035_eventDriverBrakeApply "TRCM ECU: a035 event driver brake apply; raw 3 = signal not available (SNA)";
CM_ SG_ 1298 TRCM_a035_eventAccelPedalPos "TRCM ECU: a035 event accel pedal pos; raw 255 = signal not available (SNA)";
CM_ SG_ 1298 TRCM_a036_collisionType "TRCM ECU: a036 collision type; raw 8 = signal not available (SNA)";
CM_ SG_ 1298 TRCM_a036_collisionSeverity "TRCM ECU: a036 collision severity";
CM_ SG_ 1298 TRCM_a036_eventArmStatus "TRCM ECU: a036 event arm status";
CM_ SG_ 1298 TRCM_a036_eventFrontLeftSeatbelt "TRCM ECU: a036 event front left seatbelt";
CM_ SG_ 1298 TRCM_a036_eventFrontRightSeatbel "TRCM ECU: a036 event front right seatbelt";
CM_ SG_ 1298 TRCM_a036_eventVehicleSpeed "TRCM ECU: a036 event vehicle speed";
CM_ SG_ 1298 TRCM_a036_eventDriverBrakeApply "TRCM ECU: a036 event driver brake apply; raw 3 = signal not available (SNA)";
CM_ SG_ 1298 TRCM_a036_eventAccelPedalPos "TRCM ECU: a036 event accel pedal pos; raw 255 = signal not available (SNA)";
CM_ SG_ 1298 TRCM_a037_nearDeployFront "TRCM ECU: a037 near deploy front";
CM_ SG_ 1298 TRCM_a037_nearDeployRear "TRCM ECU: a037 near deploy rear";
CM_ SG_ 1298 TRCM_a037_nearDeployLeft "TRCM ECU: a037 near deploy left";
CM_ SG_ 1298 TRCM_a037_nearDeployRight "TRCM ECU: a037 near deploy right";
CM_ SG_ 1298 TRCM_a037_nearDeployRoll "TRCM ECU: a037 near deploy roll";
CM_ SG_ 1298 TRCM_a037_eventArmStatus "TRCM ECU: a037 event arm status";
CM_ SG_ 1298 TRCM_a037_eventFrontLeftSeatbelt "TRCM ECU: a037 event front left seatbelt";
CM_ SG_ 1298 TRCM_a037_eventFrontRightSeatbel "TRCM ECU: a037 event front right seatbelt";
CM_ SG_ 1298 TRCM_a037_eventVehicleSpeed "TRCM ECU: a037 event vehicle speed";
CM_ SG_ 1298 TRCM_a037_eventDriverBrakeApply "TRCM ECU: a037 event driver brake apply; raw 3 = signal not available (SNA)";
CM_ SG_ 1298 TRCM_a037_eventAccelPedalPos "TRCM ECU: a037 event accel pedal pos; raw 255 = signal not available (SNA)";
CM_ SG_ 1298 TRCM_a038_stuckLowOrOpenCircuit "TRCM ECU: a038 stuck low or open circuit";
CM_ SG_ 1298 TRCM_a038_stuckHigh "TRCM ECU: a038 stuck high";
CM_ SG_ 1298 TRCM_a038_overCurrent "TRCM ECU: a038 over current";
CM_ SG_ 1298 TRCM_a038_driverOverTemperature "TRCM ECU: a038 driver over temperature";
CM_ SG_ 1298 TRCM_a039_stuckLowOrOpenCircuit "TRCM ECU: a039 stuck low or open circuit";
CM_ SG_ 1298 TRCM_a039_stuckHigh "TRCM ECU: a039 stuck high";
CM_ SG_ 1298 TRCM_a039_overCurrent "TRCM ECU: a039 over current";
CM_ SG_ 1298 TRCM_a039_driverOverTemperature "TRCM ECU: a039 driver over temperature";
CM_ SG_ 1298 TRCM_a057_VEH_cpControl "TRCM ECU: a057 VEH cp control";
CM_ SG_ 1298 TRCM_a059_voltageDrop "TRCM ECU: a059 voltage drop";
CM_ SG_ 1298 TRCM_a059_resistanceEstimate "TRCM ECU: a059 resistance estimate";
CM_ SG_ 1298 TRCM_a059_current "TRCM ECU: a059 current";
CM_ SG_ 1298 TRCM_a063_switchChannel "TRCM ECU: a063 switch channel";
CM_ SG_ 1298 TRCM_a063_switchType "TRCM ECU: a063 switch type";
CM_ SG_ 1298 TRCM_a063_ADCVoltage "TRCM ECU: a063 ADC voltage";
CM_ SG_ 1298 TRCM_a063_disconnected "TRCM ECU: a063 disconnected";
CM_ SG_ 1298 TRCM_a063_indeterminate "TRCM ECU: a063 indeterminate";
CM_ SG_ 1298 TRCM_a063_stuckActive "TRCM ECU: a063 stuck active";
CM_ SG_ 1298 TRCM_a063_faulted "TRCM ECU: a063 faulted";
CM_ SG_ 1298 TRCM_a065_vsafingFetVoltage "TRCM ECU: a065 vsafing fet voltage";
CM_ SG_ 1298 TRCM_a066_busVoltage "TRCM ECU: a066 bus voltage";
CM_ SG_ 1298 TRCM_a078_channelIndex "TRCM ECU: a078 channel index";
CM_ SG_ 1298 TRCM_a078_value "TRCM ECU: a078 value";
CM_ SG_ 1298 TRCM_a081_eventArmStatus "TRCM ECU: a081 event arm status";
CM_ SG_ 1298 TRCM_a081_eventFrontLeftSeatbelt "TRCM ECU: a081 event front left seatbelt";
CM_ SG_ 1298 TRCM_a081_eventFrontRightSeatbel "TRCM ECU: a081 event front right seatbelt";
CM_ SG_ 1298 TRCM_a081_eventVehicleSpeed "TRCM ECU: a081 event vehicle speed";
CM_ SG_ 1298 TRCM_a081_eventDriverBrakeApply "TRCM ECU: a081 event driver brake apply; raw 3 = signal not available (SNA)";
CM_ SG_ 1298 TRCM_a081_eventAccelPedalPos "TRCM ECU: a081 event accel pedal pos; raw 255 = signal not available (SNA)";
CM_ SG_ 1298 TRCM_a082_RIPC_epbPrivateState "TRCM ECU: a082 RIPC epb private state";
CM_ SG_ 1298 TRCM_a082_RIPC_remoteHSD "TRCM ECU: a082 RIPC remote HSD";
CM_ SG_ 1298 TRCM_a082_RIPC_railStatus "TRCM ECU: a082 RIPC rail status";
CM_ SG_ 1298 TRCM_a082_RIPC_remoteMux "TRCM ECU: a082 RIPC remote mux";
CM_ SG_ 1298 TRCM_a083_LIPC_epbPrivateState "TRCM ECU: a083 LIPC epb private state";
CM_ SG_ 1298 TRCM_a083_LIPC_remoteHSD "TRCM ECU: a083 LIPC remote HSD";
CM_ SG_ 1298 TRCM_a083_LIPC_railStatus "TRCM ECU: a083 LIPC rail status";
CM_ SG_ 1298 TRCM_a083_LIPC_HSDFaults "TRCM ECU: a083 LIPC HSD faults";
CM_ SG_ 1298 TRCM_a084_CH_StatusC "TRCM ECU: a084 CH status c";
CM_ SG_ 1298 TRCM_a085_PARTY_buttonStatus "TRCM ECU: a085 PARTY button status";
CM_ SG_ 1298 TRCM_a086_VEH_LVBMS_statusHigh "TRCM ECU: a086 VEH LVBMS status high";
CM_ SG_ 1298 TRCM_a086_VEH_LVBMS_statusLow "TRCM ECU: a086 VEH LVBMS status low";
CM_ SG_ 1298 TRCM_a086_VEH_status "TRCM ECU: a086 VEH status";
CM_ SG_ 1298 TRCM_a086_VEH_12VBatteryStatus "TRCM ECU: a086 VEH 12 v battery status";
CM_ SG_ 1298 TRCM_a086_VEH_LVPowerState "TRCM ECU: a086 VEH LV power state";
CM_ SG_ 1298 TRCM_a086_VEH_lightStatus "TRCM ECU: a086 VEH light status";
CM_ SG_ 1298 TRCM_a086_VEH_systemStatus "TRCM ECU: a086 VEH system status";
CM_ SG_ 1298 TRCM_a086_VEH_thermalStatus "TRCM ECU: a086 VEH thermal status";
CM_ SG_ 1298 TRCM_a086_VEH_vehNm "TRCM ECU: a086 VEH veh nm";
CM_ SG_ 1298 TRCM_a087_VEH_temperature "TRCM ECU: a087 VEH temperature";
CM_ SG_ 1298 TRCM_a087_VEH_thermalControl "TRCM ECU: a087 VEH thermal control";
CM_ SG_ 1298 TRCM_a087_VEH_torque "TRCM ECU: a087 VEH torque";
CM_ SG_ 1298 TRCM_a087_VEH_status "TRCM ECU: a087 VEH status";
CM_ SG_ 1298 TRCM_a087_PARTY_torque "TRCM ECU: a087 PARTY torque";
CM_ SG_ 1298 TRCM_a087_PARTY_status "TRCM ECU: a087 PARTY status";
CM_ SG_ 1298 TRCM_a087_PARTY_temperature "TRCM ECU: a087 PARTY temperature";
CM_ SG_ 1298 TRCM_a087_PARTY_thermalControl "TRCM ECU: a087 PARTY thermal control";
CM_ SG_ 1298 TRCM_a087_VEH_motorStatus "TRCM ECU: a087 VEH motor status";
CM_ SG_ 1298 TRCM_a088_VEH_temperature "TRCM ECU: a088 VEH temperature";
CM_ SG_ 1298 TRCM_a088_VEH_thermalControl "TRCM ECU: a088 VEH thermal control";
CM_ SG_ 1298 TRCM_a088_VEH_torque "TRCM ECU: a088 VEH torque";
CM_ SG_ 1298 TRCM_a088_VEH_status "TRCM ECU: a088 VEH status";
CM_ SG_ 1298 TRCM_a088_PARTY_torque "TRCM ECU: a088 PARTY torque";
CM_ SG_ 1298 TRCM_a088_PARTY_status "TRCM ECU: a088 PARTY status";
CM_ SG_ 1298 TRCM_a088_PARTY_temperature "TRCM ECU: a088 PARTY temperature";
CM_ SG_ 1298 TRCM_a088_PARTY_thermalControl "TRCM ECU: a088 PARTY thermal control";
CM_ SG_ 1298 TRCM_a088_VEH_motorStatus "TRCM ECU: a088 VEH motor status";
CM_ SG_ 1298 TRCM_a089_PARTY_party1 "TRCM ECU: a089 PARTY party1";
CM_ SG_ 1298 TRCM_a089_PARTY_status "TRCM ECU: a089 PARTY status";
CM_ SG_ 1298 TRCM_a089_VEH_status "TRCM ECU: a089 VEH status";
CM_ SG_ 1298 TRCM_a089_BDY_party1 "TRCM ECU: a089 BDY party1";
CM_ SG_ 1298 TRCM_a089_BDY_status "TRCM ECU: a089 BDY status";
CM_ SG_ 1298 TRCM_a089_CH_status "TRCM ECU: a089 CH status";
CM_ SG_ 1298 TRCM_a089_CH_party1 "TRCM ECU: a089 CH party1";
CM_ SG_ 1298 TRCM_a089_CH_party3 "TRCM ECU: a089 CH party3";
CM_ SG_ 1298 TRCM_a089_VEH_party1 "TRCM ECU: a089 VEH party1";
CM_ SG_ 1298 TRCM_a089_VEH_party3 "TRCM ECU: a089 VEH party3";
CM_ SG_ 1298 TRCM_a091_VEH_faultsAndExtras "TRCM ECU: a091 VEH faults and extras";
CM_ SG_ 1298 TRCM_a091_VEH_info "TRCM ECU: a091 VEH info";
CM_ SG_ 1298 TRCM_a091_VEH_state "TRCM ECU: a091 VEH state";
CM_ SG_ 1298 TRCM_a092_VEH_restraintStatus "TRCM ECU: a092 VEH restraint status";
CM_ SG_ 1298 TRCM_a092_VEH_switchStatus "TRCM ECU: a092 VEH switch status";
CM_ SG_ 1298 TRCM_a092_VEH_seatStatus2 "TRCM ECU: a092 VEH seat status2";
CM_ SG_ 1298 TRCM_a092_VEH_vehNm "TRCM ECU: a092 VEH veh nm";
CM_ SG_ 1298 TRCM_a093_VEH_restraintStatus "TRCM ECU: a093 VEH restraint status";
CM_ SG_ 1298 TRCM_a093_VEH_switchStatus "TRCM ECU: a093 VEH switch status";
CM_ SG_ 1298 TRCM_a093_VEH_seatStatus2 "TRCM ECU: a093 VEH seat status2";
CM_ SG_ 1298 TRCM_a093_VEH_vehNm "TRCM ECU: a093 VEH veh nm";
CM_ SG_ 1298 TRCM_a094_VEH_sysStatus "TRCM ECU: a094 VEH sys status";
CM_ SG_ 1298 TRCM_a094_PARTY_sysStatus "TRCM ECU: a094 PARTY sys status";
CM_ SG_ 1298 TRCM_a094_CH_sysStatus "TRCM ECU: a094 CH sys status";
CM_ SG_ 1298 TRCM_a095_PT_ptNm "TRCM ECU: a095 PT pt nm";
CM_ SG_ 1298 TRCM_a095_PT_status "TRCM ECU: a095 PT status";
CM_ SG_ 1298 TRCM_a096_VEH_status "TRCM ECU: a096 VEH status";
CM_ SG_ 1298 TRCM_a096_CH_status "TRCM ECU: a096 CH status";
CM_ SG_ 1298 TRCM_a097_VEH_HVStatus "TRCM ECU: a097 VEH HV status";
CM_ SG_ 1298 TRCM_a097_VEH_state "TRCM ECU: a097 VEH state";
CM_ SG_ 1298 TRCM_a098_CH_torque "TRCM ECU: a098 CH torque";
CM_ SG_ 1298 TRCM_a098_VEH_hvStatus "TRCM ECU: a098 VEH hv status";
CM_ SG_ 1298 TRCM_a098_VEH_status "TRCM ECU: a098 VEH status";
CM_ SG_ 1298 TRCM_a098_VEH_thermalControl "TRCM ECU: a098 VEH thermal control";
CM_ SG_ 1298 TRCM_a098_VEH_temperature "TRCM ECU: a098 VEH temperature";
CM_ SG_ 1298 TRCM_a098_VEH_torque "TRCM ECU: a098 VEH torque";
CM_ SG_ 1298 TRCM_a098_PARTY_status "TRCM ECU: a098 PARTY status";
CM_ SG_ 1298 TRCM_a098_PARTY_temperature "TRCM ECU: a098 PARTY temperature";
CM_ SG_ 1298 TRCM_a098_PARTY_thermalControl "TRCM ECU: a098 PARTY thermal control";
CM_ SG_ 1298 TRCM_a098_PARTY_torque "TRCM ECU: a098 PARTY torque";
CM_ SG_ 1298 TRCM_a098_PT_thermalControl "TRCM ECU: a098 PT thermal control";
CM_ SG_ 1298 TRCM_a098_PT_temperature "TRCM ECU: a098 PT temperature";
CM_ SG_ 1298 TRCM_a098_PARTY_motorStatus "TRCM ECU: a098 PARTY motor status";
CM_ SG_ 1298 TRCM_a098_VEH_motorStatus "TRCM ECU: a098 VEH motor status";
CM_ SG_ 1298 TRCM_a099_VEH_oocStatus "TRCM ECU: a099 VEH ooc status";
CM_ SG_ 1298 TRCM_a100_VEH "TRCM ECU: a100 VEH";
CM_ SG_ 1298 TRCM_a100_PARTY "TRCM ECU: a100 PARTY";
CM_ SG_ 1298 TRCM_a100_PT "TRCM ECU: a100 PT";
CM_ SG_ 1298 TRCM_a100_CH "TRCM ECU: a100 CH";
CM_ SG_ 1298 TRCM_a100_OBD "TRCM ECU: a100 OBD";
CM_ SG_ 1298 TRCM_a101_VEH_state "TRCM ECU: a101 VEH state";
CM_ SG_ 1298 TRCM_a101_PARTY_locState "TRCM ECU: a101 PARTY loc state";
CM_ SG_ 1298 TRCM_a101_LIPC_externalWatchdogH "TRCM ECU: a101 LIPC external watchdog heart beat";
CM_ SG_ 1298 TRCM_a101_VEH_locState "TRCM ECU: a101 VEH loc state";
CM_ SG_ 1298 TRCM_a101_BDY_locState "TRCM ECU: a101 BDY loc state";
CM_ SG_ 1298 TRCM_a102_VEH_faultsAndExtras "TRCM ECU: a102 VEH faults and extras";
CM_ SG_ 1298 TRCM_a102_VEH_feedbackStatus "TRCM ECU: a102 VEH feedback status";
CM_ SG_ 1298 TRCM_a102_VEH_sensorStatus "TRCM ECU: a102 VEH sensor status";
CM_ SG_ 1298 TRCM_a102_VEH_rods "TRCM ECU: a102 VEH rods";
CM_ SG_ 1298 TRCM_a103_VEH_hvsNm "TRCM ECU: a103 VEH hvs nm";
CM_ SG_ 1298 TRCM_a103_VEH_vehNm "TRCM ECU: a103 VEH veh nm";
CM_ SG_ 1298 TRCM_a103_VEH_status "TRCM ECU: a103 VEH status";
CM_ SG_ 1298 TRCM_a103_PT_ptNm "TRCM ECU: a103 PT pt nm";
CM_ SG_ 1298 TRCM_a103_PT_status "TRCM ECU: a103 PT status";
CM_ SG_ 1298 TRCM_a103_VEH_evseStatus "TRCM ECU: a103 VEH evse status";
CM_ SG_ 1298 TRCM_a105_VEH_states "TRCM ECU: a105 VEH states";
CM_ SG_ 1298 TRCM_a105_VEH_chNm "TRCM ECU: a105 VEH ch nm";
CM_ SG_ 1298 TRCM_a105_VEH_dampingStates "TRCM ECU: a105 VEH damping states";
CM_ SG_ 1298 TRCM_a106_VEH_dcdcStatus "TRCM ECU: a106 VEH dcdc status";
CM_ SG_ 1298 TRCM_a106_VEH_thermalControl "TRCM ECU: a106 VEH thermal control";
CM_ SG_ 1298 TRCM_a106_VEH_dcdcRailStatus "TRCM ECU: a106 VEH dcdc rail status";
CM_ SG_ 1298 TRCM_a106_CH_dcdcRailStatus "TRCM ECU: a106 CH dcdc rail status";
CM_ SG_ 1298 TRCM_a106_CH_alertMatrix "TRCM ECU: a106 CH alert matrix";
CM_ SG_ 1298 TRCM_a107_VEH_hvsNm "TRCM ECU: a107 VEH hvs nm";
CM_ SG_ 1298 TRCM_a107_VEH_vehNm "TRCM ECU: a107 VEH veh nm";
CM_ SG_ 1298 TRCM_a107_VEH_status "TRCM ECU: a107 VEH status";
CM_ SG_ 1298 TRCM_a107_VEH_thermalStatus "TRCM ECU: a107 VEH thermal status";
CM_ SG_ 1298 TRCM_a107_VEH_bmbMinMax "TRCM ECU: a107 VEH bmb min max";
CM_ SG_ 1298 TRCM_a107_VEH_powerAvailable "TRCM ECU: a107 VEH power available";
CM_ SG_ 1298 TRCM_a107_PT_ptNm "TRCM ECU: a107 PT pt nm";
CM_ SG_ 1298 TRCM_a107_PT_status "TRCM ECU: a107 PT status";
CM_ SG_ 1298 TRCM_a107_PT_thermalStatus "TRCM ECU: a107 PT thermal status";
CM_ SG_ 1298 TRCM_a107_PT_socStatus "TRCM ECU: a107 PT soc status";
CM_ SG_ 1298 TRCM_a107_VEH_socStatus "TRCM ECU: a107 VEH soc status";
CM_ SG_ 1298 TRCM_a107_VEH_packConfig "TRCM ECU: a107 VEH pack config";
CM_ SG_ 1298 TRCM_a107_VEH_energyStatus "TRCM ECU: a107 VEH energy status";
CM_ SG_ 1298 TRCM_a107_VEH_chargeInfo "TRCM ECU: a107 VEH charge info";
CM_ SG_ 1298 TRCM_a108_VEH_hvStatus "TRCM ECU: a108 VEH hv status";
CM_ SG_ 1298 TRCM_a108_VEH_temperature "TRCM ECU: a108 VEH temperature";
CM_ SG_ 1298 TRCM_a108_VEH_thermalControl "TRCM ECU: a108 VEH thermal control";
CM_ SG_ 1298 TRCM_a108_VEH_torque "TRCM ECU: a108 VEH torque";
CM_ SG_ 1298 TRCM_a108_VEH_status "TRCM ECU: a108 VEH status";
CM_ SG_ 1298 TRCM_a108_PARTY_torque "TRCM ECU: a108 PARTY torque";
CM_ SG_ 1298 TRCM_a108_PARTY_status "TRCM ECU: a108 PARTY status";
CM_ SG_ 1298 TRCM_a108_PARTY_temperature "TRCM ECU: a108 PARTY temperature";
CM_ SG_ 1298 TRCM_a108_PARTY_thermalControl "TRCM ECU: a108 PARTY thermal control";
CM_ SG_ 1298 TRCM_a108_PT_temperature "TRCM ECU: a108 PT temperature";
CM_ SG_ 1298 TRCM_a108_PT_thermalControl "TRCM ECU: a108 PT thermal control";
CM_ SG_ 1298 TRCM_a108_PARTY_motorStatus "TRCM ECU: a108 PARTY motor status";
CM_ SG_ 1298 TRCM_a108_VEH_motorStatus "TRCM ECU: a108 VEH motor status";
CM_ SG_ 1298 TRCM_a108_CH_torque "TRCM ECU: a108 CH torque";
CM_ SG_ 1298 TRCM_a110_VEH_carState "TRCM ECU: a110 VEH car state";
CM_ SG_ 1298 TRCM_a110_VEH_carConfig "TRCM ECU: a110 VEH car config";
CM_ SG_ 1298 TRCM_a110_VEH_time "TRCM ECU: a110 VEH time";
CM_ SG_ 1298 TRCM_a110_VEH_updateStatus "TRCM ECU: a110 VEH update status";
CM_ SG_ 1298 TRCM_a110_VEH_vehNm "TRCM ECU: a110 VEH veh nm";
CM_ SG_ 1298 TRCM_a110_VEH_mismatchFault "TRCM ECU: a110 VEH mismatch fault";
CM_ SG_ 1298 TRCM_a110_VEH_vin "TRCM ECU: a110 VEH vin";
CM_ SG_ 1298 TRCM_a110_VEH_bmpDebug "TRCM ECU: a110 VEH bmp debug";
CM_ SG_ 1298 TRCM_a110_VEH_gearControl "TRCM ECU: a110 VEH gear control";
CM_ SG_ 1298 TRCM_a110_VEH_canLogAvailability "TRCM ECU: a110 VEH can log availability";
CM_ SG_ 1298 TRCM_a110_CH_airbagCutoffStatus "TRCM ECU: a110 CH airbag cutoff status";
CM_ SG_ 1298 TRCM_a110_CH_carConfig "TRCM ECU: a110 CH car config";
CM_ SG_ 1298 TRCM_a110_CH_carState "TRCM ECU: a110 CH car state";
CM_ SG_ 1298 TRCM_a110_CH_vin "TRCM ECU: a110 CH vin";
CM_ SG_ 1298 TRCM_a110_CH_chNm "TRCM ECU: a110 CH ch nm";
CM_ SG_ 1298 TRCM_a110_CH_epochTimeGtw "TRCM ECU: a110 CH epoch time gtw";
CM_ SG_ 1298 TRCM_a110_PARTY_carConfig "TRCM ECU: a110 PARTY car config";
CM_ SG_ 1298 TRCM_a111_VEH_internalStatus "TRCM ECU: a111 VEH internal status";
CM_ SG_ 1298 TRCM_a111_VEH_status "TRCM ECU: a111 VEH status";
CM_ SG_ 1298 TRCM_a111_VEH_vehNm "TRCM ECU: a111 VEH veh nm";
CM_ SG_ 1298 TRCM_a111_RIPC_LVPowerState "TRCM ECU: a111 RIPC LV power state";
CM_ SG_ 1298 TRCM_a111_RIPC_epbPrivateState "TRCM ECU: a111 RIPC epb private state";
CM_ SG_ 1298 TRCM_a111_RIPC_railStatus "TRCM ECU: a111 RIPC rail status";
CM_ SG_ 1298 TRCM_a111_RIPC_remoteADC "TRCM ECU: a111 RIPC remote ADC";
CM_ SG_ 1298 TRCM_a111_RIPC_switchStatus "TRCM ECU: a111 RIPC switch status";
CM_ SG_ 1298 TRCM_a111_VEH_LVPowerState "TRCM ECU: a111 VEH LV power state";
CM_ SG_ 1298 TRCM_a111_VEH_seatStatus "TRCM ECU: a111 VEH seat status";
CM_ SG_ 1298 TRCM_a111_PARTY_status "TRCM ECU: a111 PARTY status";
CM_ SG_ 1298 TRCM_a111_CH_status "TRCM ECU: a111 CH status";
CM_ SG_ 1298 TRCM_a112_VEH_internalStatus "TRCM ECU: a112 VEH internal status";
CM_ SG_ 1298 TRCM_a112_VEH_status "TRCM ECU: a112 VEH status";
CM_ SG_ 1298 TRCM_a112_VEH_vehNm "TRCM ECU: a112 VEH veh nm";
CM_ SG_ 1298 TRCM_a112_LIPC_LVPowerState "TRCM ECU: a112 LIPC LV power state";
CM_ SG_ 1298 TRCM_a112_LIPC_epbPrivateState "TRCM ECU: a112 LIPC epb private state";
CM_ SG_ 1298 TRCM_a112_LIPC_railStatus "TRCM ECU: a112 LIPC rail status";
CM_ SG_ 1298 TRCM_a112_LIPC_remoteADC "TRCM ECU: a112 LIPC remote ADC";
CM_ SG_ 1298 TRCM_a112_LIPC_switchStatus "TRCM ECU: a112 LIPC switch status";
CM_ SG_ 1298 TRCM_a112_VEH_LVPowerState "TRCM ECU: a112 VEH LV power state";
CM_ SG_ 1298 TRCM_a112_PARTY_status "TRCM ECU: a112 PARTY status";
CM_ SG_ 1298 TRCM_a112_CH_status "TRCM ECU: a112 CH status";
CM_ SG_ 1298 TRCM_a114_PARTY_status "TRCM ECU: a114 PARTY status";
CM_ SG_ 1298 TRCM_a114_PARTY_wheelSpeeds "TRCM ECU: a114 PARTY wheel speeds";
CM_ SG_ 1298 TRCM_a114_VEH_wheelSpeeds "TRCM ECU: a114 VEH wheel speeds";
CM_ SG_ 1298 TRCM_a114_CH_wheelSpeeds "TRCM ECU: a114 CH wheel speeds";
CM_ SG_ 1298 TRCM_a114_PARTY_party3 "TRCM ECU: a114 PARTY party3";
CM_ SG_ 1298 TRCM_a114_VEH_party3 "TRCM ECU: a114 VEH party3";
CM_ SG_ 1298 TRCM_a114_VEH_status "TRCM ECU: a114 VEH status";
CM_ SG_ 1298 TRCM_a114_PARTY_wheelRotation "TRCM ECU: a114 PARTY wheel rotation";
CM_ SG_ 1298 TRCM_a114_CH_wheelRotation "TRCM ECU: a114 CH wheel rotation";
CM_ SG_ 1298 TRCM_a114_VEH_wheelRotation "TRCM ECU: a114 VEH wheel rotation";
CM_ SG_ 1298 TRCM_a114_PARTY_brakeTorque "TRCM ECU: a114 PARTY brake torque";
CM_ SG_ 1298 TRCM_a114_PARTY_offsets "TRCM ECU: a114 PARTY offsets";
CM_ SG_ 1298 TRCM_a114_BDY_offsets "TRCM ECU: a114 BDY offsets";
CM_ SG_ 1298 TRCM_a114_BDY_party3 "TRCM ECU: a114 BDY party3";
CM_ SG_ 1298 TRCM_a114_BDY_status "TRCM ECU: a114 BDY status";
CM_ SG_ 1298 TRCM_a114_BDY_wheelRotation "TRCM ECU: a114 BDY wheel rotation";
CM_ SG_ 1298 TRCM_a114_BDY_wheelSpeeds "TRCM ECU: a114 BDY wheel speeds";
CM_ SG_ 1298 TRCM_a114_CH_party1 "TRCM ECU: a114 CH party1";
CM_ SG_ 1298 TRCM_a114_CH_party3 "TRCM ECU: a114 CH party3";
CM_ SG_ 1298 TRCM_a114_CH_status "TRCM ECU: a114 CH status";
CM_ SG_ 1298 TRCM_a115_VEH_vehNm "TRCM ECU: a115 VEH veh nm";
CM_ SG_ 1298 TRCM_a115_VEH_authentication "TRCM ECU: a115 VEH authentication";
CM_ SG_ 1298 TRCM_a115_VEH_BLEResetRequest "TRCM ECU: a115 VEH BLE reset request";
CM_ SG_ 1298 TRCM_a115_VEH_requests "TRCM ECU: a115 VEH requests";
CM_ SG_ 1298 TRCM_a115_VEH_requests2 "TRCM ECU: a115 VEH requests2";
CM_ SG_ 1298 TRCM_a115_REM_authentication "TRCM ECU: a115 REM authentication";
CM_ SG_ 1298 TRCM_a115_UI_corianderVehicleCon "TRCM ECU: a115 UI coriander vehicle control";
CM_ SG_ 1298 TRCM_a115_CH_TPMSDisplay "TRCM ECU: a115 CH TPMS display";
CM_ SG_ 1298 TRCM_a116_PARTY_epbmStatus "TRCM ECU: a116 PARTY epbm status";
CM_ SG_ 1298 TRCM_a116_VEH_vehNm "TRCM ECU: a116 VEH veh nm";
CM_ SG_ 1298 TRCM_a116_VEH_hvacRequest "TRCM ECU: a116 VEH hvac request";
CM_ SG_ 1298 TRCM_a116_VEH_hvacStatus "TRCM ECU: a116 VEH hvac status";
CM_ SG_ 1298 TRCM_a116_VEH_LVPowerState "TRCM ECU: a116 VEH LV power state";
CM_ SG_ 1298 TRCM_a116_VEH_lightStatus "TRCM ECU: a116 VEH light status";
CM_ SG_ 1298 TRCM_a116_VEH_seatStatus "TRCM ECU: a116 VEH seat status";
CM_ SG_ 1298 TRCM_a116_VEH_thsStatus "TRCM ECU: a116 VEH ths status";
CM_ SG_ 1298 TRCM_a116_VEH_doorStatus "TRCM ECU: a116 VEH door status";
CM_ SG_ 1298 TRCM_a116_VEH_seatHeatStatus "TRCM ECU: a116 VEH seat heat status";
CM_ SG_ 1298 TRCM_a116_VEH_restraintStatus "TRCM ECU: a116 VEH restraint status";
CM_ SG_ 1298 TRCM_a116_VEH_switchStatus "TRCM ECU: a116 VEH switch status";
CM_ SG_ 1298 TRCM_a116_VEH_logging1Hz "TRCM ECU: a116 VEH logging1 hz";
CM_ SG_ 1298 TRCM_a116_VEH_seatStatus2 "TRCM ECU: a116 VEH seat status2";
CM_ SG_ 1298 TRCM_a116_VEH_status "TRCM ECU: a116 VEH status";
CM_ SG_ 1298 TRCM_a116_VEH_thermalCommand "TRCM ECU: a116 VEH thermal command";
CM_ SG_ 1298 TRCM_a116_VEH_windowStatus "TRCM ECU: a116 VEH window status";
CM_ SG_ 1298 TRCM_a116_PARTY_restraintStatus "TRCM ECU: a116 PARTY restraint status";
CM_ SG_ 1298 TRCM_a116_PARTY_doorStatus "TRCM ECU: a116 PARTY door status";
CM_ SG_ 1298 TRCM_a116_BDY_epbmStatus "TRCM ECU: a116 BDY epbm status";
CM_ SG_ 1298 TRCM_a116_BDY_restraintStatus "TRCM ECU: a116 BDY restraint status";
CM_ SG_ 1298 TRCM_a116_BDY_switchStatus "TRCM ECU: a116 BDY switch status";
CM_ SG_ 1298 TRCM_a117_BDY_epbmStatus "TRCM ECU: a117 BDY epbm status";
CM_ SG_ 1298 TRCM_a117_BDY_restraintStatus "TRCM ECU: a117 BDY restraint status";
CM_ SG_ 1298 TRCM_a117_VEH_prndStatus "TRCM ECU: a117 VEH prnd status";
CM_ SG_ 1298 TRCM_a117_PARTY_epbmStatus "TRCM ECU: a117 PARTY epbm status";
CM_ SG_ 1298 TRCM_a117_VEH_vehNm "TRCM ECU: a117 VEH veh nm";
CM_ SG_ 1298 TRCM_a117_VEH_hvacBlowerFdb "TRCM ECU: a117 VEH hvac blower fdb";
CM_ SG_ 1298 TRCM_a117_VEH_LVPowerState "TRCM ECU: a117 VEH LV power state";
CM_ SG_ 1298 TRCM_a117_VEH_restraintStatus "TRCM ECU: a117 VEH restraint status";
CM_ SG_ 1298 TRCM_a117_VEH_lightStatus "TRCM ECU: a117 VEH light status";
CM_ SG_ 1298 TRCM_a117_VEH_seatStatus "TRCM ECU: a117 VEH seat status";
CM_ SG_ 1298 TRCM_a117_BDY_falconSwitchStatus "TRCM ECU: a117 BDY falcon switch status";
CM_ SG_ 1298 TRCM_a117_VEH_doorStatus "TRCM ECU: a117 VEH door status";
CM_ SG_ 1298 TRCM_a117_VEH_doorStatus2 "TRCM ECU: a117 VEH door status2";
CM_ SG_ 1298 TRCM_a117_VEH_windowStatus "TRCM ECU: a117 VEH window status";
CM_ SG_ 1298 TRCM_a117_VEH_switchStatus "TRCM ECU: a117 VEH switch status";
CM_ SG_ 1298 TRCM_a117_VEH_intrusionSensorSta "TRCM ECU: a117 VEH intrusion sensor status";
CM_ SG_ 1298 TRCM_a117_VEH_liftgateStatus "TRCM ECU: a117 VEH liftgate status";
CM_ SG_ 1298 TRCM_a117_VEH_seatStatus2 "TRCM ECU: a117 VEH seat status2";
CM_ SG_ 1298 TRCM_a117_PARTY_restraintStatus "TRCM ECU: a117 PARTY restraint status";
CM_ SG_ 1298 TRCM_a117_VEH_thermalStatus "TRCM ECU: a117 VEH thermal status";
CM_ SG_ 1298 TRCM_a117_PARTY_doorStatus "TRCM ECU: a117 PARTY door status";
CM_ SG_ 1298 TRCM_a117_VEH_status "TRCM ECU: a117 VEH status";
CM_ SG_ 1298 TRCM_a117_PARTY_prndStatus "TRCM ECU: a117 PARTY prnd status";
CM_ SG_ 1298 TRCM_a117_PARTY_lightingSecondar "TRCM ECU: a117 PARTY lighting secondary";
CM_ SG_ 1298 TRCM_a118_VEH_vehNm "TRCM ECU: a118 VEH veh nm";
CM_ SG_ 1298 TRCM_a118_VEH_lighting "TRCM ECU: a118 VEH lighting";
CM_ SG_ 1298 TRCM_a118_VEH_sensors "TRCM ECU: a118 VEH sensors";
CM_ SG_ 1298 TRCM_a118_VEH_status "TRCM ECU: a118 VEH status";
CM_ SG_ 1298 TRCM_a118_VEH_okToUseHighPwr "TRCM ECU: a118 VEH ok to use high pwr";
CM_ SG_ 1298 TRCM_a118_VEH_LVPowerState "TRCM ECU: a118 VEH LV power state";
CM_ SG_ 1298 TRCM_a118_VEH_coolant "TRCM ECU: a118 VEH coolant";
CM_ SG_ 1298 TRCM_a118_VEH_vehicleStatus "TRCM ECU: a118 VEH vehicle status";
CM_ SG_ 1298 TRCM_a118_VEH_12VBatteryStatus "TRCM ECU: a118 VEH 12 v battery status";
CM_ SG_ 1298 TRCM_a118_VEH_systemStatus "TRCM ECU: a118 VEH system status";
CM_ SG_ 1298 TRCM_a118_PARTY_LVPowerState "TRCM ECU: a118 PARTY LV power state";
CM_ SG_ 1298 TRCM_a118_PARTY_outputPowerStatu "TRCM ECU: a118 PARTY output power status";
CM_ SG_ 1298 TRCM_a118_PARTY_vehicleTime "TRCM ECU: a118 PARTY vehicle time";
CM_ SG_ 1298 TRCM_a118_VEH_thermalCommand "TRCM ECU: a118 VEH thermal command";
CM_ SG_ 1298 TRCM_a118_CH_LVPowerState "TRCM ECU: a118 CH LV power state";
CM_ SG_ 1298 TRCM_a118_PARTY_sensors "TRCM ECU: a118 PARTY sensors";
CM_ SG_ 1298 TRCM_a118_CH_sensors "TRCM ECU: a118 CH sensors";
CM_ SG_ 1298 TRCM_a118_VEH_interNodeResistanc "TRCM ECU: a118 VEH inter node resistance";
CM_ SG_ 1298 TRCM_a118_CH_lighting "TRCM ECU: a118 CH lighting";
CM_ SG_ 1298 TRCM_a118_VEH_lightStatus "TRCM ECU: a118 VEH light status";
CM_ SG_ 1298 TRCM_a118_PARTY_vehNm "TRCM ECU: a118 PARTY veh nm";
CM_ SG_ 1298 TRCM_a118_CH_12VBatteryStatus "TRCM ECU: a118 CH 12 v battery status";
CM_ SG_ 1298 TRCM_a118_CH_LVBMS_statusHigh "TRCM ECU: a118 CH LVBMS status high";
CM_ SG_ 1298 TRCM_a118_CH_alertMatrix "TRCM ECU: a118 CH alert matrix";
CM_ SG_ 1298 TRCM_a118_BDY_outputPowerStatus "TRCM ECU: a118 BDY output power status";
CM_ SG_ 1298 TRCM_a118_BDY_vehicleTime "TRCM ECU: a118 BDY vehicle time";
CM_ SG_ 1298 TRCM_a118_PARTY_AP_vehicleState1 "TRCM ECU: a118 PARTY AP vehicle state1 hz muxed";
CM_ SG_ 1298 TRCM_a118_BDY_AP_vehicleState1Hz "TRCM ECU: a118 BDY AP vehicle state1 hz muxed";
CM_ SG_ 1298 TRCM_a118_PARTY_VCFRONT_cameraCl "TRCM ECU: a118 PARTY VCFRONT camera cleaning status";
CM_ SG_ 1298 TRCM_a119_VEH_steerAngle "TRCM ECU: a119 VEH steer angle";
CM_ SG_ 1298 TRCM_a119_VEH_leftStalk "TRCM ECU: a119 VEH left stalk";
CM_ SG_ 1298 TRCM_a119_VEH_rightStalk "TRCM ECU: a119 VEH right stalk";
CM_ SG_ 1298 TRCM_a119_PARTY_rightStalk "TRCM ECU: a119 PARTY right stalk";
CM_ SG_ 1298 TRCM_a119_CH_steerAngle "TRCM ECU: a119 CH steer angle";
CM_ SG_ 1298 TRCM_a119_PARTY_steerAngle "TRCM ECU: a119 PARTY steer angle";
CM_ SG_ 1298 TRCM_a120_PARTY_chassisCntl "TRCM ECU: a120 PARTY chassis cntl";
CM_ SG_ 1298 TRCM_a120_VEH_systemStatus "TRCM ECU: a120 VEH system status";
CM_ SG_ 1298 TRCM_a120_CH_chassisCntl "TRCM ECU: a120 CH chassis cntl";
CM_ SG_ 1298 TRCM_a120_PARTY_systemStatus "TRCM ECU: a120 PARTY system status";
CM_ SG_ 1298 TRCM_a120_PARTY_torque "TRCM ECU: a120 PARTY torque";
CM_ SG_ 1298 TRCM_a120_VEH_torque "TRCM ECU: a120 VEH torque";
CM_ SG_ 1298 TRCM_a120_PARTY_locStatus "TRCM ECU: a120 PARTY loc status";
CM_ SG_ 1298 TRCM_a120_PARTY_speed "TRCM ECU: a120 PARTY speed";
CM_ SG_ 1298 TRCM_a120_VEH_speed "TRCM ECU: a120 VEH speed";
CM_ SG_ 1298 TRCM_a120_PARTY_status "TRCM ECU: a120 PARTY status";
CM_ SG_ 1298 TRCM_a120_PT_speed "TRCM ECU: a120 PT speed";
CM_ SG_ 1298 TRCM_a120_PT_systemStatus "TRCM ECU: a120 PT system status";
CM_ SG_ 1298 TRCM_a120_PARTY_vehicleEstimates "TRCM ECU: a120 PARTY vehicle estimates";
CM_ SG_ 1298 TRCM_a120_VEH_aggregatedAxleSpee "TRCM ECU: a120 VEH aggregated axle speed";
CM_ SG_ 1298 TRCM_a120_PARTY_aggregatedAxleSp "TRCM ECU: a120 PARTY aggregated axle speed";
CM_ SG_ 1298 TRCM_a120_VEH_systemPower "TRCM ECU: a120 VEH system power";
CM_ SG_ 1298 TRCM_a120_PARTY_autonomyHealth "TRCM ECU: a120 PARTY autonomy health";
CM_ SG_ 1298 TRCM_a120_VEH_autonomyHealth "TRCM ECU: a120 VEH autonomy health";
CM_ SG_ 1298 TRCM_a120_PT_systemPower "TRCM ECU: a120 PT system power";
CM_ SG_ 1298 TRCM_a120_PARTY_stalklessInterfa "TRCM ECU: a120 PARTY stalkless interfaces";
CM_ SG_ 1298 TRCM_a120_CH_speed "TRCM ECU: a120 CH speed";
CM_ SG_ 1298 TRCM_a120_VEH_estimatedBrakeTemp "TRCM ECU: a120 VEH estimated brake temp";
CM_ SG_ 1298 TRCM_a120_PARTY_prndControl "TRCM ECU: a120 PARTY prnd control";
CM_ SG_ 1298 TRCM_a120_PARTY_locStatus2 "TRCM ECU: a120 PARTY loc status2";
CM_ SG_ 1298 TRCM_a120_VEH_chassisCntl "TRCM ECU: a120 VEH chassis cntl";
CM_ SG_ 1298 TRCM_a120_CH_locStatus2 "TRCM ECU: a120 CH loc status2";
CM_ SG_ 1298 TRCM_a120_VEH_locStatus "TRCM ECU: a120 VEH loc status";
CM_ SG_ 1298 TRCM_a120_VEH_locStatus2 "TRCM ECU: a120 VEH loc status2";
CM_ SG_ 1298 TRCM_a120_VEH_prndControl "TRCM ECU: a120 VEH prnd control";
CM_ SG_ 1298 TRCM_a120_VEH_vehicleEstimates "TRCM ECU: a120 VEH vehicle estimates";
CM_ SG_ 1298 TRCM_a120_PARTY_motorStatus "TRCM ECU: a120 PARTY motor status";
CM_ SG_ 1298 TRCM_a120_VEH_motorStatus "TRCM ECU: a120 VEH motor status";
CM_ SG_ 1298 TRCM_a120_BDY_speed "TRCM ECU: a120 BDY speed";
CM_ SG_ 1298 TRCM_a332_groundLossError "TRCM ECU: a332 ground loss error";
CM_ SG_ 1298 TRCM_a332_overcurrentError "TRCM ECU: a332 overcurrent error";
CM_ SG_ 1298 TRCM_a332_overvoltageError "TRCM ECU: a332 overvoltage error";
CM_ SG_ 1298 TRCM_a332_currentMonitorTimer "TRCM ECU: a332 current monitor timer";
CM_ SG_ 1298 TRCM_a333_groundLossError "TRCM ECU: a333 ground loss error";
CM_ SG_ 1298 TRCM_a333_overcurrentError "TRCM ECU: a333 overcurrent error";
CM_ SG_ 1298 TRCM_a333_overvoltageError "TRCM ECU: a333 overvoltage error";
CM_ SG_ 1298 TRCM_a333_currentMonitorTimer "TRCM ECU: a333 current monitor timer";
CM_ SG_ 1298 TRCM_a334_groundLossError "TRCM ECU: a334 ground loss error";
CM_ SG_ 1298 TRCM_a334_overcurrentError "TRCM ECU: a334 overcurrent error";
CM_ SG_ 1298 TRCM_a334_overvoltageError "TRCM ECU: a334 overvoltage error";
CM_ SG_ 1298 TRCM_a334_currentMonitorTimer "TRCM ECU: a334 current monitor timer";
CM_ SG_ 1298 TRCM_a335_groundLossError "TRCM ECU: a335 ground loss error";
CM_ SG_ 1298 TRCM_a335_overcurrentError "TRCM ECU: a335 overcurrent error";
CM_ SG_ 1298 TRCM_a335_overvoltageError "TRCM ECU: a335 overvoltage error";
CM_ SG_ 1298 TRCM_a335_currentMonitorTimer "TRCM ECU: a335 current monitor timer";
CM_ SG_ 1298 TRCM_a336_groundLossError "TRCM ECU: a336 ground loss error";
CM_ SG_ 1298 TRCM_a336_overcurrentError "TRCM ECU: a336 overcurrent error";
CM_ SG_ 1298 TRCM_a336_overvoltageError "TRCM ECU: a336 overvoltage error";
CM_ SG_ 1298 TRCM_a336_currentMonitorTimer "TRCM ECU: a336 current monitor timer";
CM_ SG_ 1298 TRCM_a337_groundLossError "TRCM ECU: a337 ground loss error";
CM_ SG_ 1298 TRCM_a337_overcurrentError "TRCM ECU: a337 overcurrent error";
CM_ SG_ 1298 TRCM_a337_overvoltageError "TRCM ECU: a337 overvoltage error";
CM_ SG_ 1298 TRCM_a337_currentMonitorTimer "TRCM ECU: a337 current monitor timer";
CM_ SG_ 1298 TRCM_a338_groundLossError "TRCM ECU: a338 ground loss error";
CM_ SG_ 1298 TRCM_a338_overcurrentError "TRCM ECU: a338 overcurrent error";
CM_ SG_ 1298 TRCM_a338_overvoltageError "TRCM ECU: a338 overvoltage error";
CM_ SG_ 1298 TRCM_a338_currentMonitorTimer "TRCM ECU: a338 current monitor timer";
CM_ SG_ 1298 TRCM_a340_groundLossError "TRCM ECU: a340 ground loss error";
CM_ SG_ 1298 TRCM_a340_overcurrentError "TRCM ECU: a340 overcurrent error";
CM_ SG_ 1298 TRCM_a340_overvoltageError "TRCM ECU: a340 overvoltage error";
CM_ SG_ 1298 TRCM_a340_currentMonitorTimer "TRCM ECU: a340 current monitor timer";
CM_ SG_ 1298 TRCM_a341_groundLossError "TRCM ECU: a341 ground loss error";
CM_ SG_ 1298 TRCM_a341_overcurrentError "TRCM ECU: a341 overcurrent error";
CM_ SG_ 1298 TRCM_a341_overvoltageError "TRCM ECU: a341 overvoltage error";
CM_ SG_ 1298 TRCM_a341_currentMonitorTimer "TRCM ECU: a341 current monitor timer";
CM_ SG_ 1298 TRCM_a342_groundLossError "TRCM ECU: a342 ground loss error";
CM_ SG_ 1298 TRCM_a342_overcurrentError "TRCM ECU: a342 overcurrent error";
CM_ SG_ 1298 TRCM_a342_overvoltageError "TRCM ECU: a342 overvoltage error";
CM_ SG_ 1298 TRCM_a342_currentMonitorTimer "TRCM ECU: a342 current monitor timer";
CM_ SG_ 1298 TRCM_a343_groundLossError "TRCM ECU: a343 ground loss error";
CM_ SG_ 1298 TRCM_a343_overcurrentError "TRCM ECU: a343 overcurrent error";
CM_ SG_ 1298 TRCM_a343_overvoltageError "TRCM ECU: a343 overvoltage error";
CM_ SG_ 1298 TRCM_a343_currentMonitorTimer "TRCM ECU: a343 current monitor timer";
CM_ SG_ 1298 TRCM_a344_groundLossError "TRCM ECU: a344 ground loss error";
CM_ SG_ 1298 TRCM_a344_overcurrentError "TRCM ECU: a344 overcurrent error";
CM_ SG_ 1298 TRCM_a344_overvoltageError "TRCM ECU: a344 overvoltage error";
CM_ SG_ 1298 TRCM_a344_currentMonitorTimer "TRCM ECU: a344 current monitor timer";
CM_ SG_ 1298 TRCM_a345_groundLossError "TRCM ECU: a345 ground loss error";
CM_ SG_ 1298 TRCM_a345_overcurrentError "TRCM ECU: a345 overcurrent error";
CM_ SG_ 1298 TRCM_a345_overvoltageError "TRCM ECU: a345 overvoltage error";
CM_ SG_ 1298 TRCM_a345_currentMonitorTimer "TRCM ECU: a345 current monitor timer";
CM_ SG_ 1298 TRCM_a346_groundLossError "TRCM ECU: a346 ground loss error";
CM_ SG_ 1298 TRCM_a346_overcurrentError "TRCM ECU: a346 overcurrent error";
CM_ SG_ 1298 TRCM_a346_overvoltageError "TRCM ECU: a346 overvoltage error";
CM_ SG_ 1298 TRCM_a346_currentMonitorTimer "TRCM ECU: a346 current monitor timer";
CM_ SG_ 1298 TRCM_a347_groundLossError "TRCM ECU: a347 ground loss error";
CM_ SG_ 1298 TRCM_a347_overcurrentError "TRCM ECU: a347 overcurrent error";
CM_ SG_ 1298 TRCM_a347_overvoltageError "TRCM ECU: a347 overvoltage error";
CM_ SG_ 1298 TRCM_a347_currentMonitorTimer "TRCM ECU: a347 current monitor timer";
CM_ SG_ 1298 TRCM_a348_groundLossError "TRCM ECU: a348 ground loss error";
CM_ SG_ 1298 TRCM_a348_overcurrentError "TRCM ECU: a348 overcurrent error";
CM_ SG_ 1298 TRCM_a348_overvoltageError "TRCM ECU: a348 overvoltage error";
CM_ SG_ 1298 TRCM_a348_currentMonitorTimer "TRCM ECU: a348 current monitor timer";
CM_ SG_ 1298 TRCM_a349_groundLossError "TRCM ECU: a349 ground loss error";
CM_ SG_ 1298 TRCM_a349_overcurrentError "TRCM ECU: a349 overcurrent error";
CM_ SG_ 1298 TRCM_a349_overvoltageError "TRCM ECU: a349 overvoltage error";
CM_ SG_ 1298 TRCM_a349_currentMonitorTimer "TRCM ECU: a349 current monitor timer";
CM_ SG_ 1298 TRCM_a350_groundLossError "TRCM ECU: a350 ground loss error";
CM_ SG_ 1298 TRCM_a350_overcurrentError "TRCM ECU: a350 overcurrent error";
CM_ SG_ 1298 TRCM_a350_overvoltageError "TRCM ECU: a350 overvoltage error";
CM_ SG_ 1298 TRCM_a350_currentMonitorTimer "TRCM ECU: a350 current monitor timer";
CM_ SG_ 1298 TRCM_a351_groundLossError "TRCM ECU: a351 ground loss error";
CM_ SG_ 1298 TRCM_a351_overcurrentError "TRCM ECU: a351 overcurrent error";
CM_ SG_ 1298 TRCM_a351_overvoltageError "TRCM ECU: a351 overvoltage error";
CM_ SG_ 1298 TRCM_a351_currentMonitorTimer "TRCM ECU: a351 current monitor timer";
CM_ SG_ 1298 TRCM_a352_groundLossError "TRCM ECU: a352 ground loss error";
CM_ SG_ 1298 TRCM_a352_overcurrentError "TRCM ECU: a352 overcurrent error";
CM_ SG_ 1298 TRCM_a352_overvoltageError "TRCM ECU: a352 overvoltage error";
CM_ SG_ 1298 TRCM_a352_currentMonitorTimer "TRCM ECU: a352 current monitor timer";
CM_ SG_ 1298 TRCM_a353_groundLossError "TRCM ECU: a353 ground loss error";
CM_ SG_ 1298 TRCM_a353_overcurrentError "TRCM ECU: a353 overcurrent error";
CM_ SG_ 1298 TRCM_a353_overvoltageError "TRCM ECU: a353 overvoltage error";
CM_ SG_ 1298 TRCM_a353_currentMonitorTimer "TRCM ECU: a353 current monitor timer";
CM_ SG_ 1298 TRCM_a354_groundLossError "TRCM ECU: a354 ground loss error";
CM_ SG_ 1298 TRCM_a354_overcurrentError "TRCM ECU: a354 overcurrent error";
CM_ SG_ 1298 TRCM_a354_overvoltageError "TRCM ECU: a354 overvoltage error";
CM_ SG_ 1298 TRCM_a354_currentMonitorTimer "TRCM ECU: a354 current monitor timer";
CM_ SG_ 1298 TRCM_a355_groundLossError "TRCM ECU: a355 ground loss error";
CM_ SG_ 1298 TRCM_a355_overcurrentError "TRCM ECU: a355 overcurrent error";
CM_ SG_ 1298 TRCM_a355_overvoltageError "TRCM ECU: a355 overvoltage error";
CM_ SG_ 1298 TRCM_a355_currentMonitorTimer "TRCM ECU: a355 current monitor timer";
CM_ SG_ 1298 TRCM_a400_deploymentLoopNumber "TRCM ECU: a400 deployment loop number";
CM_ SG_ 1298 TRCM_a400_resistance "TRCM ECU: a400 resistance; raw 255 = signal not available (SNA)";
CM_ SG_ 1298 TRCM_a400_shortToGround "TRCM ECU: a400 short to ground";
CM_ SG_ 1298 TRCM_a400_shortToBattery "TRCM ECU: a400 short to battery";
CM_ SG_ 1298 TRCM_a400_shortToSelf "TRCM ECU: a400 short to self";
CM_ SG_ 1298 TRCM_a400_openCircuit "TRCM ECU: a400 open circuit";
CM_ SG_ 1298 TRCM_a400_crossCoupled "TRCM ECU: a400 cross coupled";
CM_ SG_ 1298 TRCM_a400_resistanceOutOfSpec "TRCM ECU: a400 resistance out of spec";
CM_ SG_ 1298 TRCM_a401_deploymentLoopNumber "TRCM ECU: a401 deployment loop number";
CM_ SG_ 1298 TRCM_a401_resistance "TRCM ECU: a401 resistance; raw 255 = signal not available (SNA)";
CM_ SG_ 1298 TRCM_a401_shortToGround "TRCM ECU: a401 short to ground";
CM_ SG_ 1298 TRCM_a401_shortToBattery "TRCM ECU: a401 short to battery";
CM_ SG_ 1298 TRCM_a401_shortToSelf "TRCM ECU: a401 short to self";
CM_ SG_ 1298 TRCM_a401_openCircuit "TRCM ECU: a401 open circuit";
CM_ SG_ 1298 TRCM_a401_crossCoupled "TRCM ECU: a401 cross coupled";
CM_ SG_ 1298 TRCM_a401_resistanceOutOfSpec "TRCM ECU: a401 resistance out of spec";
CM_ SG_ 1298 TRCM_a402_deploymentLoopNumber "TRCM ECU: a402 deployment loop number";
CM_ SG_ 1298 TRCM_a402_resistance "TRCM ECU: a402 resistance; raw 255 = signal not available (SNA)";
CM_ SG_ 1298 TRCM_a402_shortToGround "TRCM ECU: a402 short to ground";
CM_ SG_ 1298 TRCM_a402_shortToBattery "TRCM ECU: a402 short to battery";
CM_ SG_ 1298 TRCM_a402_shortToSelf "TRCM ECU: a402 short to self";
CM_ SG_ 1298 TRCM_a402_openCircuit "TRCM ECU: a402 open circuit";
CM_ SG_ 1298 TRCM_a402_crossCoupled "TRCM ECU: a402 cross coupled";
CM_ SG_ 1298 TRCM_a402_resistanceOutOfSpec "TRCM ECU: a402 resistance out of spec";
CM_ SG_ 1298 TRCM_a403_deploymentLoopNumber "TRCM ECU: a403 deployment loop number";
CM_ SG_ 1298 TRCM_a403_resistance "TRCM ECU: a403 resistance; raw 255 = signal not available (SNA)";
CM_ SG_ 1298 TRCM_a403_shortToGround "TRCM ECU: a403 short to ground";
CM_ SG_ 1298 TRCM_a403_shortToBattery "TRCM ECU: a403 short to battery";
CM_ SG_ 1298 TRCM_a403_shortToSelf "TRCM ECU: a403 short to self";
CM_ SG_ 1298 TRCM_a403_openCircuit "TRCM ECU: a403 open circuit";
CM_ SG_ 1298 TRCM_a403_crossCoupled "TRCM ECU: a403 cross coupled";
CM_ SG_ 1298 TRCM_a403_resistanceOutOfSpec "TRCM ECU: a403 resistance out of spec";
CM_ SG_ 1298 TRCM_a404_deploymentLoopNumber "TRCM ECU: a404 deployment loop number";
CM_ SG_ 1298 TRCM_a404_resistance "TRCM ECU: a404 resistance; raw 255 = signal not available (SNA)";
CM_ SG_ 1298 TRCM_a404_shortToGround "TRCM ECU: a404 short to ground";
CM_ SG_ 1298 TRCM_a404_shortToBattery "TRCM ECU: a404 short to battery";
CM_ SG_ 1298 TRCM_a404_shortToSelf "TRCM ECU: a404 short to self";
CM_ SG_ 1298 TRCM_a404_openCircuit "TRCM ECU: a404 open circuit";
CM_ SG_ 1298 TRCM_a404_crossCoupled "TRCM ECU: a404 cross coupled";
CM_ SG_ 1298 TRCM_a404_resistanceOutOfSpec "TRCM ECU: a404 resistance out of spec";
CM_ SG_ 1298 TRCM_a405_deploymentLoopNumber "TRCM ECU: a405 deployment loop number";
CM_ SG_ 1298 TRCM_a405_resistance "TRCM ECU: a405 resistance; raw 255 = signal not available (SNA)";
CM_ SG_ 1298 TRCM_a405_shortToGround "TRCM ECU: a405 short to ground";
CM_ SG_ 1298 TRCM_a405_shortToBattery "TRCM ECU: a405 short to battery";
CM_ SG_ 1298 TRCM_a405_shortToSelf "TRCM ECU: a405 short to self";
CM_ SG_ 1298 TRCM_a405_openCircuit "TRCM ECU: a405 open circuit";
CM_ SG_ 1298 TRCM_a405_crossCoupled "TRCM ECU: a405 cross coupled";
CM_ SG_ 1298 TRCM_a405_resistanceOutOfSpec "TRCM ECU: a405 resistance out of spec";
CM_ SG_ 1298 TRCM_a406_deploymentLoopNumber "TRCM ECU: a406 deployment loop number";
CM_ SG_ 1298 TRCM_a406_resistance "TRCM ECU: a406 resistance; raw 255 = signal not available (SNA)";
CM_ SG_ 1298 TRCM_a406_shortToGround "TRCM ECU: a406 short to ground";
CM_ SG_ 1298 TRCM_a406_shortToBattery "TRCM ECU: a406 short to battery";
CM_ SG_ 1298 TRCM_a406_shortToSelf "TRCM ECU: a406 short to self";
CM_ SG_ 1298 TRCM_a406_openCircuit "TRCM ECU: a406 open circuit";
CM_ SG_ 1298 TRCM_a406_crossCoupled "TRCM ECU: a406 cross coupled";
CM_ SG_ 1298 TRCM_a406_resistanceOutOfSpec "TRCM ECU: a406 resistance out of spec";
CM_ SG_ 1298 TRCM_a408_deploymentLoopNumber "TRCM ECU: a408 deployment loop number";
CM_ SG_ 1298 TRCM_a408_resistance "TRCM ECU: a408 resistance; raw 255 = signal not available (SNA)";
CM_ SG_ 1298 TRCM_a408_shortToGround "TRCM ECU: a408 short to ground";
CM_ SG_ 1298 TRCM_a408_shortToBattery "TRCM ECU: a408 short to battery";
CM_ SG_ 1298 TRCM_a408_shortToSelf "TRCM ECU: a408 short to self";
CM_ SG_ 1298 TRCM_a408_openCircuit "TRCM ECU: a408 open circuit";
CM_ SG_ 1298 TRCM_a408_crossCoupled "TRCM ECU: a408 cross coupled";
CM_ SG_ 1298 TRCM_a408_resistanceOutOfSpec "TRCM ECU: a408 resistance out of spec";
CM_ SG_ 1298 TRCM_a409_deploymentLoopNumber "TRCM ECU: a409 deployment loop number";
CM_ SG_ 1298 TRCM_a409_resistance "TRCM ECU: a409 resistance; raw 255 = signal not available (SNA)";
CM_ SG_ 1298 TRCM_a409_shortToGround "TRCM ECU: a409 short to ground";
CM_ SG_ 1298 TRCM_a409_shortToBattery "TRCM ECU: a409 short to battery";
CM_ SG_ 1298 TRCM_a409_shortToSelf "TRCM ECU: a409 short to self";
CM_ SG_ 1298 TRCM_a409_openCircuit "TRCM ECU: a409 open circuit";
CM_ SG_ 1298 TRCM_a409_crossCoupled "TRCM ECU: a409 cross coupled";
CM_ SG_ 1298 TRCM_a409_resistanceOutOfSpec "TRCM ECU: a409 resistance out of spec";
CM_ SG_ 1298 TRCM_a410_deploymentLoopNumber "TRCM ECU: a410 deployment loop number";
CM_ SG_ 1298 TRCM_a410_resistance "TRCM ECU: a410 resistance; raw 255 = signal not available (SNA)";
CM_ SG_ 1298 TRCM_a410_shortToGround "TRCM ECU: a410 short to ground";
CM_ SG_ 1298 TRCM_a410_shortToBattery "TRCM ECU: a410 short to battery";
CM_ SG_ 1298 TRCM_a410_shortToSelf "TRCM ECU: a410 short to self";
CM_ SG_ 1298 TRCM_a410_openCircuit "TRCM ECU: a410 open circuit";
CM_ SG_ 1298 TRCM_a410_crossCoupled "TRCM ECU: a410 cross coupled";
CM_ SG_ 1298 TRCM_a410_resistanceOutOfSpec "TRCM ECU: a410 resistance out of spec";
CM_ SG_ 1298 TRCM_a411_deploymentLoopNumber "TRCM ECU: a411 deployment loop number";
CM_ SG_ 1298 TRCM_a411_resistance "TRCM ECU: a411 resistance; raw 255 = signal not available (SNA)";
CM_ SG_ 1298 TRCM_a411_shortToGround "TRCM ECU: a411 short to ground";
CM_ SG_ 1298 TRCM_a411_shortToBattery "TRCM ECU: a411 short to battery";
CM_ SG_ 1298 TRCM_a411_shortToSelf "TRCM ECU: a411 short to self";
CM_ SG_ 1298 TRCM_a411_openCircuit "TRCM ECU: a411 open circuit";
CM_ SG_ 1298 TRCM_a411_crossCoupled "TRCM ECU: a411 cross coupled";
CM_ SG_ 1298 TRCM_a411_resistanceOutOfSpec "TRCM ECU: a411 resistance out of spec";
CM_ SG_ 1298 TRCM_a412_deploymentLoopNumber "TRCM ECU: a412 deployment loop number";
CM_ SG_ 1298 TRCM_a412_resistance "TRCM ECU: a412 resistance; raw 255 = signal not available (SNA)";
CM_ SG_ 1298 TRCM_a412_shortToGround "TRCM ECU: a412 short to ground";
CM_ SG_ 1298 TRCM_a412_shortToBattery "TRCM ECU: a412 short to battery";
CM_ SG_ 1298 TRCM_a412_shortToSelf "TRCM ECU: a412 short to self";
CM_ SG_ 1298 TRCM_a412_openCircuit "TRCM ECU: a412 open circuit";
CM_ SG_ 1298 TRCM_a412_crossCoupled "TRCM ECU: a412 cross coupled";
CM_ SG_ 1298 TRCM_a412_resistanceOutOfSpec "TRCM ECU: a412 resistance out of spec";
CM_ SG_ 1298 TRCM_a413_deploymentLoopNumber "TRCM ECU: a413 deployment loop number";
CM_ SG_ 1298 TRCM_a413_resistance "TRCM ECU: a413 resistance; raw 255 = signal not available (SNA)";
CM_ SG_ 1298 TRCM_a413_shortToGround "TRCM ECU: a413 short to ground";
CM_ SG_ 1298 TRCM_a413_shortToBattery "TRCM ECU: a413 short to battery";
CM_ SG_ 1298 TRCM_a413_shortToSelf "TRCM ECU: a413 short to self";
CM_ SG_ 1298 TRCM_a413_openCircuit "TRCM ECU: a413 open circuit";
CM_ SG_ 1298 TRCM_a413_crossCoupled "TRCM ECU: a413 cross coupled";
CM_ SG_ 1298 TRCM_a413_resistanceOutOfSpec "TRCM ECU: a413 resistance out of spec";
CM_ SG_ 1298 TRCM_a414_deploymentLoopNumber "TRCM ECU: a414 deployment loop number";
CM_ SG_ 1298 TRCM_a414_resistance "TRCM ECU: a414 resistance; raw 255 = signal not available (SNA)";
CM_ SG_ 1298 TRCM_a414_shortToGround "TRCM ECU: a414 short to ground";
CM_ SG_ 1298 TRCM_a414_shortToBattery "TRCM ECU: a414 short to battery";
CM_ SG_ 1298 TRCM_a414_shortToSelf "TRCM ECU: a414 short to self";
CM_ SG_ 1298 TRCM_a414_openCircuit "TRCM ECU: a414 open circuit";
CM_ SG_ 1298 TRCM_a414_crossCoupled "TRCM ECU: a414 cross coupled";
CM_ SG_ 1298 TRCM_a414_resistanceOutOfSpec "TRCM ECU: a414 resistance out of spec";
CM_ SG_ 1298 TRCM_a415_deploymentLoopNumber "TRCM ECU: a415 deployment loop number";
CM_ SG_ 1298 TRCM_a415_resistance "TRCM ECU: a415 resistance; raw 255 = signal not available (SNA)";
CM_ SG_ 1298 TRCM_a415_shortToGround "TRCM ECU: a415 short to ground";
CM_ SG_ 1298 TRCM_a415_shortToBattery "TRCM ECU: a415 short to battery";
CM_ SG_ 1298 TRCM_a415_shortToSelf "TRCM ECU: a415 short to self";
CM_ SG_ 1298 TRCM_a415_openCircuit "TRCM ECU: a415 open circuit";
CM_ SG_ 1298 TRCM_a415_crossCoupled "TRCM ECU: a415 cross coupled";
CM_ SG_ 1298 TRCM_a415_resistanceOutOfSpec "TRCM ECU: a415 resistance out of spec";
CM_ SG_ 1298 TRCM_a416_deploymentLoopNumber "TRCM ECU: a416 deployment loop number";
CM_ SG_ 1298 TRCM_a416_resistance "TRCM ECU: a416 resistance; raw 255 = signal not available (SNA)";
CM_ SG_ 1298 TRCM_a416_shortToGround "TRCM ECU: a416 short to ground";
CM_ SG_ 1298 TRCM_a416_shortToBattery "TRCM ECU: a416 short to battery";
CM_ SG_ 1298 TRCM_a416_shortToSelf "TRCM ECU: a416 short to self";
CM_ SG_ 1298 TRCM_a416_openCircuit "TRCM ECU: a416 open circuit";
CM_ SG_ 1298 TRCM_a416_crossCoupled "TRCM ECU: a416 cross coupled";
CM_ SG_ 1298 TRCM_a416_resistanceOutOfSpec "TRCM ECU: a416 resistance out of spec";
CM_ SG_ 1298 TRCM_a417_deploymentLoopNumber "TRCM ECU: a417 deployment loop number";
CM_ SG_ 1298 TRCM_a417_resistance "TRCM ECU: a417 resistance; raw 255 = signal not available (SNA)";
CM_ SG_ 1298 TRCM_a417_shortToGround "TRCM ECU: a417 short to ground";
CM_ SG_ 1298 TRCM_a417_shortToBattery "TRCM ECU: a417 short to battery";
CM_ SG_ 1298 TRCM_a417_shortToSelf "TRCM ECU: a417 short to self";
CM_ SG_ 1298 TRCM_a417_openCircuit "TRCM ECU: a417 open circuit";
CM_ SG_ 1298 TRCM_a417_crossCoupled "TRCM ECU: a417 cross coupled";
CM_ SG_ 1298 TRCM_a417_resistanceOutOfSpec "TRCM ECU: a417 resistance out of spec";
CM_ SG_ 1298 TRCM_a418_deploymentLoopNumber "TRCM ECU: a418 deployment loop number";
CM_ SG_ 1298 TRCM_a418_resistance "TRCM ECU: a418 resistance; raw 255 = signal not available (SNA)";
CM_ SG_ 1298 TRCM_a418_shortToGround "TRCM ECU: a418 short to ground";
CM_ SG_ 1298 TRCM_a418_shortToBattery "TRCM ECU: a418 short to battery";
CM_ SG_ 1298 TRCM_a418_shortToSelf "TRCM ECU: a418 short to self";
CM_ SG_ 1298 TRCM_a418_openCircuit "TRCM ECU: a418 open circuit";
CM_ SG_ 1298 TRCM_a418_crossCoupled "TRCM ECU: a418 cross coupled";
CM_ SG_ 1298 TRCM_a418_resistanceOutOfSpec "TRCM ECU: a418 resistance out of spec";
CM_ SG_ 1298 TRCM_a419_deploymentLoopNumber "TRCM ECU: a419 deployment loop number";
CM_ SG_ 1298 TRCM_a419_resistance "TRCM ECU: a419 resistance; raw 255 = signal not available (SNA)";
CM_ SG_ 1298 TRCM_a419_shortToGround "TRCM ECU: a419 short to ground";
CM_ SG_ 1298 TRCM_a419_shortToBattery "TRCM ECU: a419 short to battery";
CM_ SG_ 1298 TRCM_a419_shortToSelf "TRCM ECU: a419 short to self";
CM_ SG_ 1298 TRCM_a419_openCircuit "TRCM ECU: a419 open circuit";
CM_ SG_ 1298 TRCM_a419_crossCoupled "TRCM ECU: a419 cross coupled";
CM_ SG_ 1298 TRCM_a419_resistanceOutOfSpec "TRCM ECU: a419 resistance out of spec";
CM_ SG_ 1298 TRCM_a420_deploymentLoopNumber "TRCM ECU: a420 deployment loop number";
CM_ SG_ 1298 TRCM_a420_resistance "TRCM ECU: a420 resistance; raw 255 = signal not available (SNA)";
CM_ SG_ 1298 TRCM_a420_shortToGround "TRCM ECU: a420 short to ground";
CM_ SG_ 1298 TRCM_a420_shortToBattery "TRCM ECU: a420 short to battery";
CM_ SG_ 1298 TRCM_a420_shortToSelf "TRCM ECU: a420 short to self";
CM_ SG_ 1298 TRCM_a420_openCircuit "TRCM ECU: a420 open circuit";
CM_ SG_ 1298 TRCM_a420_crossCoupled "TRCM ECU: a420 cross coupled";
CM_ SG_ 1298 TRCM_a420_resistanceOutOfSpec "TRCM ECU: a420 resistance out of spec";
CM_ SG_ 1298 TRCM_a421_deploymentLoopNumber "TRCM ECU: a421 deployment loop number";
CM_ SG_ 1298 TRCM_a421_resistance "TRCM ECU: a421 resistance; raw 255 = signal not available (SNA)";
CM_ SG_ 1298 TRCM_a421_shortToGround "TRCM ECU: a421 short to ground";
CM_ SG_ 1298 TRCM_a421_shortToBattery "TRCM ECU: a421 short to battery";
CM_ SG_ 1298 TRCM_a421_shortToSelf "TRCM ECU: a421 short to self";
CM_ SG_ 1298 TRCM_a421_openCircuit "TRCM ECU: a421 open circuit";
CM_ SG_ 1298 TRCM_a421_crossCoupled "TRCM ECU: a421 cross coupled";
CM_ SG_ 1298 TRCM_a421_resistanceOutOfSpec "TRCM ECU: a421 resistance out of spec";
CM_ SG_ 1298 TRCM_a422_deploymentLoopNumber "TRCM ECU: a422 deployment loop number";
CM_ SG_ 1298 TRCM_a422_resistance "TRCM ECU: a422 resistance; raw 255 = signal not available (SNA)";
CM_ SG_ 1298 TRCM_a422_shortToGround "TRCM ECU: a422 short to ground";
CM_ SG_ 1298 TRCM_a422_shortToBattery "TRCM ECU: a422 short to battery";
CM_ SG_ 1298 TRCM_a422_shortToSelf "TRCM ECU: a422 short to self";
CM_ SG_ 1298 TRCM_a422_openCircuit "TRCM ECU: a422 open circuit";
CM_ SG_ 1298 TRCM_a422_crossCoupled "TRCM ECU: a422 cross coupled";
CM_ SG_ 1298 TRCM_a422_resistanceOutOfSpec "TRCM ECU: a422 resistance out of spec";
CM_ SG_ 1298 TRCM_a423_deploymentLoopNumber "TRCM ECU: a423 deployment loop number";
CM_ SG_ 1298 TRCM_a423_resistance "TRCM ECU: a423 resistance; raw 255 = signal not available (SNA)";
CM_ SG_ 1298 TRCM_a423_shortToGround "TRCM ECU: a423 short to ground";
CM_ SG_ 1298 TRCM_a423_shortToBattery "TRCM ECU: a423 short to battery";
CM_ SG_ 1298 TRCM_a423_shortToSelf "TRCM ECU: a423 short to self";
CM_ SG_ 1298 TRCM_a423_openCircuit "TRCM ECU: a423 open circuit";
CM_ SG_ 1298 TRCM_a423_crossCoupled "TRCM ECU: a423 cross coupled";
CM_ SG_ 1298 TRCM_a423_resistanceOutOfSpec "TRCM ECU: a423 resistance out of spec";
BA_DEF_ BO_ "GenMsgCycleTime" INT 0 3600000;
BA_DEF_ BO_ "GenMsgSendType" ENUM "Cyclic","NotUsed","NotUsed","NotUsed","NotUsed","NotUsed","NotUsed","IfActive","NoMsgSendType","NotUsed";
BA_DEF_ BO_ "VFrameFormat" ENUM "StandardCAN","ExtendedCAN","reserved","J1939PG","reserved","reserved","reserved","reserved","reserved","reserved","reserved","reserved","reserved","reserved","StandardCAN_FD","ExtendedCAN_FD";
BA_DEF_ BO_ "CANFD_BRS" ENUM "0","1";
BA_DEF_ SG_ "GenSigSNA" STRING;
BA_DEF_ SG_ "SystemSignalLongSymbol" STRING;
BA_DEF_ SG_ "Confidence" ENUM "validated","plausible","layout-only","contradicted";
BA_DEF_DEF_ "GenMsgCycleTime" 0;
BA_DEF_DEF_ "GenMsgSendType" "NoMsgSendType";
BA_DEF_DEF_ "VFrameFormat" "StandardCAN";
BA_DEF_DEF_ "CANFD_BRS" "1";
BA_DEF_DEF_ "GenSigSNA" "";
BA_DEF_DEF_ "SystemSignalLongSymbol" "";
BA_DEF_DEF_ "Confidence" "layout-only";
BA_ "GenMsgCycleTime" BO_ 881 1000;
BA_ "GenMsgSendType" BO_ 881 0;
BA_ "GenMsgCycleTime" BO_ 1415 1000;
BA_ "GenMsgSendType" BO_ 1415 0;
BA_ "GenMsgCycleTime" BO_ 1414 1000;
BA_ "GenMsgSendType" BO_ 1414 0;
BA_ "GenMsgCycleTime" BO_ 1412 1000;
BA_ "GenMsgSendType" BO_ 1412 0;
BA_ "GenMsgCycleTime" BO_ 1159 1000;
BA_ "GenMsgSendType" BO_ 1159 0;
BA_ "GenMsgCycleTime" BO_ 1158 1000;
BA_ "GenMsgSendType" BO_ 1158 0;
BA_ "GenMsgCycleTime" BO_ 1155 1000;
BA_ "GenMsgSendType" BO_ 1155 0;
BA_ "Confidence" SG_ 1297 RCM_a117_eventDriveOrientation 1;
BA_ "Confidence" SG_ 1297 RCM_a117_eventIDFsignal 1;
BA_ "Confidence" SG_ 1297 RCM_a117_eventFrontLeftSeatbelt 1;
BA_ "Confidence" SG_ 1297 RCM_a117_eventFrontRightSeatbelt 1;
BA_ "Confidence" SG_ 1297 RCM_a117_eventVehicleSpeed 1;
BA_ "Confidence" SG_ 1297 RCM_a117_eventSteeringAngle 1;
BA_ "Confidence" SG_ 1297 RCM_a117_eventDriverBrakeApply 1;
BA_ "GenSigSNA" SG_ 1297 RCM_a117_eventDriverBrakeApply "3";
BA_ "Confidence" SG_ 1297 RCM_a117_eventAccelPedalPos 1;
BA_ "GenSigSNA" SG_ 1297 RCM_a117_eventAccelPedalPos "255";
BA_ "Confidence" SG_ 1297 RCM_a118_eventArmStatus 1;
BA_ "Confidence" SG_ 1297 RCM_a118_eventFactoryMode 1;
BA_ "Confidence" SG_ 1297 RCM_a118_eventDiagEnabled 1;
BA_ "Confidence" SG_ 1297 RCM_a118_eventDriveOrientation 1;
BA_ "Confidence" SG_ 1297 RCM_a118_eventIDFsignal 1;
BA_ "Confidence" SG_ 1297 RCM_a118_eventFrontLeftSeatbelt 1;
BA_ "Confidence" SG_ 1297 RCM_a118_eventFrontRightSeatbelt 1;
BA_ "Confidence" SG_ 1297 RCM_a118_eventVehicleSpeed 1;
BA_ "Confidence" SG_ 1297 RCM_a118_eventSteeringAngle 1;
BA_ "Confidence" SG_ 1297 RCM_a118_eventDriverBrakeApply 1;
BA_ "GenSigSNA" SG_ 1297 RCM_a118_eventDriverBrakeApply "3";
BA_ "Confidence" SG_ 1297 RCM_a118_eventAccelPedalPos 1;
BA_ "GenSigSNA" SG_ 1297 RCM_a118_eventAccelPedalPos "255";
BA_ "Confidence" SG_ 881 RCM_matrixIndex 1;
BA_ "Confidence" SG_ 1415 TCU2_tc10Version 0;
BA_ "GenSigSNA" SG_ 1415 TCU2_tc10Version "0";
BA_ "Confidence" SG_ 1413 TCU2_alertID 1;
BA_ "Confidence" SG_ 1413 TCU2_alertState 1;
BA_ "Confidence" SG_ 1413 TCU2_w012_DataRAT 1;
BA_ "Confidence" SG_ 1413 TCU2_w012_RSRP 1;
BA_ "Confidence" SG_ 1413 TCU2_w012_RSRQ 1;
BA_ "Confidence" SG_ 1413 TCU2_w012_AvgQueueUsage 1;
BA_ "Confidence" SG_ 1413 TCU2_w012_NSAAvailable 1;
BA_ "Confidence" SG_ 1413 TCU2_w013_DataRAT 1;
BA_ "Confidence" SG_ 1413 TCU2_w013_RSRP 1;
BA_ "Confidence" SG_ 1413 TCU2_w013_RSRQ 1;
BA_ "Confidence" SG_ 1413 TCU2_w013_AvgQueueUsage 1;
BA_ "Confidence" SG_ 1413 TCU2_w013_NSAAvailable 1;
BA_ "Confidence" SG_ 1412 TCU2_logMux 1;
BA_ "Confidence" SG_ 1412 TCU2_cpuTemp 0;
BA_ "Confidence" SG_ 1412 TCU2_cpuUsage 0;
BA_ "Confidence" SG_ 1412 TCU2_mdmCoreTemperature 0;
BA_ "Confidence" SG_ 1412 TCU2_availableMemory 0;
BA_ "Confidence" SG_ 1412 TCU2_pwm 0;
BA_ "Confidence" SG_ 1412 TCU2_pwmcap 0;
BA_ "Confidence" SG_ 1412 TCU2_totalResumes 0;
BA_ "Confidence" SG_ 1412 TCU2_mdmUplinkQueueSize 0;
BA_ "Confidence" SG_ 1412 TCU2_mdmRSRP 0;
BA_ "Confidence" SG_ 1412 TCU2_mdmSINR 0;
BA_ "Confidence" SG_ 1412 TCU2_mdmUplinkAllowedRate 0;
BA_ "Confidence" SG_ 1412 TCU2_mdmUplinkAvgRate 0;
BA_ "Confidence" SG_ 1412 TCU2_mdmServiceState 0;
BA_ "Confidence" SG_ 1412 TCU2_mdmIMSStatus 0;
BA_ "Confidence" SG_ 1412 TCU2_mdmSIMStatus 0;
BA_ "Confidence" SG_ 1412 TCU2_mdmBusyActive 0;
BA_ "GenSigSNA" SG_ 1412 TCU2_mdmBusyActive "4294967295";
BA_ "Confidence" SG_ 1412 TCU2_modemUptime 0;
BA_ "Confidence" SG_ 1412 TCU2_mdmDataRat 0;
BA_ "Confidence" SG_ 1412 TCU2_mdmDataCallStatus 0;
BA_ "Confidence" SG_ 1412 TCU2_mdmNSAAvailable 0;
BA_ "Confidence" SG_ 1412 TCU2_mdmPCIID 0;
BA_ "Confidence" SG_ 1412 TCU2_mdmMnc 0;
BA_ "Confidence" SG_ 1412 TCU2_mdmMcc 0;
BA_ "Confidence" SG_ 1412 TCU2_mdmTxKiloBytes 0;
BA_ "Confidence" SG_ 1412 TCU2_mdmDataCallTermReason 0;
BA_ "Confidence" SG_ 1412 TCU2_mdmDataCallTermCode 0;
BA_ "Confidence" SG_ 1412 TCU2_cellularSMState 0;
BA_ "Confidence" SG_ 1412 TCU2_tcuSMState 0;
BA_ "Confidence" SG_ 1412 TCU2_checkInternetFailCount 0;
BA_ "Confidence" SG_ 1412 TCU2_mdmBand 0;
BA_ "Confidence" SG_ 1412 TCU2_wakeSource 0;
BA_ "Confidence" SG_ 1159 TCU_tc10Version 0;
BA_ "GenSigSNA" SG_ 1159 TCU_tc10Version "0";
BA_ "Confidence" SG_ 1157 TCU_alertID 1;
BA_ "Confidence" SG_ 1157 TCU_alertState 1;
BA_ "Confidence" SG_ 1157 TCU_w012_DataRAT 1;
BA_ "Confidence" SG_ 1157 TCU_w012_RSRP 1;
BA_ "Confidence" SG_ 1157 TCU_w012_RSRQ 1;
BA_ "Confidence" SG_ 1157 TCU_w012_AvgQueueUsage 1;
BA_ "Confidence" SG_ 1157 TCU_w012_NSAAvailable 1;
BA_ "Confidence" SG_ 1157 TCU_w013_DataRAT 1;
BA_ "Confidence" SG_ 1157 TCU_w013_RSRP 1;
BA_ "Confidence" SG_ 1157 TCU_w013_RSRQ 1;
BA_ "Confidence" SG_ 1157 TCU_w013_AvgQueueUsage 1;
BA_ "Confidence" SG_ 1157 TCU_w013_NSAAvailable 1;
BA_ "Confidence" SG_ 1155 TCU_logMux 1;
BA_ "Confidence" SG_ 1155 TCU_cpuTemp 0;
BA_ "Confidence" SG_ 1155 TCU_cpuUsage 0;
BA_ "Confidence" SG_ 1155 TCU_mdmCoreTemperature 0;
BA_ "Confidence" SG_ 1155 TCU_availableMemory 0;
BA_ "Confidence" SG_ 1155 TCU_pwm 0;
BA_ "Confidence" SG_ 1155 TCU_pwmcap 0;
BA_ "Confidence" SG_ 1155 TCU_totalResumes 0;
BA_ "Confidence" SG_ 1155 TCU_mdmUplinkQueueSize 0;
BA_ "Confidence" SG_ 1155 TCU_mdmRSRP 0;
BA_ "Confidence" SG_ 1155 TCU_mdmSINR 0;
BA_ "Confidence" SG_ 1155 TCU_mdmUplinkAllowedRate 0;
BA_ "Confidence" SG_ 1155 TCU_mdmUplinkAvgRate 0;
BA_ "Confidence" SG_ 1155 TCU_mdmServiceState 0;
BA_ "Confidence" SG_ 1155 TCU_mdmIMSStatus 0;
BA_ "Confidence" SG_ 1155 TCU_mdmSIMStatus 0;
BA_ "Confidence" SG_ 1155 TCU_mdmBusyActive 0;
BA_ "GenSigSNA" SG_ 1155 TCU_mdmBusyActive "4294967295";
BA_ "Confidence" SG_ 1155 TCU_modemUptime 0;
BA_ "Confidence" SG_ 1155 TCU_mdmDataRat 0;
BA_ "Confidence" SG_ 1155 TCU_mdmDataCallStatus 0;
BA_ "Confidence" SG_ 1155 TCU_mdmNSAAvailable 0;
BA_ "Confidence" SG_ 1155 TCU_mdmPCIID 0;
BA_ "Confidence" SG_ 1155 TCU_mdmMnc 0;
BA_ "Confidence" SG_ 1155 TCU_mdmMcc 0;
BA_ "Confidence" SG_ 1155 TCU_mdmTxKiloBytes 0;
BA_ "Confidence" SG_ 1155 TCU_mdmDataCallTermReason 0;
BA_ "Confidence" SG_ 1155 TCU_mdmDataCallTermCode 0;
BA_ "Confidence" SG_ 1155 TCU_cellularSMState 0;
BA_ "Confidence" SG_ 1155 TCU_tcuSMState 0;
BA_ "Confidence" SG_ 1155 TCU_checkInternetFailCount 0;
BA_ "Confidence" SG_ 1155 TCU_mdmBand 0;
BA_ "Confidence" SG_ 1155 TCU_wakeSource 0;
BA_ "Confidence" SG_ 1298 TRCM_alertID 1;
BA_ "Confidence" SG_ 1298 TRCM_alertState 1;
BA_ "Confidence" SG_ 1298 TRCM_a017_tempData 1;
BA_ "Confidence" SG_ 1298 TRCM_a018_tempData 1;
BA_ "Confidence" SG_ 1298 TRCM_a035_eventArmStatus 1;
BA_ "Confidence" SG_ 1298 TRCM_a035_eventFrontLeftSeatbelt 1;
BA_ "Confidence" SG_ 1298 TRCM_a035_eventFrontRightSeatbel 1;
BA_ "SystemSignalLongSymbol" SG_ 1298 TRCM_a035_eventFrontRightSeatbel "TRCM_a035_eventFrontRightSeatbelt";
BA_ "Confidence" SG_ 1298 TRCM_a035_eventVehicleSpeed 1;
BA_ "Confidence" SG_ 1298 TRCM_a035_eventDriverBrakeApply 1;
BA_ "GenSigSNA" SG_ 1298 TRCM_a035_eventDriverBrakeApply "3";
BA_ "Confidence" SG_ 1298 TRCM_a035_eventAccelPedalPos 1;
BA_ "GenSigSNA" SG_ 1298 TRCM_a035_eventAccelPedalPos "255";
BA_ "Confidence" SG_ 1298 TRCM_a036_collisionType 1;
BA_ "GenSigSNA" SG_ 1298 TRCM_a036_collisionType "8";
BA_ "Confidence" SG_ 1298 TRCM_a036_collisionSeverity 1;
BA_ "Confidence" SG_ 1298 TRCM_a036_eventArmStatus 1;
BA_ "Confidence" SG_ 1298 TRCM_a036_eventFrontLeftSeatbelt 1;
BA_ "Confidence" SG_ 1298 TRCM_a036_eventFrontRightSeatbel 1;
BA_ "SystemSignalLongSymbol" SG_ 1298 TRCM_a036_eventFrontRightSeatbel "TRCM_a036_eventFrontRightSeatbelt";
BA_ "Confidence" SG_ 1298 TRCM_a036_eventVehicleSpeed 1;
BA_ "Confidence" SG_ 1298 TRCM_a036_eventDriverBrakeApply 1;
BA_ "GenSigSNA" SG_ 1298 TRCM_a036_eventDriverBrakeApply "3";
BA_ "Confidence" SG_ 1298 TRCM_a036_eventAccelPedalPos 1;
BA_ "GenSigSNA" SG_ 1298 TRCM_a036_eventAccelPedalPos "255";
BA_ "Confidence" SG_ 1298 TRCM_a037_eventArmStatus 1;
BA_ "Confidence" SG_ 1298 TRCM_a037_eventFrontLeftSeatbelt 1;
BA_ "Confidence" SG_ 1298 TRCM_a037_eventFrontRightSeatbel 1;
BA_ "SystemSignalLongSymbol" SG_ 1298 TRCM_a037_eventFrontRightSeatbel "TRCM_a037_eventFrontRightSeatbelt";
BA_ "Confidence" SG_ 1298 TRCM_a037_eventVehicleSpeed 1;
BA_ "Confidence" SG_ 1298 TRCM_a037_eventDriverBrakeApply 1;
BA_ "GenSigSNA" SG_ 1298 TRCM_a037_eventDriverBrakeApply "3";
BA_ "Confidence" SG_ 1298 TRCM_a037_eventAccelPedalPos 1;
BA_ "GenSigSNA" SG_ 1298 TRCM_a037_eventAccelPedalPos "255";
BA_ "Confidence" SG_ 1298 TRCM_a059_voltageDrop 1;
BA_ "Confidence" SG_ 1298 TRCM_a059_resistanceEstimate 1;
BA_ "Confidence" SG_ 1298 TRCM_a059_current 1;
BA_ "Confidence" SG_ 1298 TRCM_a063_ADCVoltage 1;
BA_ "Confidence" SG_ 1298 TRCM_a065_vsafingFetVoltage 1;
BA_ "Confidence" SG_ 1298 TRCM_a066_busVoltage 1;
BA_ "Confidence" SG_ 1298 TRCM_a081_eventArmStatus 1;
BA_ "Confidence" SG_ 1298 TRCM_a081_eventFrontLeftSeatbelt 1;
BA_ "Confidence" SG_ 1298 TRCM_a081_eventFrontRightSeatbel 1;
BA_ "SystemSignalLongSymbol" SG_ 1298 TRCM_a081_eventFrontRightSeatbel "TRCM_a081_eventFrontRightSeatbelt";
BA_ "Confidence" SG_ 1298 TRCM_a081_eventVehicleSpeed 1;
BA_ "Confidence" SG_ 1298 TRCM_a081_eventDriverBrakeApply 1;
BA_ "GenSigSNA" SG_ 1298 TRCM_a081_eventDriverBrakeApply "3";
BA_ "Confidence" SG_ 1298 TRCM_a081_eventAccelPedalPos 1;
BA_ "GenSigSNA" SG_ 1298 TRCM_a081_eventAccelPedalPos "255";
BA_ "SystemSignalLongSymbol" SG_ 1298 TRCM_a101_LIPC_externalWatchdogH "TRCM_a101_LIPC_externalWatchdogHeartBeat";
BA_ "SystemSignalLongSymbol" SG_ 1298 TRCM_a115_UI_corianderVehicleCon "TRCM_a115_UI_corianderVehicleControl";
BA_ "SystemSignalLongSymbol" SG_ 1298 TRCM_a117_VEH_intrusionSensorSta "TRCM_a117_VEH_intrusionSensorStatus";
BA_ "SystemSignalLongSymbol" SG_ 1298 TRCM_a117_PARTY_lightingSecondar "TRCM_a117_PARTY_lightingSecondary";
BA_ "SystemSignalLongSymbol" SG_ 1298 TRCM_a118_PARTY_outputPowerStatu "TRCM_a118_PARTY_outputPowerStatus";
BA_ "SystemSignalLongSymbol" SG_ 1298 TRCM_a118_VEH_interNodeResistanc "TRCM_a118_VEH_interNodeResistance";
BA_ "SystemSignalLongSymbol" SG_ 1298 TRCM_a118_PARTY_AP_vehicleState1 "TRCM_a118_PARTY_AP_vehicleState1HzMuxed";
BA_ "SystemSignalLongSymbol" SG_ 1298 TRCM_a118_BDY_AP_vehicleState1Hz "TRCM_a118_BDY_AP_vehicleState1HzMuxed";
BA_ "SystemSignalLongSymbol" SG_ 1298 TRCM_a118_PARTY_VCFRONT_cameraCl "TRCM_a118_PARTY_VCFRONT_cameraCleaningStatus";
BA_ "SystemSignalLongSymbol" SG_ 1298 TRCM_a120_VEH_aggregatedAxleSpee "TRCM_a120_VEH_aggregatedAxleSpeed";
BA_ "SystemSignalLongSymbol" SG_ 1298 TRCM_a120_PARTY_aggregatedAxleSp "TRCM_a120_PARTY_aggregatedAxleSpeed";
BA_ "SystemSignalLongSymbol" SG_ 1298 TRCM_a120_PARTY_stalklessInterfa "TRCM_a120_PARTY_stalklessInterfaces";
BA_ "Confidence" SG_ 1298 TRCM_a332_currentMonitorTimer 1;
BA_ "Confidence" SG_ 1298 TRCM_a333_currentMonitorTimer 1;
BA_ "Confidence" SG_ 1298 TRCM_a334_currentMonitorTimer 1;
BA_ "Confidence" SG_ 1298 TRCM_a335_currentMonitorTimer 1;
BA_ "Confidence" SG_ 1298 TRCM_a336_currentMonitorTimer 1;
BA_ "Confidence" SG_ 1298 TRCM_a337_currentMonitorTimer 1;
BA_ "Confidence" SG_ 1298 TRCM_a338_currentMonitorTimer 1;
BA_ "Confidence" SG_ 1298 TRCM_a340_currentMonitorTimer 1;
BA_ "Confidence" SG_ 1298 TRCM_a341_currentMonitorTimer 1;
BA_ "Confidence" SG_ 1298 TRCM_a342_currentMonitorTimer 1;
BA_ "Confidence" SG_ 1298 TRCM_a343_currentMonitorTimer 1;
BA_ "Confidence" SG_ 1298 TRCM_a344_currentMonitorTimer 1;
BA_ "Confidence" SG_ 1298 TRCM_a345_currentMonitorTimer 1;
BA_ "Confidence" SG_ 1298 TRCM_a346_currentMonitorTimer 1;
BA_ "Confidence" SG_ 1298 TRCM_a347_currentMonitorTimer 1;
BA_ "Confidence" SG_ 1298 TRCM_a348_currentMonitorTimer 1;
BA_ "Confidence" SG_ 1298 TRCM_a349_currentMonitorTimer 1;
BA_ "Confidence" SG_ 1298 TRCM_a350_currentMonitorTimer 1;
BA_ "Confidence" SG_ 1298 TRCM_a351_currentMonitorTimer 1;
BA_ "Confidence" SG_ 1298 TRCM_a352_currentMonitorTimer 1;
BA_ "Confidence" SG_ 1298 TRCM_a353_currentMonitorTimer 1;
BA_ "Confidence" SG_ 1298 TRCM_a354_currentMonitorTimer 1;
BA_ "Confidence" SG_ 1298 TRCM_a355_currentMonitorTimer 1;
BA_ "Confidence" SG_ 1298 TRCM_a400_resistance 1;
BA_ "GenSigSNA" SG_ 1298 TRCM_a400_resistance "255";
BA_ "Confidence" SG_ 1298 TRCM_a401_resistance 1;
BA_ "GenSigSNA" SG_ 1298 TRCM_a401_resistance "255";
BA_ "Confidence" SG_ 1298 TRCM_a402_resistance 1;
BA_ "GenSigSNA" SG_ 1298 TRCM_a402_resistance "255";
BA_ "Confidence" SG_ 1298 TRCM_a403_resistance 1;
BA_ "GenSigSNA" SG_ 1298 TRCM_a403_resistance "255";
BA_ "Confidence" SG_ 1298 TRCM_a404_resistance 1;
BA_ "GenSigSNA" SG_ 1298 TRCM_a404_resistance "255";
BA_ "Confidence" SG_ 1298 TRCM_a405_resistance 1;
BA_ "GenSigSNA" SG_ 1298 TRCM_a405_resistance "255";
BA_ "Confidence" SG_ 1298 TRCM_a406_resistance 1;
BA_ "GenSigSNA" SG_ 1298 TRCM_a406_resistance "255";
BA_ "Confidence" SG_ 1298 TRCM_a408_resistance 1;
BA_ "GenSigSNA" SG_ 1298 TRCM_a408_resistance "255";
BA_ "Confidence" SG_ 1298 TRCM_a409_resistance 1;
BA_ "GenSigSNA" SG_ 1298 TRCM_a409_resistance "255";
BA_ "Confidence" SG_ 1298 TRCM_a410_resistance 1;
BA_ "GenSigSNA" SG_ 1298 TRCM_a410_resistance "255";
BA_ "Confidence" SG_ 1298 TRCM_a411_resistance 1;
BA_ "GenSigSNA" SG_ 1298 TRCM_a411_resistance "255";
BA_ "Confidence" SG_ 1298 TRCM_a412_resistance 1;
BA_ "GenSigSNA" SG_ 1298 TRCM_a412_resistance "255";
BA_ "Confidence" SG_ 1298 TRCM_a413_resistance 1;
BA_ "GenSigSNA" SG_ 1298 TRCM_a413_resistance "255";
BA_ "Confidence" SG_ 1298 TRCM_a414_resistance 1;
BA_ "GenSigSNA" SG_ 1298 TRCM_a414_resistance "255";
BA_ "Confidence" SG_ 1298 TRCM_a415_resistance 1;
BA_ "GenSigSNA" SG_ 1298 TRCM_a415_resistance "255";
BA_ "Confidence" SG_ 1298 TRCM_a416_resistance 1;
BA_ "GenSigSNA" SG_ 1298 TRCM_a416_resistance "255";
BA_ "Confidence" SG_ 1298 TRCM_a417_resistance 1;
BA_ "GenSigSNA" SG_ 1298 TRCM_a417_resistance "255";
BA_ "Confidence" SG_ 1298 TRCM_a418_resistance 1;
BA_ "GenSigSNA" SG_ 1298 TRCM_a418_resistance "255";
BA_ "Confidence" SG_ 1298 TRCM_a419_resistance 1;
BA_ "GenSigSNA" SG_ 1298 TRCM_a419_resistance "255";
BA_ "Confidence" SG_ 1298 TRCM_a420_resistance 1;
BA_ "GenSigSNA" SG_ 1298 TRCM_a420_resistance "255";
BA_ "Confidence" SG_ 1298 TRCM_a421_resistance 1;
BA_ "GenSigSNA" SG_ 1298 TRCM_a421_resistance "255";
BA_ "Confidence" SG_ 1298 TRCM_a422_resistance 1;
BA_ "GenSigSNA" SG_ 1298 TRCM_a422_resistance "255";
BA_ "Confidence" SG_ 1298 TRCM_a423_resistance 1;
BA_ "GenSigSNA" SG_ 1298 TRCM_a423_resistance "255";
VAL_ 1297 RCM_a117_eventDriveOrientation 1 "RIGHT_HAND_DRIVE" 0 "LEFT_HAND_DRIVE" ;
VAL_ 1297 RCM_a117_eventIDFsignal 1 "ACTIVE" 0 "NOT_ACTIVE" ;
VAL_ 1297 RCM_a117_eventFrontLeftSeatbelt 1 "LATCHED" 0 "UNLATCHED" ;
VAL_ 1297 RCM_a117_eventFrontRightSeatbelt 1 "LATCHED" 0 "UNLATCHED" ;
VAL_ 1297 RCM_a117_eventDriverBrakeApply 3 "Faulty_SNA" 2 "Driver_applying_brakes" 1 "Not_Applied" 0 "NotInit_orOff" ;
VAL_ 1297 RCM_a117_eventAccelPedalPos 255 "SNA" ;
VAL_ 1297 RCM_a118_eventArmStatus 1 "ARMED" 0 "UNARMED" ;
VAL_ 1297 RCM_a118_eventFactoryMode 1 "ENABLED" 0 "DISABLED" ;
VAL_ 1297 RCM_a118_eventDiagEnabled 1 "ENABLED" 0 "DISABLED" ;
VAL_ 1297 RCM_a118_eventDriveOrientation 1 "RIGHT_HAND_DRIVE" 0 "LEFT_HAND_DRIVE" ;
VAL_ 1297 RCM_a118_eventIDFsignal 1 "ACTIVE" 0 "NOT_ACTIVE" ;
VAL_ 1297 RCM_a118_eventFrontLeftSeatbelt 1 "LATCHED" 0 "UNLATCHED" ;
VAL_ 1297 RCM_a118_eventFrontRightSeatbelt 1 "LATCHED" 0 "UNLATCHED" ;
VAL_ 1297 RCM_a118_eventDriverBrakeApply 3 "Faulty_SNA" 2 "Driver_applying_brakes" 1 "Not_Applied" 0 "NotInit_orOff" ;
VAL_ 1297 RCM_a118_eventAccelPedalPos 255 "SNA" ;
VAL_ 881 RCM_matrixIndex 1 "AlertMatrix1" 0 "AlertMatrix0" ;
VAL_ 1415 TCU2_tc10Version 2 "TCU_tc10Version_FINAL_1_0" 1 "TCU_tc10Version_DRAFT" 0 "SNA" ;
VAL_ 1413 TCU2_alertID 16 "w016_IMEIMismatch" 15 "w015_NPNSubscriptionActive" 14 "w014_HostapdCrash" 13 "w013_UplinkQueueFull" 12 "w012_UplinkDegraded" 11 "w011_CellDumpDetected" 10 "w010_WifiDumpDetected" 9 "w009_WifiFirmwareCrash" 8 "w008_KernelPanic" 7 "w007_ModemUnreachable" 6 "w006_MpssUnavailable" 5 "w005_SIMSlotError" 4 "w004_MSDTransmissionFailed" 3 "w003_ECallFailed" 2 "w002_CellRegRejected" 1 "w001_IMSRegistrationFailed" 0 "ALERT_DO_NOT_USE_ZERO" ;
VAL_ 1413 TCU2_alertState 1 "SET" 0 "CLEARED" ;
VAL_ 1413 TCU2_w012_DataRAT 6 "NR5G_UNKNOWN" 5 "NR5G_SA" 4 "NR5G_NSA" 3 "LTE" 2 "WCDMA" 1 "GSM" 0 "UNKNOWN" ;
VAL_ 1413 TCU2_w012_NSAAvailable 2 "NOT_AVAILABLE" 1 "AVAILABLE" 0 "UNKNOWN" ;
VAL_ 1413 TCU2_w013_DataRAT 6 "NR5G_UNKNOWN" 5 "NR5G_SA" 4 "NR5G_NSA" 3 "LTE" 2 "WCDMA" 1 "GSM" 0 "UNKNOWN" ;
VAL_ 1413 TCU2_w013_NSAAvailable 2 "NOT_AVAILABLE" 1 "AVAILABLE" 0 "UNKNOWN" ;
VAL_ 1412 TCU2_logMux 30 "wakeSource" 29 "mdmBand" 28 "checkInternetFailCount" 27 "tcuSMState" 26 "cellularSMState" 25 "mdmDataCallTermCode" 24 "mdmDataCallTermReason" 23 "mdmTxKiloBytes" 22 "mdmMcc" 21 "mdmMnc" 20 "mdmPCIID" 19 "mdmNSAAvailable" 18 "mdmDataCallStatus" 17 "mdmDataRat" 16 "modemUptime" 15 "mdmBusyActive" 14 "mdmSIMStatus" 13 "mdmIMSStatus" 12 "mdmServiceState" 11 "mdmUplinkAvgRate" 10 "mdmUplinkAllowedRate" 9 "mdmSINR" 8 "mdmRSRP" 7 "mdmUplinkQueueSize" 6 "totalResumes" 5 "pwmcap" 4 "pwm" 3 "availableMemory" 2 "mdmCoreTemperature" 1 "cpuUsage" 0 "cpuTemp" ;
VAL_ 1412 TCU2_mdmBusyActive 4294967295 "SNA" ;
VAL_ 1412 TCU2_mdmDataRat 6 "RAT_NR5G_UNKNOWN" 5 "RAT_NR5G_SA" 4 "RAT_NR5G_NSA" 3 "RAT_LTE" 2 "RAT_WCDMA" 1 "RAT_GSM" 0 "RAT_UNKNOWN" ;
VAL_ 1412 TCU2_mdmDataCallStatus 4 "DISCONNECTED" 3 "DISCONNECTING" 2 "CONNECTED" 1 "CONNECTING" 0 "UNKNOWN" ;
VAL_ 1412 TCU2_mdmNSAAvailable 2 "NSA_NOT_AVAILABLE" 1 "NSA_AVAILABLE" 0 "NSA_UNKNOWN" ;
VAL_ 1412 TCU2_cellularSMState 7 "RECOVERING" 6 "LINK_CONNECTED" 5 "CHECKING_INTERNET" 4 "DATA_CONNECTED" 3 "IN_SERVICE" 2 "OUT_OF_SERVICE" 1 "WAITING_COMPONENT" 0 "UNKNOWN" ;
VAL_ 1412 TCU2_tcuSMState 7 "UPDATING" 6 "RESUMING" 5 "SUSPENDED" 4 "PREPARING_SLEEP" 3 "POWER_CYCLING" 2 "IN_OPERATION" 1 "SEARCHING_COMPONENT" 0 "UNKNOWN" ;
VAL_ 1412 TCU2_wakeSource 3 "ETHERNET" 2 "WOIP" 1 "SMS" 0 "NONE" ;
VAL_ 1159 TCU_tc10Version 2 "TCU_tc10Version_FINAL_1_0" 1 "TCU_tc10Version_DRAFT" 0 "SNA" ;
VAL_ 1157 TCU_alertID 16 "w016_IMEIMismatch" 15 "w015_NPNSubscriptionActive" 14 "w014_HostapdCrash" 13 "w013_UplinkQueueFull" 12 "w012_UplinkDegraded" 11 "w011_CellDumpDetected" 10 "w010_WifiDumpDetected" 9 "w009_WifiFirmwareCrash" 8 "w008_KernelPanic" 7 "w007_ModemUnreachable" 6 "w006_MpssUnavailable" 5 "w005_SIMSlotError" 4 "w004_MSDTransmissionFailed" 3 "w003_ECallFailed" 2 "w002_CellRegRejected" 1 "w001_IMSRegistrationFailed" 0 "ALERT_DO_NOT_USE_ZERO" ;
VAL_ 1157 TCU_alertState 1 "SET" 0 "CLEARED" ;
VAL_ 1157 TCU_w012_DataRAT 6 "NR5G_UNKNOWN" 5 "NR5G_SA" 4 "NR5G_NSA" 3 "LTE" 2 "WCDMA" 1 "GSM" 0 "UNKNOWN" ;
VAL_ 1157 TCU_w012_NSAAvailable 2 "NOT_AVAILABLE" 1 "AVAILABLE" 0 "UNKNOWN" ;
VAL_ 1157 TCU_w013_DataRAT 6 "NR5G_UNKNOWN" 5 "NR5G_SA" 4 "NR5G_NSA" 3 "LTE" 2 "WCDMA" 1 "GSM" 0 "UNKNOWN" ;
VAL_ 1157 TCU_w013_NSAAvailable 2 "NOT_AVAILABLE" 1 "AVAILABLE" 0 "UNKNOWN" ;
VAL_ 1155 TCU_logMux 30 "wakeSource" 29 "mdmBand" 28 "checkInternetFailCount" 27 "tcuSMState" 26 "cellularSMState" 25 "mdmDataCallTermCode" 24 "mdmDataCallTermReason" 23 "mdmTxKiloBytes" 22 "mdmMcc" 21 "mdmMnc" 20 "mdmPCIID" 19 "mdmNSAAvailable" 18 "mdmDataCallStatus" 17 "mdmDataRat" 16 "modemUptime" 15 "mdmBusyActive" 14 "mdmSIMStatus" 13 "mdmIMSStatus" 12 "mdmServiceState" 11 "mdmUplinkAvgRate" 10 "mdmUplinkAllowedRate" 9 "mdmSINR" 8 "mdmRSRP" 7 "mdmUplinkQueueSize" 6 "totalResumes" 5 "pwmcap" 4 "pwm" 3 "availableMemory" 2 "mdmCoreTemperature" 1 "cpuUsage" 0 "cpuTemp" ;
VAL_ 1155 TCU_mdmBusyActive 4294967295 "SNA" ;
VAL_ 1155 TCU_mdmDataRat 6 "RAT_NR5G_UNKNOWN" 5 "RAT_NR5G_SA" 4 "RAT_NR5G_NSA" 3 "RAT_LTE" 2 "RAT_WCDMA" 1 "RAT_GSM" 0 "RAT_UNKNOWN" ;
VAL_ 1155 TCU_mdmDataCallStatus 4 "DISCONNECTED" 3 "DISCONNECTING" 2 "CONNECTED" 1 "CONNECTING" 0 "UNKNOWN" ;
VAL_ 1155 TCU_mdmNSAAvailable 2 "NSA_NOT_AVAILABLE" 1 "NSA_AVAILABLE" 0 "NSA_UNKNOWN" ;
VAL_ 1155 TCU_cellularSMState 7 "RECOVERING" 6 "LINK_CONNECTED" 5 "CHECKING_INTERNET" 4 "DATA_CONNECTED" 3 "IN_SERVICE" 2 "OUT_OF_SERVICE" 1 "WAITING_COMPONENT" 0 "UNKNOWN" ;
VAL_ 1155 TCU_tcuSMState 7 "UPDATING" 6 "RESUMING" 5 "SUSPENDED" 4 "PREPARING_SLEEP" 3 "POWER_CYCLING" 2 "IN_OPERATION" 1 "SEARCHING_COMPONENT" 0 "UNKNOWN" ;
VAL_ 1155 TCU_wakeSource 3 "ETHERNET" 2 "WOIP" 1 "SMS" 0 "NONE" ;
VAL_ 1298 TRCM_alertID 646 "a646_glacierDeviceFaulted" 645 "a645_glacierDeviceReset" 644 "a644_glacierNormalOperationFailure" 643 "a643_glacierOffsetVerificationFailure" 642 "a642_glacierFinalStatusFailure" 641 "a641_glacierOscillatorVerificationFailure" 640 "a640_glacierAnalogSelfTestFailure" 639 "a639_glacierSelfTestFFailure" 638 "a638_glacierSelfTestEFailure" 637 "a637_glacierFixedPatternSelfTestFailure" 636 "a636_glacierRegisterPatternWriteFailure" 635 "a635_glacierTraceabilityReadoutB0B0Failure" 634 "a634_glacierTraceabilityReadoutA0A0Failure" 633 "a633_glacierInitialStatusFailure" 632 "a632_loop31AsicStartupDiagnosticFailure" 631 "a631_loop30AsicStartupDiagnosticFailure" 630 "a630_loop29AsicStartupDiagnosticFailure" 629 "a629_loop28AsicStartupDiagnosticFailure" 628 "a628_loop27AsicStartupDiagnosticFailure" 627 "a627_loop26AsicStartupDiagnosticFailure" 626 "a626_loop25AsicStartupDiagnosticFailure" 625 "a625_loop24AsicStartupDiagnosticFailure" 624 "a624_loop23AsicStartupDiagnosticFailure" 623 "a623_loop22AsicStartupDiagnosticFailure" 622 "a622_loop21AsicStartupDiagnosticFailure" 621 "a621_loop20AsicStartupDiagnosticFailure" 620 "a620_loop19AsicStartupDiagnosticFailure" 619 "a619_loop18AsicStartupDiagnosticFailure" 618 "a618_loop17AsicStartupDiagnosticFailure" 617 "a617_loop16AsicStartupDiagnosticFailure" 616 "a616_loop15AsicStartupDiagnosticFailure" 615 "a615_loop14AsicStartupDiagnosticFailure" 614 "a614_loop13AsicStartupDiagnosticFailure" 613 "a613_loop12AsicStartupDiagnosticFailure" 612 "a612_loop11AsicStartupDiagnosticFailure" 611 "a611_loop10AsicStartupDiagnosticFailure" 610 "a610_loop9AsicStartupDiagnosticFailure" 609 "a609_loop8AsicStartupDiagnosticFailure" 608 "a608_loop7AsicStartupDiagnosticFailure" 607 "a607_loop6AsicStartupDiagnosticFailure" 606 "a606_loop5AsicStartupDiagnosticFailure" 605 "a605_loop4AsicStartupDiagnosticFailure" 604 "a604_loop3AsicStartupDiagnosticFailure" 603 "a603_loop2AsicStartupDiagnosticFailure" 602 "a602_loop1AsicStartupDiagnosticFailure" 601 "a601_loop0AsicStartupDiagnosticFailure" 600 "a600_airbagAsicStartupFailure" 599 "a599_verticalAccelOffsetNegLimit" 598 "a598_verticalAccelOffsetPosLimit" 597 "a597_lateralAccelOffsetNegLimit" 596 "a596_lateralAccelOffsetPosLimit" 595 "a595_longitudinalAccelOffsetNegLimit" 594 "a594_longitudinalAccelOffsetPosLimit" 593 "a593_rollRateOffsetNegLimit" 592 "a592_rollRateOffsetPosLimit" 591 "a591_pitchRateOffsetNegLimit" 590 "a590_pitchRateOffsetPosLimit" 589 "a589_yawRateOffsetNegLimit" 588 "a588_yawRateOffsetPosLimit" 582 "a582_AlgoWake_RCM_AWAKE" 581 "a581_AlgoWake_RCM_ENABLED_ROLL" 580 "a580_AlgoWake_RCM_ENABLED_Y" 579 "a579_AlgoWake_RCM_ENABLED_X" 578 "a578_AlgoWake_IMPACT_FINISH_ROLL" 577 "a577_AlgoWake_IMPACT_FINISH_Y" 576 "a576_AlgoWake_IMPACT_FINISH_X" 570 "a570_AlgoWake_PAS_WAKE_RIGHT" 569 "a569_AlgoWake_PAS_WAKE_LEFT" 568 "a568_AlgoWake_RCM_AWAKE_Y" 567 "a567_AlgoWake_RCM_AWAKE_X" 566 "a566_AlgoWake_RCM_AWAKE_ROLL" 565 "a565_AlgoWake_RCM_AWAKE_RIGHT" 564 "a564_AlgoWake_RCM_AWAKE_LEFT" 563 "a563_AlgoWake_RCM_AWAKE_REAR" 562 "a562_AlgoWake_RCM_AWAKE_FRONT" 561 "a561_AlgoWake_RCM_WAKE_ROLL_RIGHT" 560 "a560_AlgoWake_RCM_WAKE_ROLL_LEFT" 558 "a558_AlgoWake_PAS_RH_PLAUSI_REAR" 557 "a557_AlgoWake_PAS_RH_PLAUSI_FRONT" 555 "a555_AlgoWake_PAS_LH_PLAUSI_REAR" 554 "a554_AlgoWake_PAS_LH_PLAUSI_FRONT" 553 "a553_AlgoWake_RCM_WAKE_RIGHT" 552 "a552_AlgoWake_RCM_WAKE_LEFT" 551 "a551_AlgoWake_RCM_WAKE_REAR" 550 "a550_AlgoWake_RCM_WAKE_FRONT" 546 "a546_sensorValuesFaultedBySmart" 545 "a545_erCapBelowAutarkyThreshold" 544 "a544_erCapDiagnosticsFailed" 455 "a455_seatbeltShoulderPretensionerRearRightConfigError" 454 "a454_seatbeltShoulderPretensionerRearLeftConfigError" 453 "a453_hoodLifterRightConfigError" 452 "a452_hoodLifterLeftConfigError" 451 "a451_outboardSeatAirbagRightConfigError" 450 "a450_outboardSeatAirbagLeftConfigError" 449 "a449_seatbeltLapPretensionerFrontRightConfigError" 448 "a448_seatbeltLapPretensionerFrontLeftConfigError" 447 "a447_seatbeltShoulderPretensionerFrontRightConfigError" 446 "a446_seatbeltShoulderPretensionerFrontLeftConfigError" 445 "a445_seatbeltLoadLimiterFrontRightConfigError" 444 "a444_seatbeltLoadLimiterFrontLeftConfigError" 443 "a443_curtainAirbagRightConfigError" 442 "a442_curtainAirbagLeftConfigError" 441 "a441_kneeAirbagRightConfigError" 440 "a440_kneeAirbagLeftConfigError" 438 "a438_inboardSeatAirbagConfigError" 437 "a437_passengerAirbagActiveVentConfigError" 436 "a436_passengerAirbagStage2ConfigError" 435 "a435_driverAirbagActiveVentConfigError" 434 "a434_driverAirbagStage2ConfigError" 433 "a433_passengerAirbagStage1ConfigError" 432 "a432_driverAirbagStage1ConfigError" 423 "a423_seatbeltShoulderPretensionerRearRightIssue" 422 "a422_seatbeltShoulderPretensionerRearLeftIssue" 421 "a421_hoodLifterRightIssue" 420 "a420_hoodLifterLeftIssue" 419 "a419_outboardSeatAirbagRightIssue" 418 "a418_outboardSeatAirbagLeftIssue" 417 "a417_seatbeltLapPretensionerFrontRightIssue" 416 "a416_seatbeltLapPretensionerFrontLeftIssue" 415 "a415_seatbeltShoulderPretensionerFrontRightIssue" 414 "a414_seatbeltShoulderPretensionerFrontLeftIssue" 413 "a413_seatbeltLoadLimiterFrontRightIssue" 412 "a412_seatbeltLoadLimiterFrontLeftIssue" 411 "a411_curtainAirbagRightIssue" 410 "a410_curtainAirbagLeftIssue" 409 "a409_kneeAirbagRightIssue" 408 "a408_kneeAirbagLeftIssue" 406 "a406_inboardSeatAirbagIssue" 405 "a405_passengerAirbagActiveVentIssue" 404 "a404_passengerAirbagStage2Issue" 403 "a403_driverAirbagActiveVentIssue" 402 "a402_driverAirbagStage2Issue" 401 "a401_passengerAirbagStage1Issue" 400 "a400_driverAirbagStage1Issue" 399 "a399_imuCalibrationComplete" 398 "a398_asicNvmReprogrammed" 397 "a397_safingMonitorError" 396 "a396_spiCommunicationProgramError" 395 "a395_imuUncalibrated" 394 "a394_gspiGlobalStatusWordError" 393 "a393_depAdcConvertRatioError" 392 "a392_extAsic2ClockOrOperatingStateError" 391 "a391_extAsic1ClockOrOperatingStateError" 390 "a390_systemAsicClockOrOperatingStateError" 389 "a389_asicPwrStatusError" 388 "a388_cpuLoadHigh" 387 "a387_primaryAsicResetSource" 385 "a385_safingEngine21NoValidData" 384 "a384_safingEngine20NoValidData" 383 "a383_safingEngine19NoValidData" 382 "a382_safingEngine18NoValidData" 381 "a381_safingEngine17NoValidData" 380 "a380_safingEngine16NoValidData" 379 "a379_safingEngine15NoValidData" 378 "a378_safingEngine14NoValidData" 377 "a377_safingEngine13NoValidData" 376 "a376_safingEngine12NoValidData" 375 "a375_safingEngine11NoValidData" 374 "a374_safingEngine10NoValidData" 373 "a373_safingEngine9NoValidData" 372 "a372_safingEngine8NoValidData" 371 "a371_safingEngine7NoValidData" 370 "a370_safingEngine6NoValidData" 369 "a369_safingEngine5NoValidData" 368 "a368_safingEngine4NoValidData" 367 "a367_safingEngine3NoValidData" 366 "a366_safingEngine2NoValidData" 365 "a365_safingEngine1NoValidData" 364 "a364_safingEngine0NoValidData" 355 "a355_seatbeltShoulderPretensionerRearRightDeployed" 354 "a354_seatbeltShoulderPretensionerRearLeftDeployed" 353 "a353_hoodLifterRightDeployed" 352 "a352_hoodLifterLeftDeployed" 351 "a351_outboardSeatAirbagRightDeployed" 350 "a350_outboardSeatAirbagLeftDeployed" 349 "a349_seatbeltLapPretensionerFrontRightDeployed" 348 "a348_seatbeltLapPretensionerFrontLeftDeployed" 347 "a347_seatbeltShoulderPretensionerFrontRightDeployed" 346 "a346_seatbeltShoulderPretensionerFrontLeftDeployed" 345 "a345_seatbeltLoadLimiterFrontRightDeployed" 344 "a344_seatbeltLoadLimiterFrontLeftDeployed" 343 "a343_curtainAirbagRightDeployed" 342 "a342_curtainAirbagLeftDeployed" 341 "a341_kneeAirbagRightDeployed" 340 "a340_kneeAirbagLeftDeployed" 338 "a338_inboardSeatAirbagDeployed" 337 "a337_passengerAirbagActiveVentDeployed" 336 "a336_passengerAirbagStage2Deployed" 335 "a335_driverAirbagActiveVentDeployed" 334 "a334_driverAirbagStage2Deployed" 333 "a333_passengerAirbagStage1Deployed" 332 "a332_driverAirbagStage1Deployed" 323 "a323_seatbeltShoulderPretensionerRearRightSuppressed" 322 "a322_seatbeltShoulderPretensionerRearLeftSuppressed" 321 "a321_hoodLifterRightSuppressed" 320 "a320_hoodLifterLeftSuppressed" 319 "a319_outboardSeatAirbagRightSuppressed" 318 "a318_outboardSeatAirbagLeftSuppressed" 317 "a317_seatbeltLapPretensionerFrontRightSuppressed" 316 "a316_seatbeltLapPretensionerFrontLeftSuppressed" 315 "a315_seatbeltShoulderPretensionerFrontRightSuppressed" 314 "a314_seatbeltShoulderPretensionerFrontLeftSuppressed" 313 "a313_seatbeltLoadLimiterFrontRightSuppressed" 312 "a312_seatbeltLoadLimiterFrontLeftSuppressed" 311 "a311_curtainAirbagRightSuppressed" 310 "a310_curtainAirbagLeftSuppressed" 309 "a309_kneeAirbagRightSuppressed" 308 "a308_kneeAirbagLeftSuppressed" 306 "a306_inboardSeatAirbagSuppressed" 305 "a305_passengerAirbagActiveVentSuppressed" 304 "a304_passengerAirbagStage2Suppressed" 303 "a303_driverAirbagActiveVentSuppressed" 302 "a302_driverAirbagStage2Suppressed" 301 "a301_passengerAirbagStage1Suppressed" 300 "a300_driverAirbagStage1Suppressed" 299 "a299_safingEngine21Armed" 298 "a298_safingEngine20Armed" 297 "a297_safingEngine19Armed" 296 "a296_safingEngine18Armed" 295 "a295_safingEngine17Armed" 294 "a294_safingEngine16Armed" 293 "a293_safingEngine15Armed" 292 "a292_safingEngine14Armed" 291 "a291_safingEngine13Armed" 290 "a290_safingEngine12Armed" 289 "a289_safingEngine11Armed" 288 "a288_safingEngine10Armed" 287 "a287_safingEngine9Armed" 286 "a286_safingEngine8Armed" 285 "a285_safingEngine7Armed" 284 "a284_safingEngine6Armed" 283 "a283_safingEngine5Armed" 282 "a282_safingEngine4Armed" 281 "a281_safingEngine3Armed" 280 "a280_safingEngine2Armed" 279 "a279_safingEngine1Armed" 278 "a278_safingEngine0Armed" 276 "a276_watchdogStatus" 275 "a275_asm5AccStatusError" 274 "a274_asm5ArsStatusZError" 273 "a273_asm5ArsStatusXError" 272 "a272_asm5ComStatusError" 209 "a209_rightCPillarAccelSignalMonitor" 208 "a208_rightCPillarAccelConfigError" 207 "a207_rightCPillarAccelElectricalIssue" 206 "a206_rightCPillarAccelGeneralIssue" 205 "a205_rightCPillarAccelReportedError" 204 "a204_rightBPillarAccelSignalMonitor" 203 "a203_rightBPillarAccelConfigError" 202 "a202_rightBPillarAccelElectricalIssue" 201 "a201_rightBPillarAccelGeneralIssue" 200 "a200_rightBPillarAccelReportedError" 199 "a199_rearRightDoorPressureSignalMonitor" 198 "a198_rearRightDoorPressureConfigError" 197 "a197_rearRightDoorPressureElectricalIssue" 196 "a196_rearRightDoorPressureGeneralIssue" 195 "a195_rearRightDoorPressureReportedError" 194 "a194_rearLeftDoorPressureSignalMonitor" 193 "a193_rearLeftDoorPressureConfigError" 192 "a192_rearLeftDoorPressureElectricalIssue" 191 "a191_rearLeftDoorPressureGeneralIssue" 190 "a190_rearLeftDoorPressureReportedError" 179 "a179_leftCPillarAccelSignalMonitor" 178 "a178_leftCPillarAccelConfigError" 177 "a177_leftCPillarAccelElectricalIssue" 176 "a176_leftCPillarAccelGeneralIssue" 175 "a175_leftCPillarAccelReportedError" 174 "a174_leftBPillarAccelSignalMonitor" 173 "a173_leftBPillarAccelConfigError" 172 "a172_leftBPillarAccelElectricalIssue" 171 "a171_leftBPillarAccelGeneralIssue" 170 "a170_leftBPillarAccelReportedError" 169 "a169_frontRightDoorPressureSignalMonitor" 168 "a168_frontRightDoorPressureConfigError" 167 "a167_frontRightDoorPressureElectricalIssue" 166 "a166_frontRightDoorPressureGeneralIssue" 165 "a165_frontRightDoorPressureReportedError" 164 "a164_frontRightAccelSignalMonitor" 163 "a163_frontRightAccelConfigError" 162 "a162_frontRightAccelElectricalIssue" 161 "a161_frontRightAccelGeneralIssue" 160 "a160_frontRightAccelReportedError" 159 "a159_frontLeftDoorPressureSignalMonitor" 158 "a158_frontLeftDoorPressureConfigError" 157 "a157_frontLeftDoorPressureElectricalIssue" 156 "a156_frontLeftDoorPressureGeneralIssue" 155 "a155_frontLeftDoorPressureReportedError" 154 "a154_frontLeftAccelSignalMonitor" 153 "a153_frontLeftAccelConfigError" 152 "a152_frontLeftAccelElectricalIssue" 151 "a151_frontLeftAccelGeneralIssue" 150 "a150_frontLeftAccelReportedError" 149 "a149_frontCenterAccelSignalMonitor" 148 "a148_frontCenterAccelConfigError" 147 "a147_frontCenterAccelElectricalIssue" 146 "a146_frontCenterAccelGeneralIssue" 145 "a145_frontCenterAccelReportedError" 138 "a138_ext2AsicSnoopTestFailed" 137 "a137_ext1AsicSnoopTestFailed" 136 "a136_asm5DeviceFaulted" 135 "a135_asm5StatusError" 127 "a127_seatTrackPositionRightSignalNotOkay" 126 "a126_seatTrackPositionLeftSignalNotOkay" 125 "a125_occupantClassificationSignalNotOkay" 124 "a124_buckleStatusRearRightSignalNotOkay" 123 "a123_buckleStatusRearLeftSignalNotOkay" 122 "a122_buckleStatusFrontRightSignalNotOkay" 121 "a121_buckleStatusFrontLeftSignalNotOkay" 120 "a120_DI_DRIVE_MIA" 119 "a119_SCCM_MIA" 118 "a118_VCFRONT_MIA" 117 "a117_VCLEFT_MIA" 116 "a116_VCRIGHT_MIA" 115 "a115_VCSEC_MIA" 114 "a114_ESP_MIA" 113 "a113_UI_MIA" 112 "a112_EPBL_MIA" 111 "a111_EPBR_MIA" 110 "a110_GTW_MIA" 109 "a109_RCM_MIA" 108 "a108_DIF_MIA" 107 "a107_BMS_MIA" 106 "a106_PCS_MIA" 105 "a105_TAS_MIA" 104 "a104_DAS_MIA" 103 "a103_CP_MIA" 102 "a102_PTC_MIA" 101 "a101_PM_MIA" 100 "a100_CANbus_MIA" 99 "a099_PARK_MIA" 98 "a098_DIR_MIA" 97 "a097_CMP_MIA" 96 "a096_OCS1P_MIA" 95 "a095_CHG_MIA" 94 "a094_EPAS3P_MIA" 93 "a093_VCSEATP_MIA" 92 "a092_VCSEATD_MIA" 91 "a091_CMPD_MIA" 90 "a090_APS_MIA" 89 "a089_IBST_MIA" 88 "a088_DIRER_MIA" 87 "a087_DIREL_MIA" 86 "a086_VCBATT_MIA" 85 "a085_CCCM_MIA" 84 "a084_TPMS_MIA" 83 "a083_VCLEFT_IPC_MIA" 82 "a082_VCRIGHT_IPC_MIA" 81 "a081_powerLossDetected" 78 "a078_imuSensorSignalMonitor" 77 "a077_ais2120SelfTestYNegativeFailed" 76 "a076_ais2120SelfTestYPositiveFailed" 75 "a075_ais2120SelfTestXNegativeFailed" 74 "a074_ais2120SelfTestXPositiveFailed" 73 "a073_ais2120DeviceFaulted" 72 "a072_ais2120StatusError" 71 "a071_asm3DeviceFaulted" 70 "a070_asm3StatusError" 69 "a069_swAppBoot" 68 "a068_vBusCUnderVoltage" 67 "a067_rightPowerIssue" 66 "a066_leftPowerIssue" 65 "a065_vSafingFetUnderVoltage" 64 "a064_busSleepReqTimeout" 63 "a063_SwitchFault" 62 "a062_XCPWasConnected" 61 "a061_XCPConnected" 60 "a060_engineeringBuild" 59 "a059_inputResistanceHigh" 58 "a058_inputRHighSyncDebug" 57 "a057_HVP_MIA" 51 "a051_systemSelfTestTimeout" 50 "a050_partyLengthError" 49 "a049_nvmDebugInfo" 48 "a048_vinMismatch" 47 "a047_vinNotLearned" 46 "a046_Task1000msError" 45 "a045_Task100msError" 44 "a044_Task10msError" 43 "a043_Task1msError" 42 "a042_HighStackUsage" 41 "a041_HighCPULoad" 40 "a040_task500usOverrunDebug" 39 "a039_ens2Degraded" 38 "a038_ens1Degraded" 37 "a037_nearDeploy" 36 "a036_crashDetected" 35 "a035_hvDisconnectCommanded" 34 "a034_apClipTrigger" 33 "a033_HercLogCreated" 32 "a032_ScrollCreated" 31 "a031_UDSActive" 30 "a030_ECULogUploadRequest" 28 "a028_chassisLengthError" 27 "a027_airbagAsicDeploymentDiagnosticFault" 26 "a026_airbagAsicDiagnosticFault" 25 "a025_CHCANBusFaults" 24 "a024_asm3AccStatusError" 23 "a023_asm3ArsStatusXError" 22 "a022_TaskInitError" 21 "a021_TaskSchedulerError" 20 "a020_asm3ComStatusError" 19 "a019_Task500usError" 18 "a018_asm3TemperatureOutsideOperatingRange" 17 "a017_asm5TemperatureOutsideOperatingRange" 16 "a016_NVMMRecordError" 15 "a015_NVMMError" 14 "a014_asm3TemperatureOutsideSignalRange" 13 "a013_AlertManagerFault" 12 "a012_asm5TemperatureOutsideSignalRange" 11 "a011_edrDataLocked" 10 "a010_partyCounterError" 9 "a009_partyChecksumError" 8 "a008_chassisCounterError" 7 "a007_chassisChecksumError" 6 "a006_CANTX_cyclicError" 5 "a005_CANTXError" 4 "a004_internalFailure" 3 "a003_SWAssertion" 2 "a002_systemDisabled" 1 "a001_airbagsDisabled" 0 "ALERT_DO_NOT_USE_ZERO" ;
VAL_ 1298 TRCM_alertState 1 "SET" 0 "CLEARED" ;
VAL_ 1298 TRCM_a035_eventArmStatus 1 "ARMED" 0 "UNARMED" ;
VAL_ 1298 TRCM_a035_eventFrontLeftSeatbelt 1 "LATCHED" 0 "UNLATCHED" ;
VAL_ 1298 TRCM_a035_eventFrontRightSeatbel 1 "LATCHED" 0 "UNLATCHED" ;
VAL_ 1298 TRCM_a035_eventDriverBrakeApply 3 "Faulty_SNA" 2 "Driver_applying_brakes" 1 "Not_Applied" 0 "NotInit_orOff" ;
VAL_ 1298 TRCM_a035_eventAccelPedalPos 255 "SNA" ;
VAL_ 1298 TRCM_a036_collisionType 8 "SNA" 7 "PEDPRO" 6 "ROLLOVER" 5 "REAR" 3 "RIGHTSIDE" 2 "LEFTSIDE" 1 "FRONT" 0 "NOT_CLASSIFIED" ;
VAL_ 1298 TRCM_a036_collisionSeverity 3 "PEDPRO_EVENT" 2 "SECOND_STAGE" 1 "FIRST_STAGE" 0 "PRETENSIONER" ;
VAL_ 1298 TRCM_a036_eventArmStatus 1 "ARMED" 0 "UNARMED" ;
VAL_ 1298 TRCM_a036_eventFrontLeftSeatbelt 1 "LATCHED" 0 "UNLATCHED" ;
VAL_ 1298 TRCM_a036_eventFrontRightSeatbel 1 "LATCHED" 0 "UNLATCHED" ;
VAL_ 1298 TRCM_a036_eventDriverBrakeApply 3 "Faulty_SNA" 2 "Driver_applying_brakes" 1 "Not_Applied" 0 "NotInit_orOff" ;
VAL_ 1298 TRCM_a036_eventAccelPedalPos 255 "SNA" ;
VAL_ 1298 TRCM_a037_eventArmStatus 1 "ARMED" 0 "UNARMED" ;
VAL_ 1298 TRCM_a037_eventFrontLeftSeatbelt 1 "LATCHED" 0 "UNLATCHED" ;
VAL_ 1298 TRCM_a037_eventFrontRightSeatbel 1 "LATCHED" 0 "UNLATCHED" ;
VAL_ 1298 TRCM_a037_eventDriverBrakeApply 3 "Faulty_SNA" 2 "Driver_applying_brakes" 1 "Not_Applied" 0 "NotInit_orOff" ;
VAL_ 1298 TRCM_a037_eventAccelPedalPos 255 "SNA" ;
VAL_ 1298 TRCM_a081_eventArmStatus 1 "ARMED" 0 "UNARMED" ;
VAL_ 1298 TRCM_a081_eventFrontLeftSeatbelt 1 "LATCHED" 0 "UNLATCHED" ;
VAL_ 1298 TRCM_a081_eventFrontRightSeatbel 1 "LATCHED" 0 "UNLATCHED" ;
VAL_ 1298 TRCM_a081_eventDriverBrakeApply 3 "Faulty_SNA" 2 "Driver_applying_brakes" 1 "Not_Applied" 0 "NotInit_orOff" ;
VAL_ 1298 TRCM_a081_eventAccelPedalPos 255 "SNA" ;
VAL_ 1298 TRCM_a400_resistance 255 "SNA" ;
VAL_ 1298 TRCM_a401_resistance 255 "SNA" ;
VAL_ 1298 TRCM_a402_resistance 255 "SNA" ;
VAL_ 1298 TRCM_a403_resistance 255 "SNA" ;
VAL_ 1298 TRCM_a404_resistance 255 "SNA" ;
VAL_ 1298 TRCM_a405_resistance 255 "SNA" ;
VAL_ 1298 TRCM_a406_resistance 255 "SNA" ;
VAL_ 1298 TRCM_a408_resistance 255 "SNA" ;
VAL_ 1298 TRCM_a409_resistance 255 "SNA" ;
VAL_ 1298 TRCM_a410_resistance 255 "SNA" ;
VAL_ 1298 TRCM_a411_resistance 255 "SNA" ;
VAL_ 1298 TRCM_a412_resistance 255 "SNA" ;
VAL_ 1298 TRCM_a413_resistance 255 "SNA" ;
VAL_ 1298 TRCM_a414_resistance 255 "SNA" ;
VAL_ 1298 TRCM_a415_resistance 255 "SNA" ;
VAL_ 1298 TRCM_a416_resistance 255 "SNA" ;
VAL_ 1298 TRCM_a417_resistance 255 "SNA" ;
VAL_ 1298 TRCM_a418_resistance 255 "SNA" ;
VAL_ 1298 TRCM_a419_resistance 255 "SNA" ;
VAL_ 1298 TRCM_a420_resistance 255 "SNA" ;
VAL_ 1298 TRCM_a421_resistance 255 "SNA" ;
VAL_ 1298 TRCM_a422_resistance 255 "SNA" ;
VAL_ 1298 TRCM_a423_resistance 255 "SNA" ;
